VERSION ""

NS_ :

BS_:

BU_: mLEDR mLEDL TLR TLL RLR RLL HLR HLL DASCU CGW BCM

BO_ 752 BCM_Lock_CTR: 7 CGW
 SG_ BCM_AlarmOFF_Stat : 46|1@1+ (1,0) [0|1] "" Vector__XXX
 SG_ BCM_MovementSensOFF_Stat : 47|1@1+ (1,0) [0|1] "" Vector__XXX
 SG_ BCM_WindowsOpen_Req : 55|1@1+ (1,0) [0|1] "" Vector__XXX
 SG_ BCM_WindowsClose_Cmd : 37|1@1+ (1,0) [0|1] "" Vector__XXX
 SG_ BCM_TrunkLatchRelease_Req : 7|1@1+ (1,0) [0|1] "" Vector__XXX
 SG_ BCM_RRDoorClose_Req : 35|2@1+ (1,0) [0|2] "" Vector__XXX
 SG_ BCM_HoodOpen_Stat : 40|2@1+ (1,0) [0|3] ""  DASCU
 SG_ PTG_MemorySetRequest : 21|2@1+ (1,0) [0|2] "" Vector__XXX
 SG_ BCM_DoorHandleLight_Req : 54|1@1+ (1,0) [0|1] "" Vector__XXX
 SG_ BCM_VehDoubleLock_Stat : 32|1@1+ (1,0) [0|1] "" Vector__XXX
 SG_ BCM_Alarm_Req : 49|1@1+ (1,0) [0|1] "" Vector__XXX
 SG_ BCM_Alarm_Reason : 50|4@1+ (1,0) [0|10] "" Vector__XXX
 SG_ VehicleLockStateReason : 0|4@1+ (1,0) [0|11] "" Vector__XXX
 SG_ BCM_FuelLidUnlock_Req : 33|1@1+ (1,0) [0|1] "" Vector__XXX
 SG_ BCM_FRDoorClose_Req : 38|2@1+ (1,0) [0|2] "" Vector__XXX
 SG_ BCM_HVlid_Stat : 34|1@1+ (1,0) [0|1] "" Vector__XXX
 SG_ VehicleLockState : 23|1@1+ (1,0) [0|1] ""  DASCU
 SG_ BCM_RLDoorClose_Req : 43|2@1+ (1,0) [0|2] "" Vector__XXX
 SG_ BCM_FrontLeftLockCmd : 4|3@1+ (1,0) [0|3] ""  DASCU
 SG_ PTG_MovementCmd : 11|2@1+ (1,0) [0|2] "" Vector__XXX
 SG_ BCM_RearWiperWipe_Req : 45|1@1+ (1,0) [0|1] "" Vector__XXX
 SG_ BCM_FrontRightLockCmd : 8|3@1+ (1,0) [0|3] ""  DASCU
 SG_ BCM_RearLeftLockCmd : 13|3@1+ (1,0) [0|4] ""  DASCU
 SG_ BCM_PanicAlertActive : 42|1@1+ (1,0) [0|1] "" Vector__XXX
 SG_ BCM_FLDoorClose_Req : 19|2@1+ (1,0) [0|2] "" Vector__XXX
 SG_ BCM_RearRightLockCmd : 16|3@1+ (1,0) [0|4] ""  DASCU
 SG_ BCM_DoorAjarState_RR : 30|2@1+ (1,0) [0|3] "" Vector__XXX
 SG_ BCM_DoorAjarState_RL : 28|2@1+ (1,0) [0|3] "" Vector__XXX
 SG_ BCM_DoorAjarState_FR : 26|2@1+ (1,0) [0|3] "" Vector__XXX
 SG_ BCM_DoorAjarState_FL : 24|2@1+ (1,0) [0|3] "" Vector__XXX
 SG_ BCM_DoorMovDis_Stat : 48|1@1+ (1,0) [0|1] "" Vector__XXX

BO_ 866 BCM_IC_Info_Msg: 8 CGW
 SG_ BCM_EngStartNotif_Stat : 2|1@1+ (1,0) [0|0] "" Vector__XXX
 SG_ BCM_SRoofManipulationWarn_Req : 55|1@1+ (1,0) [0|1] "" Vector__XXX
 SG_ BCM_RearRight_FogLight_Status : 13|1@1+ (1,0) [0|1] "" Vector__XXX
 SG_ BCM_RearLeft_FogLight_Status : 12|1@1+ (1,0) [0|1] "" Vector__XXX
 SG_ BCM_LvBat1_SOC_Pct : 40|7@1+ (1,0) [0|100] "%" Vector__XXX
 SG_ BCM_TrunkLidOpenWarn_Req : 47|1@1+ (1,0) [0|1] "" Vector__XXX
 SG_ BCM_FuelLvl_HMI : 48|7@1+ (1,0) [0|100] "%" Vector__XXX
 SG_ BCM_LvBatCharging_Stat : 1|1@1+ (1,0) [0|1] "" Vector__XXX
 SG_ BCM_TurnIndicatorRR_Status : 29|1@1+ (1,0) [0|1] "" Vector__XXX
 SG_ BCM_DaytimeLightRight_Status : 19|1@1+ (1,0) [0|1] "" Vector__XXX
 SG_ BCM_TurnIndicatorRL_Status : 28|1@1+ (1,0) [0|1] "" Vector__XXX
 SG_ BCM_LvBat1_SOH : 36|2@1+ (1,0) [0|2] "" Vector__XXX
 SG_ BCM_TurnIndicatorMR_Status : 27|1@1+ (1,0) [0|1] "" Vector__XXX
 SG_ BCM_WarningInd : 21|1@1+ (1,0) [0|1] "" Vector__XXX
 SG_ BCM_PosLightFR_status : 25|1@1+ (1,0) [0|1] "" Vector__XXX
 SG_ BCM_TurnIndicatorFL_Status : 30|1@1+ (1,0) [0|1] "" Vector__XXX
 SG_ BCM_ReverseLightsRight_Status : 11|1@1+ (1,0) [0|1] "" Vector__XXX
 SG_ BCM_PositionLight_RL_Status : 17|1@1+ (1,0) [0|1] "" Vector__XXX
 SG_ BCM_HeadLghtLevelinglFailure : 32|1@1+ (1,0) [0|1] "" Vector__XXX
 SG_ BCM_BrakeLightLeft_Status : 6|1@1+ (1,0) [0|1] "" Vector__XXX
 SG_ BCM_ReverseLightsLeft_Status : 14|1@1+ (1,0) [0|1] "" Vector__XXX
 SG_ BCM_AdaptiveLghtsFailure : 5|1@1+ (1,0) [0|1] "" Vector__XXX
 SG_ BCM_DisplayBcgrndIntensityRef : 56|8@1+ (0.394,0) [0|100.47] "%" Vector__XXX
 SG_ BCM_CorneringLightRight_Status : 22|1@1+ (1,0) [0|1] "" Vector__XXX
 SG_ BCM_LvBat1_SOC : 34|2@1+ (1,0) [0|3] "" Vector__XXX
 SG_ BCM_PowerSteeringCtrlFault : 33|1@1+ (1,0) [0|1] "" Vector__XXX
 SG_ BCM_CalSteeringWhColumnReq : 4|1@1+ (1,0) [0|1] "" Vector__XXX
 SG_ BCM_LowBeamLeft_Status : 9|1@1+ (1,0) [0|1] "" Vector__XXX
 SG_ BCM_BrakeLightRight_Status : 7|1@1+ (1,0) [0|1] "" Vector__XXX
 SG_ BCM_CorneringLightLeft_Status : 23|1@1+ (1,0) [0|1] "" Vector__XXX
 SG_ BCM_ExteriorSystemStatus : 39|1@1+ (1,0) [0|1] "" Vector__XXX
 SG_ BCM_TurnIndicatorML_Status : 26|1@1+ (1,0) [0|1] "" Vector__XXX
 SG_ BCM_LowBeamRight_Status : 10|1@1+ (1,0) [0|1] "" Vector__XXX
 SG_ BCM_TurnIndicatorFR_Status : 31|1@1+ (1,0) [0|1] "" Vector__XXX
 SG_ BCM_DaytimeLightLeft_Status : 20|1@1+ (1,0) [0|1] "" Vector__XXX
 SG_ BCM_AllWthrLght_Fault : 8|1@1+ (1,0) [0|1] "" Vector__XXX
 SG_ BCM_HighBeamAutoStatus : 38|1@1+ (1,0) [0|1] "" Vector__XXX
 SG_ BCM_HighBeamRight_Status : 16|1@1+ (1,0) [0|1] "" Vector__XXX
 SG_ BCM_HighBeamLeft_Status : 15|1@1+ (1,0) [0|1] "" Vector__XXX
 SG_ BCM_PosLightFL_status : 24|1@1+ (1,0) [0|1] "" Vector__XXX
 SG_ BCM_WasherFluidLevel : 0|1@1+ (1,0) [0|1] ""  DASCU
 SG_ BCM_PositionLight_RR_Status : 18|1@1+ (1,0) [0|1] "" Vector__XXX

BO_ 869 BCM_CLIMATIC_DATA: 6 CGW
 SG_ SolarSensLeftVal : 16|8@1+ (4.01575,0) [0|1024.01625] "W/qm"  DASCU
 SG_ RearWindowHeating_Status : 10|1@1+ (1,0) [0|1] "" Vector__XXX
 SG_ BCM_SideWindowType_Stat : 27|1@1+ (1,0) [0|1] "" Vector__XXX
 SG_ BCM_MirrorHeating_Cmd : 28|1@1+ (1,0) [0|1] "" Vector__XXX
 SG_ BCM_WindowWashingSt : 29|1@1+ (1,0) [0|1] "" Vector__XXX
 SG_ BCM_WipeLowTempWarn_Req : 8|1@1+ (1,0) [0|1] "" Vector__XXX
 SG_ RainDensity : 31|1@1+ (1,0) [0|1] ""  DASCU
 SG_ WindshieldTemp : 32|8@1+ (0.5,-40) [-40|87.5] "°C"  DASCU
 SG_ RainDetected : 15|1@1+ (1,0) [0|1] ""  DASCU
 SG_ BCM_RearWindowHeating_Cmd : 13|1@1+ (1,0) [0|1] "" Vector__XXX
 SG_ BCM_Wiper_Stat : 26|1@1+ (1,0) [0|1] ""  DASCU
 SG_ SolarSensRightVal : 0|8@1+ (4.01575,0) [0|1024.01625] "W/qm"  DASCU
 SG_ BCM_GloveBox_Stat : 30|1@1+ (1,0) [0|1] "" Vector__XXX
 SG_ WindshieldHumidity : 40|8@1+ (0.5,0) [0|100] "%"  DASCU
 SG_ FrontWindowHeating_Status : 9|1@1+ (1,0) [0|1] ""  DASCU
 SG_ SideWindowHeating_Status : 24|1@1+ (1,0) [0|1] "" Vector__XXX
 SG_ SWM_Heating_Req : 11|2@1+ (1,0) [0|3] "" Vector__XXX

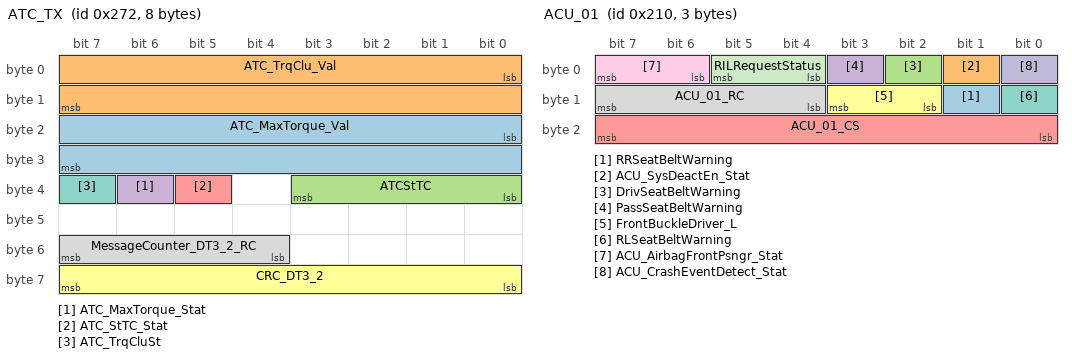
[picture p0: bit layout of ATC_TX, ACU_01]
BO_ 626 ATC_TX: 8 CGW
 SG_ ATC_MaxTorque_Val : 16|16@1+ (0.25,-8192) [-8192|8191] "Nm"  DASCU
 SG_ ATC_TrqClu_Val : 0|16@1+ (0.25,-8192) [-8192|8191] "Nm"  DASCU
 SG_ ATCStTC : 32|4@1+ (1,0) [0|15] ""  DASCU
 SG_ ATC_MaxTorque_Stat : 38|1@1+ (1,0) [0|1] "" Vector__XXX
 SG_ ATC_StTC_Stat : 37|1@1+ (1,0) [0|1] "" Vector__XXX
 SG_ CRC_DT3_2 : 56|8@1+ (1,0) [0|255] ""  DASCU
 SG_ ATC_TrqCluSt : 39|1@1+ (1,0) [0|1] ""  DASCU
 SG_ MessageCounter_DT3_2_RC : 52|4@1+ (1,0) [0|15] ""  DASCU

BO_ 1421 FIU_ADAS_Config: 8 CGW
 SG_ FIU_SettRDAAutoBrake_Req : 8|1@1+ (1,0) [0|1] ""  DASCU,CGW
 SG_ FIU_SettLCCMode_Req : 36|2@1+ (1,0) [0|3] ""  DASCU
 SG_ FIU_SettRDAsts_Req : 2|1@1+ (1,0) [0|1] ""  DASCU
 SG_ FIU_SettCCMode_Req : 26|2@1+ (1,0) [0|3] ""  DASCU
 SG_ FIU_SettSensCleanSts_Req : 55|1@1+ (1,0) [0|1] ""  DASCU
 SG_ FIU_SettLCCSoundAlert_Req : 19|1@1+ (1,0) [0|1] ""  DASCU
 SG_ FIU_SettAEBSts_Req : 14|1@1+ (1,0) [0|1] ""  DASCU
 SG_ FIU_SettDOWSts_Req : 21|1@1+ (1,0) [0|1] ""  DASCU
 SG_ FIU_SettAebFcwVibration_Req : 13|1@1+ (1,0) [0|1] ""  DASCU
 SG_ FIU_SettLDPSts_Req : 28|1@1+ (1,0) [0|1] ""  DASCU
 SG_ FIU_SettRecFileSize_Req : 40|2@1+ (1,0) [0|3] ""  DASCU
 SG_ FIU_SettLDWMode_Req : 34|2@1+ (1,0) [0|2] ""  DASCU
 SG_ FIU_SettRecResol_Req : 24|2@1+ (1,0) [0|2] ""  DASCU
 SG_ FIU_SettAebFcwMode_Req : 38|2@1+ (1,0) [0|3] ""  DASCU
 SG_ FIU_SettLDWVibration_Req : 16|1@1+ (1,0) [0|1] ""  DASCU
 SG_ FIU_SettRCTCsts_Req : 3|1@1+ (1,0) [0|1] ""  DASCU
 SG_ FIU_SettASLAOver_Req : 42|6@1+ (1,-1) [0|60] "Km/h"  DASCU
 SG_ FIU_SettCCType_Req : 52|3@1+ (1,0) [0|4] ""  DASCU
 SG_ FIU_SettALCCSts_Req : 20|1@1+ (1,0) [0|1] ""  DASCU
 SG_ FIU_SettDOWSoundAlert_Req : 22|1@1+ (1,0) [0|1] ""  DASCU
 SG_ FIU_SettRecSts_Req : 12|1@1+ (1,0) [0|1] ""  DASCU
 SG_ FIU_StartSet_Req : 0|1@1+ (1,0) [0|1] ""  DASCU
 SG_ FIU_SettLCCSts_Req : 15|1@1+ (1,0) [0|1] ""  DASCU
 SG_ FIU_SettAFSsts_Req : 31|1@1+ (1,0) [0|1] ""  DASCU
 SG_ FIU_SettAAmode_Req : 32|2@1+ (1,0) [0|2] ""  DASCU
 SG_ FIU_SettFCWSts_Req : 10|1@1+ (1,0) [0|1] ""  DASCU
 SG_ FIU_SettCCSpdCorrect_Req : 6|1@1+ (1,0) [0|1] ""  DASCU
 SG_ FIU_SettLKASts_Req : 9|1@1+ (1,0) [0|1] ""  DASCU
 SG_ FIU_SettLCCVibration_Req : 18|1@1+ (1,0) [0|1] ""  DASCU
 SG_ FIU_SettLDWSts_Req : 23|1@1+ (1,0) [0|1] ""  DASCU
 SG_ FIU_SettASLASts_Req : 7|1@1+ (1,0) [0|1] ""  DASCU
 SG_ FIU_SettAAsts_Req : 30|1@1+ (1,0) [0|1] ""  DASCU
 SG_ FIU_SettTSRsts_Req : 29|1@1+ (1,0) [0|1] ""  DASCU
 SG_ FIU_SettLDWSoundAlert_Req : 17|1@1+ (1,0) [0|1] ""  DASCU

BO_ 528 ACU_01: 3 CGW
 SG_ RRSeatBeltWarning : 9|1@1+ (1,0) [0|1] ""  DASCU
 SG_ ACU_SysDeactEn_Stat : 1|1@1+ (1,0) [0|1] "" Vector__XXX
 SG_ DrivSeatBeltWarning : 2|1@1+ (1,0) [0|1] ""  DASCU
 SG_ PassSeatBeltWarning : 3|1@1+ (1,0) [0|1] ""  DASCU
 SG_ ACU_01_CS : 16|8@1+ (1,0) [0|255] ""  DASCU
 SG_ FrontBuckleDriver_L : 10|2@1+ (1,0) [0|3] ""  DASCU
 SG_ RLSeatBeltWarning : 8|1@1+ (1,0) [0|1] ""  DASCU
 SG_ ACU_01_RC : 12|4@1+ (1,0) [0|15] ""  DASCU
 SG_ ACU_AirbagFrontPsngr_Stat : 6|2@1+ (1,0) [0|3] "" Vector__XXX
 SG_ ACU_CrashEventDetect_Stat : 0|1@1+ (1,0) [0|1] ""  DASCU
 SG_ RILRequestStatus : 4|2@1+ (1,0) [0|3] "" Vector__XXX

BO_ 256 ESC_04: 8 CGW
 SG_ ESC_CDPDecelActive : 24|1@1+ (1,0) [0|1] "" Vector__XXX
 SG_ ESC_BLS_Fault : 25|1@1+ (1,0) [0|1] "" Vector__XXX
 SG_ ESC_PEBWarningLampReq : 39|1@1+ (1,0) [0|1] "" Vector__XXX
 SG_ ESC_04_CS : 56|8@1+ (1,0) [0|255] ""  DASCU
 SG_ ESC_HDC_rejected : 34|1@1+ (1,0) [0|1] "" Vector__XXX
 SG_ ESC_CtlActiveTcs : 28|1@1+ (1,0) [0|1] ""  DASCU
 SG_ ESC_CtlActiveAbs : 26|1@1+ (1,0) [0|1] ""  DASCU
 SG_ ESC_Bls_Out : 19|1@1+ (1,0) [0|1] ""  DASCU
 SG_ ESC_HDC_Activated : 32|1@1+ (1,0) [0|1] ""  DASCU
 SG_ ESC_ABS_Lamp : 21|1@1+ (1,0) [0|1] "" Vector__XXX
 SG_ ESC_EBD_Lamp : 22|1@1+ (1,0) [0|1] "" Vector__XXX
 SG_ ESC_Lamp : 17|1@1+ (1,0) [0|1] "" Vector__XXX
 SG_ ESC_RequestToEPB : 36|2@1+ (1,0) [0|3] "" Vector__XXX
 SG_ ESC_TCS_Fault : 23|1@1+ (1,0) [0|1] "" Vector__XXX
 SG_ ESC_AVH_Active : 18|1@1+ (1,0) [0|1] "" Vector__XXX
 SG_ ESC_CDPDecelAvailable : 38|1@1+ (1,0) [0|1] "" Vector__XXX
 SG_ ESC_CtlActiveHDC : 33|1@1+ (1,0) [0|1] "" Vector__XXX
 SG_ ESC_CtlActiveEbd : 27|1@1+ (1,0) [0|1] ""  DASCU
 SG_ ESC_Passive_Lamp : 30|1@1+ (1,0) [0|1] "" Vector__XXX
 SG_ ESC_CtlActiveVdc : 29|1@1+ (1,0) [0|1] ""  DASCU
 SG_ ESC_EmergencyBraking : 35|1@1+ (1,0) [0|1] "" Vector__XXX
 SG_ ESC_VehicleSpeed_ValueError : 16|1@1+ (1,0) [0|1] ""  DASCU
 SG_ ESC_04_RC : 52|4@1+ (1,0) [0|15] ""  DASCU
 SG_ ESC_Bla : 20|1@1+ (1,0) [0|1] ""  DASCU
 SG_ ESC_VehicleSpeed : 0|16@1+ (0.01,0) [0|655.34] "km/h"  DASCU
 SG_ CddActive_2 : 48|1@1+ (1,0) [0|1] "" Vector__XXX
 SG_ ESC_Gearshift_Inhibit : 31|1@1+ (1,0) [0|1] "" Vector__XXX
 SG_ ESC_HDC_SpeedLimit : 40|8@1+ (1,0) [0|255] "km/h" Vector__XXX

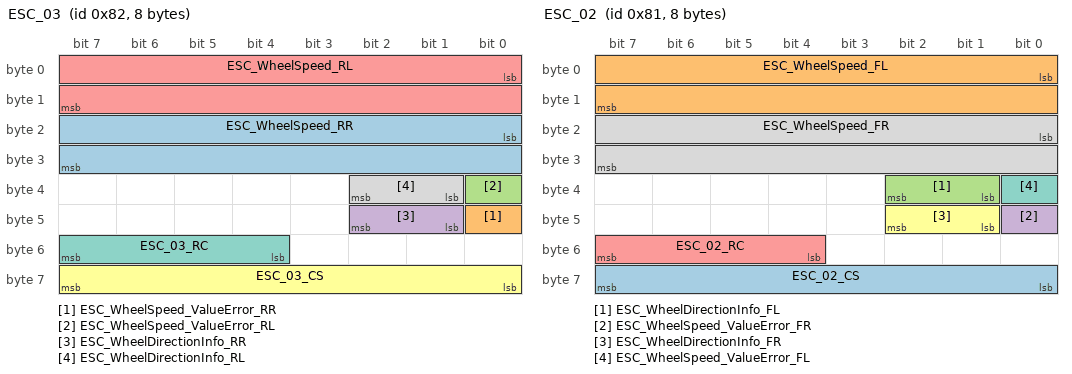
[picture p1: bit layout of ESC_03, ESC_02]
BO_ 130 ESC_03: 8 CGW
 SG_ ESC_WheelSpeed_RR : 16|16@1+ (0.01,0) [0|655.34] "km/h"  DASCU
 SG_ ESC_WheelSpeed_ValueError_RR : 40|1@1+ (1,0) [0|1] ""  DASCU
 SG_ ESC_WheelSpeed_ValueError_RL : 32|1@1+ (1,0) [0|1] ""  DASCU
 SG_ ESC_WheelDirectionInfo_RR : 41|2@1+ (1,0) [0|3] "" Vector__XXX
 SG_ ESC_WheelSpeed_RL : 0|16@1+ (0.01,0) [0|655.34] "km/h"  DASCU
 SG_ ESC_03_CS : 56|8@1+ (1,0) [0|255] ""  DASCU
 SG_ ESC_03_RC : 52|4@1+ (1,0) [0|15] ""  DASCU
 SG_ ESC_WheelDirectionInfo_RL : 33|2@1+ (1,0) [0|3] "" Vector__XXX

BO_ 129 ESC_02: 8 CGW
 SG_ ESC_02_CS : 56|8@1+ (1,0) [0|255] ""  DASCU
 SG_ ESC_WheelSpeed_FL : 0|16@1+ (0.01,0) [0|655.34] "km/h"  DASCU
 SG_ ESC_WheelDirectionInfo_FL : 33|2@1+ (1,0) [0|3] ""  DASCU
 SG_ ESC_WheelSpeed_ValueError_FR : 40|1@1+ (1,0) [0|1] ""  DASCU
 SG_ ESC_02_RC : 52|4@1+ (1,0) [0|15] ""  DASCU
 SG_ ESC_WheelDirectionInfo_FR : 41|2@1+ (1,0) [0|3] ""  DASCU
 SG_ ESC_WheelSpeed_ValueError_FL : 32|1@1+ (1,0) [0|1] ""  DASCU
 SG_ ESC_WheelSpeed_FR : 16|16@1+ (0.01,0) [0|655.34] "km/h"  DASCU

BO_ 2015 Diag_Functional: 8 CGW
 SG_ Diag_Functional_Sig : 7|64@0+ (1,0) [0|1.84467440737096E+019] ""  HLL,HLR,mLEDL,mLEDR,RLL,RLR,TLL,TLR,DASCU

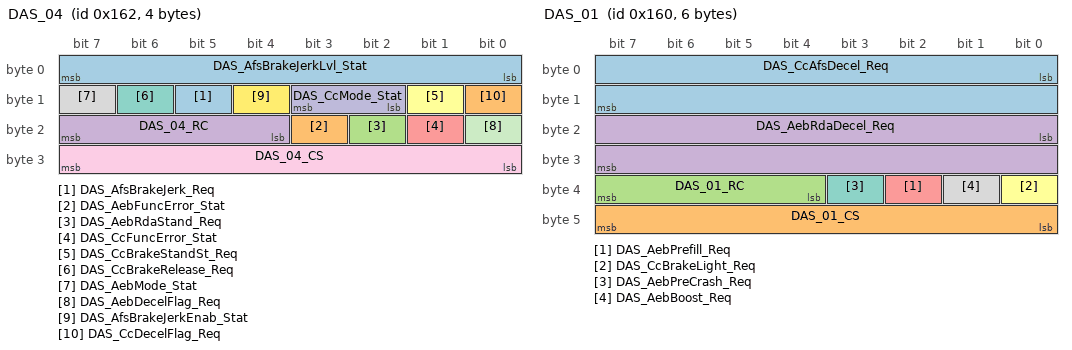
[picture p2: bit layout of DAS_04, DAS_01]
BO_ 354 DAS_04: 4 DASCU
 SG_ DAS_AfsBrakeJerk_Req : 13|1@1+ (1,0) [0|1] ""  CGW
 SG_ DAS_AebFuncError_Stat : 19|1@1+ (1,0) [0|1] ""  BCM,CGW
 SG_ DAS_AebRdaStand_Req : 18|1@1+ (1,0) [0|1] ""  CGW
 SG_ DAS_04_RC : 20|4@1+ (1,0) [0|15] ""  CGW
 SG_ DAS_CcFuncError_Stat : 17|1@1+ (1,0) [0|1] ""  CGW
 SG_ DAS_CcBrakeStandSt_Req : 9|1@1+ (1,0) [0|1] ""  CGW
 SG_ DAS_CcBrakeRelease_Req : 14|1@1+ (1,0) [0|1] ""  CGW
 SG_ DAS_AebMode_Stat : 15|1@1+ (1,0) [0|1] ""  CGW
 SG_ DAS_04_CS : 24|8@1+ (1,0) [0|255] ""  CGW
 SG_ DAS_CcMode_Stat : 10|2@1+ (1,0) [0|3] ""  BCM,CGW
 SG_ DAS_AebDecelFlag_Req : 16|1@1+ (1,0) [0|1] ""  CGW
 SG_ DAS_AfsBrakeJerkEnab_Stat : 12|1@1+ (1,0) [0|1] ""  CGW
 SG_ DAS_AfsBrakeJerkLvl_Stat : 0|8@1+ (1,0) [0|255] ""  CGW
 SG_ DAS_CcDecelFlag_Req : 8|1@1+ (1,0) [0|1] ""  CGW

BO_ 522 DAS_02: 8 DASCU
 SG_ DAS_LkaSteeringMode_Stat : 20|1@1+ (1,0) [0|1] ""  CGW
 SG_ DAS_RctcDecelFlag_Req : 23|1@1+ (1,0) [0|1] ""  CGW
 SG_ DAS_AccFuncError_Stat : 26|1@1+ (1,0) [0|1] ""  CGW
 SG_ DAS_RctcNotifError_Req : 25|1@1+ (1,0) [0|1] ""  CGW
 SG_ DAS_RctcFuncError_Stat : 24|1@1+ (1,0) [0|1] ""  CGW
 SG_ DAS_RctcMode_Stat : 22|1@1+ (1,0) [0|1] ""  CGW
 SG_ DAS_AfsNotifError_Req : 21|1@1+ (1,0) [0|1] ""  CGW
 SG_ DAS_ApaFuncError_Stat : 28|1@1+ (1,0) [0|1] "" Vector__XXX
 SG_ DAS_APAMode_Stat : 27|1@1+ (1,0) [0|1] "" Vector__XXX
 SG_ DAS_RsaAngleDirection_Req : 46|2@1+ (1,0) [0|3] "" Vector__XXX
 SG_ DAS_02_RC : 52|4@1+ (1,0) [0|15] ""  CGW
 SG_ DAS_LdpMode_Stat : 14|1@1+ (1,0) [0|1] ""  CGW
 SG_ DAS_02_CS : 56|8@1+ (1,0) [0|255] ""  CGW
 SG_ DAS_LkaAngleFlag_Req : 0|1@1+ (1,0) [0|1] ""  CGW
 SG_ DAS_AfsDecelFlag_Req : 2|1@1+ (1,0) [0|1] ""  CGW
 SG_ DAS_AlccMode_Stat : 17|1@1+ (1,0) [0|1] ""  CGW
 SG_ DAS_AfsFuncError_Stat : 3|1@1+ (1,0) [0|1] ""  CGW,BCM
 SG_ DAS_LdwFuncError_Stat : 15|1@1+ (1,0) [0|1] ""  CGW
 SG_ DAS_AfsSos_Req : 5|1@1+ (1,0) [0|1] ""  CGW
 SG_ DAS_LkaMode_Stat : 10|2@1+ (1,0) [0|3] ""  CGW
 SG_ DAS_RdaMode_Stat : 7|1@1+ (1,0) [0|1] ""  CGW
 SG_ DAS_AlccAngleFlag_Req : 16|1@1+ (1,0) [0|1] ""  CGW
 SG_ DAS_AfsEpb_Req : 6|1@1+ (1,0) [0|1] ""  CGW
 SG_ DAS_AfsMode_Stat : 1|1@1+ (1,0) [0|1] ""  CGW
 SG_ DAS_LkaAngle_Req : 32|14@1+ (0.1,-819.1) [-819.1|819.1] ""  CGW
 SG_ DAS_LccFuncError_Stat : 18|1@1+ (1,0) [0|1] ""  CGW
 SG_ DAS_RdaDecelFlag_Req : 8|1@1+ (1,0) [0|1] ""  CGW
 SG_ DAS_AfsExecute_Req : 4|1@1+ (1,0) [0|1] ""  CGW,BCM
 SG_ DAS_RdaFuncError_Stat : 9|1@1+ (1,0) [0|1] ""  CGW
 SG_ DAS_LkaFuncError_Stat : 12|1@1+ (1,0) [0|1] ""  CGW
 SG_ DAS_LdpAngleFlag_Req : 13|1@1+ (1,0) [0|1] ""  CGW
 SG_ DAS_ApaAngleFlag_Req : 19|1@1+ (1,0) [0|1] "" Vector__XXX

BO_ 352 DAS_01: 6 DASCU
 SG_ DAS_CcAfsDecel_Req : 0|16@1+ (0.001,-20) [-20|20] "m/s^2"  CGW
 SG_ DAS_01_CS : 40|8@1+ (1,0) [0|255] ""  BCM,CGW
 SG_ DAS_01_RC : 36|4@1+ (1,0) [0|15] ""  BCM,CGW
 SG_ DAS_AebRdaDecel_Req : 16|16@1+ (0.001,-20) [-20|20] "m/s^2"  CGW
 SG_ DAS_AebPrefill_Req : 34|1@1+ (1,0) [0|1] ""  CGW
 SG_ DAS_CcBrakeLight_Req : 32|1@1+ (1,0) [0|1] ""  BCM,CGW
 SG_ DAS_AebPreCrash_Req : 35|1@1+ (1,0) [0|1] ""  BCM,CGW
 SG_ DAS_AebBoost_Req : 33|1@1+ (1,0) [0|1] ""  CGW

BO_ 658 DASCU_Proj: 12 DASCU
 SG_ DAS_LeftProjBrightSlot1_Req : 16|3@1+ (1,0) [0|7] ""  mLEDL
 SG_ DAS_LeftProjSlot1_Req : 0|7@1+ (1,0) [0|101] ""  mLEDL
 SG_ DAS_LeftProjSlot4_Req : 43|4@1+ (1,0) [0|15] ""  mLEDL
 SG_ DAS_RightProjBrightSlot3_Req : 56|3@1+ (1,0) [0|7] ""  mLEDR
 SG_ DAS_RightProjSlot3_Req : 59|4@1+ (1,0) [0|15] ""  mLEDR
 SG_ DAS_RightProjBrightSlot4_Req : 64|3@1+ (1,0) [0|7] ""  mLEDR
 SG_ DAS_LeftProjBrightSlot3_Req : 32|3@1+ (1,0) [0|7] ""  mLEDL
 SG_ DAS_LeftProjBrightSlot2_Req : 24|3@1+ (1,0) [0|7] ""  mLEDL
 SG_ DAS_RightProjBrightSlot2_Req : 48|3@1+ (1,0) [0|7] ""  mLEDR
 SG_ DAS_LeftProjSlot3_Req : 35|4@1+ (1,0) [0|15] ""  mLEDL
 SG_ DAS_RightProjSlot1_Req : 8|7@1+ (1,0) [0|65] ""  mLEDR
 SG_ DAS_LeftProjSlot2_Req : 27|4@1+ (1,0) [0|15] ""  mLEDL
 SG_ DAS_LeftProjBrightSlot4_Req : 40|3@1+ (1,0) [0|7] ""  mLEDL
 SG_ DAS_RightProjSlot4_Req : 67|4@1+ (1,0) [0|15] ""  mLEDR
 SG_ DAS_RightProjBrightSlot1_Req : 19|3@1+ (1,0) [0|7] ""  mLEDR
 SG_ DAS_RightProjSlot2_Req : 51|4@1+ (1,0) [0|15] ""  mLEDR

BO_ 657 DASCU_HLR_Object: 64 DASCU
 SG_ DAS_RightObj_1_Y_2_Val : 40|9@1+ (1,0) [0|321] ""  mLEDR
 SG_ DAS_RightObj_3_Y_2_Val : 104|9@1+ (1,0) [0|321] ""  mLEDR
 SG_ DAS_ADBRightLED5_Req : 8|1@1+ (1,0) [0|1] ""  HLR
 SG_ DAS_ADBRightLED1_Req : 4|1@1+ (1,0) [0|1] ""  HLR
 SG_ DAS_RightObj_5_Z_2_Val : 177|7@1+ (1,0) [0|81] ""  mLEDR
 SG_ DAS_RightObj_7_Z_2_Val : 241|7@1+ (1,0) [0|81] ""  mLEDR
 SG_ DAS_RightObj_9_Z_2_Val : 305|7@1+ (1,0) [0|81] ""  mLEDR
 SG_ DAS_RightObj_8_Y_1_Val : 248|9@1+ (1,0) [0|321] ""  mLEDR
 SG_ DAS_ADBRightLED6_Req : 9|1@1+ (1,0) [0|1] ""  HLR
 SG_ DAS_RightObj_9_Y_2_Val : 296|9@1+ (1,0) [0|321] ""  mLEDR
 SG_ DAS_ADBRightLED10_Req : 13|1@1+ (1,0) [0|1] ""  HLR
 SG_ DAS_ADBRightLED16_Req : 19|1@1+ (1,0) [0|1] ""  HLR
 SG_ DAS_ADBRightLED11_Req : 14|1@1+ (1,0) [0|1] ""  HLR
 SG_ DAS_RightObj_10_Y_2_Val : 328|9@1+ (1,0) [0|321] ""  mLEDR
 SG_ DAS_RightObj_10_Z_2_Val : 337|7@1+ (1,0) [0|81] ""  mLEDR
 SG_ DAS_RightObj_3_Z_2_Val : 113|7@1+ (1,0) [0|81] ""  mLEDR
 SG_ DAS_RightObj_4_Y_1_Val : 120|9@1+ (1,0) [0|321] ""  mLEDR
 SG_ DAS_RightObj_8_Z_1_Val : 257|7@1+ (1,0) [0|81] ""  mLEDR
 SG_ DAS_RightObj_6_Z_2_Val : 209|7@1+ (1,0) [0|81] ""  mLEDR
 SG_ DAS_ADBRightLED12_Req : 15|1@1+ (1,0) [0|1] ""  HLR
 SG_ DAS_HLR_Object_CS : 384|8@1+ (1,0) [0|255] ""  HLR,mLEDR
 SG_ DAS_ADBRightLED15_Req : 18|1@1+ (1,0) [0|1] ""  HLR
 SG_ DAS_RightObj_3_Z_1_Val : 97|7@1+ (1,0) [0|81] ""  mLEDR
 SG_ DAS_ADBRightLED8_Req : 11|1@1+ (1,0) [0|1] ""  HLR
 SG_ DAS_HLR_Object_RC : 379|4@1+ (1,0) [0|15] ""  HLR,mLEDR
 SG_ DAS_RightObj_7_Y_2_Val : 232|9@1+ (1,0) [0|321] ""  mLEDR
 SG_ DAS_RightObj_9_Y_1_Val : 280|9@1+ (1,0) [0|321] ""  mLEDR
 SG_ DAS_RightObj_4_Y_2_Val : 136|9@1+ (1,0) [0|321] ""  mLEDR
 SG_ DAS_RightObj_2_Z_1_Val : 65|7@1+ (1,0) [0|81] ""  mLEDR
 SG_ DAS_RightObj_7_Z_1_Val : 225|7@1+ (1,0) [0|81] ""  mLEDR
 SG_ DAS_RightObj_9_Z_1_Val : 289|7@1+ (1,0) [0|81] ""  mLEDR
 SG_ DAS_RightObj_5_Y_1_Val : 152|9@1+ (1,0) [0|321] ""  mLEDR
 SG_ DAS_RightObj_10_Z_1_Val : 321|7@1+ (1,0) [0|81] ""  mLEDR
 SG_ DAS_RightObj_8_Y_2_Val : 264|9@1+ (1,0) [0|321] ""  mLEDR
 SG_ DAS_ADBRightLED4_Req : 7|1@1+ (1,0) [0|1] ""  HLR
 SG_ DAS_RightObj_4_Z_2_Val : 145|7@1+ (1,0) [0|81] ""  mLEDR
 SG_ DAS_RightObj_6_Y_1_Val : 184|9@1+ (1,0) [0|321] ""  mLEDR
 SG_ DAS_ADBRightLED13_Req : 16|1@1+ (1,0) [0|1] ""  HLR
 SG_ DAS_RightObj_1_Y_1_Val : 24|9@1+ (1,0) [0|321] ""  mLEDR
 SG_ DAS_ADBRightLED17_Req : 20|1@1+ (1,0) [0|1] ""  HLR
 SG_ DAS_ADBRightLED9_Req : 12|1@1+ (1,0) [0|1] ""  HLR
 SG_ DAS_RightObj_6_Z_1_Val : 193|7@1+ (1,0) [0|81] ""  mLEDR
 SG_ DAS_RightObj_4_Z_1_Val : 129|7@1+ (1,0) [0|81] ""  mLEDR
 SG_ DAS_ADBRightLED18_Req : 21|1@1+ (1,0) [0|1] ""  HLR
 SG_ DAS_RightObj_1_Z_1_Val : 33|7@1+ (1,0) [0|81] ""  mLEDR
 SG_ DAS_ADBRightLED7_Req : 10|1@1+ (1,0) [0|1] ""  HLR
 SG_ DAS_RightObj_8_Z_2_Val : 273|7@1+ (1,0) [0|81] ""  mLEDR
 SG_ DAS_RightObj_2_Z_2_Val : 81|7@1+ (1,0) [0|81] ""  mLEDR
 SG_ DAS_RightObj_3_Y_1_Val : 88|9@1+ (1,0) [0|321] ""  mLEDR
 SG_ DAS_ADBRightLED3_Req : 6|1@1+ (1,0) [0|1] ""  HLR
 SG_ DAS_RightObj_6_Y_2_Val : 200|9@1+ (1,0) [0|321] ""  mLEDR
 SG_ DAS_RightObj_5_Z_1_Val : 161|7@1+ (1,0) [0|81] ""  mLEDR
 SG_ DAS_RightObj_5_Y_2_Val : 168|9@1+ (1,0) [0|321] ""  mLEDR
 SG_ DAS_ADBRightLED2_Req : 5|1@1+ (1,0) [0|1] ""  HLR
 SG_ DAS_ADBRightLED14_Req : 17|1@1+ (1,0) [0|1] ""  HLR
 SG_ DAS_RightObj_2_Y_1_Val : 56|9@1+ (1,0) [0|321] ""  mLEDR
 SG_ DAS_RightObj_10_Y_1_Val : 312|9@1+ (1,0) [0|321] ""  mLEDR
 SG_ DAS_RightObj_1_Z_2_Val : 49|7@1+ (1,0) [0|81] ""  mLEDR
 SG_ DAS_RightObj_2_Y_2_Val : 72|9@1+ (1,0) [0|321] ""  mLEDR
 SG_ DAS_RightObj_7_Y_1_Val : 216|9@1+ (1,0) [0|321] ""  mLEDR

CM_ SG_ 752 BCM_AlarmOFF_Stat "Disabling alarm system";
CM_ SG_ 752 BCM_MovementSensOFF_Stat "State of movement sensor actvation";
CM_ SG_ 752 BCM_WindowsOpen_Req "The BCM shall command to Open the windows, when user request is detect.";
CM_ SG_ 752 BCM_WindowsClose_Cmd "The BCM shall command to Close  the windows, when user request is detect.";
CM_ SG_ 752 BCM_TrunkLatchRelease_Req "Indicates whether the trunk latch is commanded to be released or not";
CM_ SG_ 752 BCM_RRDoorClose_Req "Command to control RR door opening/ closing";
CM_ SG_ 752 BCM_HoodOpen_Stat "Current status of hood";
CM_ SG_ 752 PTG_MemorySetRequest "Request of storing or clearing the power tailgate position in memory:
$0 = No Action
$1 = Store memory
$2 = Clear memory";
CM_ SG_ 752 BCM_DoorHandleLight_Req "Command to control exterior door handle lights";
CM_ SG_ 752 BCM_VehDoubleLock_Stat "Vehicle secure locking status";
CM_ SG_ 752 BCM_Alarm_Req "Indicates if at least one alarm reason active or not";
CM_ SG_ 752 BCM_Alarm_Reason "Reason of vehicle alarm function actuation";
CM_ SG_ 752 VehicleLockStateReason "Reason of vehicle lock state";
CM_ SG_ 752 BCM_FuelLidUnlock_Req "Fuel (gasoline or hydrogen) and high-voltage lid unlock command";
CM_ SG_ 752 BCM_FRDoorClose_Req "Current command to control movement of FR door ";
CM_ SG_ 752 BCM_HVlid_Stat "HV lid open status";
CM_ SG_ 752 VehicleLockState "State of vehicle side doors and trunk locks: locked or unlocked";
CM_ SG_ 752 BCM_RLDoorClose_Req "Command to control RL door opening/ closing";
CM_ SG_ 752 BCM_FrontLeftLockCmd "$0 = NO_ACTION
$1 = UNLOCK
$2 = LOCK
$3 = SECURE_LOCK
$4 = UNSECURE_LOCK";
CM_ SG_ 752 PTG_MovementCmd "Indicates the power tailgate movement command:
0x0 = Stop
0x1 = Open
0x2 = Close";
CM_ SG_ 752 BCM_RearWiperWipe_Req "Indicate a rear wiper wipe request";
CM_ SG_ 752 BCM_FrontRightLockCmd "$0 = NO_ACTION
$1 = UNLOCK
$2 = LOCK
$3 = SECURE_LOCK
$4 = UNSECURE_LOCK";
CM_ SG_ 752 BCM_RearLeftLockCmd "$0 = NO_ACTION
$1 = UNLOCK
$2 = LOCK
$3 = SECURE_LOCK
$4 = UNSECURE_LOCK";
CM_ SG_ 752 BCM_PanicAlertActive "State of Panic Mode activation";
CM_ SG_ 752 BCM_FLDoorClose_Req "Current command to control movement of FL door ";
CM_ SG_ 752 BCM_RearRightLockCmd "$0 = NO_ACTION
$1 = UNLOCK
$2 = LOCK
$3 = SECURE_LOCK
$4 = UNSECURE_LOCK";
CM_ SG_ 752 BCM_DoorAjarState_RR "State of RR door (legacy signal";
CM_ SG_ 752 BCM_DoorAjarState_RL "State of RL door (legacy signal)";
CM_ SG_ 752 BCM_DoorAjarState_FR "The signal only for active safety system";
CM_ SG_ 752 BCM_DoorAjarState_FL "State of FL door Only for ESC.";
CM_ SG_ 752 BCM_DoorMovDis_Stat "Door movement system status";
CM_ SG_ 866 BCM_EngStartNotif_Stat "User notification to smoothly transit from “engine running in remote start” mode to “Drive” mode";
CM_ SG_ 866 BCM_SRoofManipulationWarn_Req "Indicates to user inability of open trunk lid due to soft roof control";
CM_ SG_ 866 BCM_RearRight_FogLight_Status "Error status of rear right fog light";
CM_ SG_ 866 BCM_RearLeft_FogLight_Status "Error status of rear left fog light";
CM_ SG_ 866 BCM_LvBat1_SOC_Pct "SOC of LV battery in percents";
CM_ SG_ 866 BCM_TrunkLidOpenWarn_Req "Indicates to user inability of soft roof control due to trunk lid open";
CM_ SG_ 866 BCM_FuelLvl_HMI "Fuel Level in percents";
CM_ SG_ 866 BCM_LvBatCharging_Stat "State of charging a Low Voltage Battery";
CM_ SG_ 866 BCM_TurnIndicatorRR_Status "Error status of rear right direction indicator";
CM_ SG_ 866 BCM_DaytimeLightRight_Status "Current status  of daytime running lights / position lights";
CM_ SG_ 866 BCM_TurnIndicatorRL_Status "Error status of rear left direction indicator";
CM_ SG_ 866 BCM_LvBat1_SOH "State of Health main Low Battery Voltage";
CM_ SG_ 866 BCM_TurnIndicatorMR_Status "Error status of side right direction indicator";
CM_ SG_ 866 BCM_WarningInd "Request a warning message to be displayed on IC:
$0 = No Warning
$1 = Warning requested";
CM_ SG_ 866 BCM_PosLightFR_status "Error status of front right position light";
CM_ SG_ 866 BCM_TurnIndicatorFL_Status "Error status of front left direction indicator";
CM_ SG_ 866 BCM_ReverseLightsRight_Status "Current status of reverse lights";
CM_ SG_ 866 BCM_PositionLight_RL_Status "Error status of rear left position light";
CM_ SG_ 866 BCM_HeadLghtLevelinglFailure "Indicate to the driver that the leveling system has failed
$0 = FALSE
$1 = TRUE";
CM_ SG_ 866 BCM_BrakeLightLeft_Status "Current status of brake lights";
CM_ SG_ 866 BCM_ReverseLightsLeft_Status "Current status of reverse lights";
CM_ SG_ 866 BCM_AdaptiveLghtsFailure "The failure in exterior lights,which changes the light beam when turning.";
CM_ SG_ 866 BCM_DisplayBcgrndIntensityRef "Indicates to IC the background intensity for display selected by the user.
IC receives it, processes based on a table and a light sensor then sends to FIU the DisplayBacllightBrightness applied.";
CM_ SG_ 866 BCM_CorneringLightRight_Status "Current status of cornering lights";
CM_ SG_ 866 BCM_LvBat1_SOC "State of Charge main Low Battery Voltage";
CM_ SG_ 866 BCM_PowerSteeringCtrlFault "Request the power steering fluid control fault indication:
$0 = No Action
$1 = Stering Fluid Control Fault";
CM_ SG_ 866 BCM_CalSteeringWhColumnReq "Request to notify user about steering whell calibration";
CM_ SG_ 866 BCM_LowBeamLeft_Status "Current status of low-beam lights";
CM_ SG_ 866 BCM_BrakeLightRight_Status "Current status of brake lights";
CM_ SG_ 866 BCM_CorneringLightLeft_Status "Current status of cornering lights";
CM_ SG_ 866 BCM_ExteriorSystemStatus "General failure of exterior light system";
CM_ SG_ 866 BCM_TurnIndicatorML_Status "Error status of side left direction indicator";
CM_ SG_ 866 BCM_LowBeamRight_Status "Current status of low-beam lights";
CM_ SG_ 866 BCM_TurnIndicatorFR_Status "Error status of front right direction indicator";
CM_ SG_ 866 BCM_DaytimeLightLeft_Status "Current status  of daytime running lights / position lights";
CM_ SG_ 866 BCM_AllWthrLght_Fault "Error status of all-weather function";
CM_ SG_ 866 BCM_HighBeamAutoStatus "State of availability auto high beam function";
CM_ SG_ 866 BCM_HighBeamRight_Status "Current status of high-beam lights";
CM_ SG_ 866 BCM_HighBeamLeft_Status "Current status of high-beam lights";
CM_ SG_ 866 BCM_PosLightFL_status "Error status of front left position light";
CM_ SG_ 866 BCM_WasherFluidLevel "Washer Fluid Level";
CM_ SG_ 866 BCM_PositionLight_RR_Status "Error status of rear right position light";
CM_ SG_ 869 SolarSensLeftVal "Solar radiation value from left sensor";
CM_ SG_ 869 RearWindowHeating_Status "State of rear window heating";
CM_ SG_ 869 BCM_SideWindowType_Stat "Indicates side window heaters installed on vehicle or not";
CM_ SG_ 869 BCM_MirrorHeating_Cmd "Request to on/off outside miror heating";
CM_ SG_ 869 BCM_WindowWashingSt "Indicates the window washer status";
CM_ SG_ 869 BCM_WipeLowTempWarn_Req "Indicates to driver: front wiper pause due to low external temperature";
CM_ SG_ 869 RainDensity "Indicates the density of rainstatus:
0x0 = Low Density
0x1 = High Density";
CM_ SG_ 869 WindshieldTemp "Temperature of front windshield zone";
CM_ SG_ 869 RainDetected "Indicates the rain detected or not";
CM_ SG_ 869 BCM_RearWindowHeating_Cmd "Request to on/off rear window heating";
CM_ SG_ 869 BCM_Wiper_Stat "Wiper status
Indicates the wiper status";
CM_ SG_ 869 SolarSensRightVal "Solar radiation value from right sensor";
CM_ SG_ 869 BCM_GloveBox_Stat "Current state of glove box (open or closed)";
CM_ SG_ 869 WindshieldHumidity "Level of humidity in front windshield zone";
CM_ SG_ 869 FrontWindowHeating_Status "State of front window heating";
CM_ SG_ 869 SideWindowHeating_Status "State of side windows heating";
CM_ SG_ 869 SWM_Heating_Req "Request to on/ off steering wheel heating";
CM_ SG_ 626 ATC_MaxTorque_Val "Maximum possible clutch torque at the center";
CM_ SG_ 626 ATC_TrqClu_Val "actual (current) coupling clutch torque at the center";
CM_ SG_ 626 ATCStTC "Clutch Status / AWD system status/Transfer case status:
0 Deactivated / DEACT (0Nm)
1 Initialization / INIT (value at ignition ON? Clutch torque 0)
2 calibration / CAL (This condition doesnt happen in vehicle running condition.)
3 normal operation / N";
CM_ SG_ 626 ATC_MaxTorque_Stat "maximum available clutch torque signal validity
$0 = Invalid signal
$1 = Valid signal";
CM_ SG_ 626 ATC_StTC_Stat "Clutch Status/ AWD system status signal validity
$0 = Invalid signal
$1 = Valid signal";
CM_ SG_ 626 CRC_DT3_2 "Checksum CRC8 SAE J1850 of the data field this message";
CM_ SG_ 626 ATC_TrqCluSt "actual clutch torque signal validity
$0 = Invalid signal
$1 = Valid signal";
CM_ SG_ 626 MessageCounter_DT3_2_RC "Rolling Counter [0 - 15]";
CM_ SG_ 1421 FIU_SettRDAAutoBrake_Req "Rear driving assistant state change request Auto Brake";
CM_ SG_ 1421 FIU_SettLCCMode_Req "Lane change control state change request";
CM_ SG_ 1421 FIU_SettRDAsts_Req "Rear driving assistant state change request";
CM_ SG_ 1421 FIU_SettCCMode_Req "Cruise control mode change request";
CM_ SG_ 1421 FIU_SettSensCleanSts_Req "Request status of sensor clean function";
CM_ SG_ 1421 FIU_SettLCCSoundAlert_Req "Lane change control sound alert function eneble/ disable change request";
CM_ SG_ 1421 FIU_SettAEBSts_Req "Automatic emergency braking state change request. Only for PHEV, BEV, PFCV";
CM_ SG_ 1421 FIU_SettDOWSts_Req "Door opening warning state change request";
CM_ SG_ 1421 FIU_SettAebFcwVibration_Req "Front collision warning tactile sensation function enable/ disable change request";
CM_ SG_ 1421 FIU_SettLDPSts_Req "Line departure prevention state change request";
CM_ SG_ 1421 FIU_SettRecFileSize_Req "RSR activation status";
CM_ SG_ 1421 FIU_SettLDWMode_Req "Line departure warning mode change request";
CM_ SG_ 1421 FIU_SettRecResol_Req "REC resolution of video-file";
CM_ SG_ 1421 FIU_SettAebFcwMode_Req "Front collision warning mode change request";
CM_ SG_ 1421 FIU_SettLDWVibration_Req "Line departure warning tactile sensation function eneble/ disable change request";
CM_ SG_ 1421 FIU_SettRCTCsts_Req "Rear control trafic collision state change request";
CM_ SG_ 1421 FIU_SettASLAOver_Req "Over threshold speed request";
CM_ SG_ 1421 FIU_SettCCType_Req "Cruise control type change request";
CM_ SG_ 1421 FIU_SettALCCSts_Req "Active line change contol state change request";
CM_ SG_ 1421 FIU_SettDOWSoundAlert_Req "Door opening warning sound alert function eneble/ disable change request";
CM_ SG_ 1421 FIU_SettRecSts_Req "REC activation status";
CM_ SG_ 1421 FIU_StartSet_Req "Start send setting request";
CM_ SG_ 1421 FIU_SettLCCSts_Req "Lane change control state change request";
CM_ SG_ 1421 FIU_SettAFSsts_Req "Automatic forced stop change request";
CM_ SG_ 1421 FIU_SettAAmode_Req "Attention assist mode change request";
CM_ SG_ 1421 FIU_SettFCWSts_Req "Forward collision warning state change request. Only for HEV";
CM_ SG_ 1421 FIU_SettCCSpdCorrect_Req "Request change of speed in a turn";
CM_ SG_ 1421 FIU_SettLKASts_Req "Line keep assistant state change request";
CM_ SG_ 1421 FIU_SettLCCVibration_Req "Lane change control tactile sensation function eneble/ disable change request";
CM_ SG_ 1421 FIU_SettLDWSts_Req "Line departure warning state change request";
CM_ SG_ 1421 FIU_SettASLASts_Req "Active speed limiter state change request";
CM_ SG_ 1421 FIU_SettAAsts_Req "Attention assist state change request";
CM_ SG_ 1421 FIU_SettTSRsts_Req "Traffic sign recognition state change request";
CM_ SG_ 1421 FIU_SettLDWSoundAlert_Req "Line departure warning sound alert function eneble/ disable change request";
CM_ SG_ 528 RRSeatBeltWarning "When the bit is set to a '1', a warning is required due to rear right seat belt not detected buckled.";
CM_ SG_ 528 ACU_SysDeactEn_Stat "Indicates when the complet airbags deactivation is requested:
$0 = Disable Complete airbags deactivation
$1 = Enable Complete airbags deactivation";
CM_ SG_ 528 DrivSeatBeltWarning "When the bit is set to a '1', a warning is required due to driver seat belt not detected buckled.";
CM_ SG_ 528 PassSeatBeltWarning "When the bit is set to a '1', a warning is required due to passenger seat belt not detected buckled.";
CM_ SG_ 528 ACU_01_CS "Checksum XOR8 of the data field this message
Checksum computed as per XOR algorithm:
Byte 1 XOR byte 2 .... XOR byte n-1. (n = packet length.)";
CM_ SG_ 528 FrontBuckleDriver_L "Indicates belt status & Buckle status

Bit 0: 0 = Belt status: unbelted
Bit 0: 1 = Belt status: belted
Bit 1: 0 = Buckle status: normal operation
Bit 1: 1 = Buckle status: faulty";
CM_ SG_ 528 RLSeatBeltWarning "When the bit is set to a '1', a warning is required due to rear left seat belt not detected buckled.";
CM_ SG_ 528 ACU_01_RC "Rolling Counter [0 - 15]";
CM_ SG_ 528 ACU_AirbagFrontPsngr_Stat "Indicates the activation status of the front passenger airbag
$0 = Active, Lamp OFF
$1 = Reserved
$2 = Inactive, Lamp ON";
CM_ SG_ 528 ACU_CrashEventDetect_Stat "The signal is generated when an accident-related event (Crash) occurs when at least one of several accident detection algorithms (Front crash detection, Rear crash detection or Side crash detection) is performed.";
CM_ SG_ 528 RILRequestStatus "Indicates the state of the SRS Warning Lamp in the Instrument Cluster:
$0 = RIL Request OFF: No fault
$1 = Reserved
$2 = RIL Blinking Request: Deployment algorithm deactivated (because of either Remote Start state or system deactivation switch)
$3 = R";
CM_ SG_ 256 ESC_CDPDecelActive "Indicates that deceleration request from EPB is executed
$0 = Not Active
$1 = Active";
CM_ SG_ 256 ESC_BLS_Fault "Brake Light Switch fault indication.";
CM_ SG_ 256 ESC_PEBWarningLampReq "Activate animation in IC to inform user that the vehicle was braked in both of the following cases:
- Automatic emergency braking activation without driver braking
- Automatic emergency braking activation with driver brake assist";
CM_ SG_ 256 ESC_04_CS "Checksum CRC8 SAE J1850 of the data field this message";
CM_ SG_ 256 ESC_HDC_rejected "HDC activation rejected, if driver presses HDC switch in wrong driving mode.";
CM_ SG_ 256 ESC_CtlActiveTcs "Indicates activity of TCS control";
CM_ SG_ 256 ESC_CtlActiveAbs "Indicates activity of ABS control";
CM_ SG_ 256 ESC_Bls_Out "Brake Light Switch. Indicates brake pedal pressing status (derived from brake light switch and brake switch)";
CM_ SG_ 256 ESC_HDC_Activated "Indicates that driver has activated HDC function using the HDC switch. (not controller status)";
CM_ SG_ 256 ESC_ABS_Lamp "ABS lamp control signal for HMI and ABS function fault indication";
CM_ SG_ 256 ESC_EBD_Lamp "EBD function or booster fault indication for BK-Lamp control.";
CM_ SG_ 256 ESC_Lamp "ESC lamp control signal for HMI.";
CM_ SG_ 256 ESC_RequestToEPB "ESC request to open or close the park brake
$0 = Not Initialized
$1 = No Request
$2 = Release Brake
$3 = Lock Brake";
CM_ SG_ 256 ESC_TCS_Fault "TCS function fault indication";
CM_ SG_ 256 ESC_AVH_Active "Feedback to EPB that indicates hydraulic holding
$0 = Not Active
$1 = Active";
CM_ SG_ 256 ESC_CDPDecelAvailable "Indicates that CDP is available for decelerating the vehicle
$0 = Not Available
$1 = Available";
CM_ SG_ 256 ESC_CtlActiveHDC "HDC controller activity indication";
CM_ SG_ 256 ESC_CtlActiveEbd "Indicates activity of EBD control";
CM_ SG_ 256 ESC_Passive_Lamp "Control signal to HMI to control passive lamp. (degraded state of ESC CU functions)";
CM_ SG_ 256 ESC_CtlActiveVdc "Indicates activity of VDC control (VDC= ESC function to stabilize the vehicle; not the differential function)";
CM_ SG_ 256 ESC_EmergencyBraking "Emergency braking function status";
CM_ SG_ 256 ESC_VehicleSpeed_ValueError "Indicates if the signal vehicleSpeed has valid value";
CM_ SG_ 256 ESC_04_RC "Rolling Counter [0 - 15]";
CM_ SG_ 256 ESC_Bla "Brake Light Activation. Indicates braking via driver or via other functions.";
CM_ SG_ 256 ESC_VehicleSpeed "Calculated vehicle speed value";
CM_ SG_ 256 CddActive_2 "Indicates cdd control active (Controlled Deceleration for Driver Assistant Systems)
$0 = Inactive
$1 = Active
(CddActive duplicata)";
CM_ SG_ 256 ESC_Gearshift_Inhibit "During critical activity in ESC control unit, request to gearbox control unit to inhibit gear shifting.";
CM_ SG_ 256 ESC_HDC_SpeedLimit "Indicates the current speed limitation due to a Hill Descent Assist phase";
CM_ SG_ 130 ESC_WheelSpeed_RR "Wheel speed of rear right wheel";
CM_ SG_ 130 ESC_WheelSpeed_ValueError_RR "Indicates if the signal WheelSpeed_RR has valid value";
CM_ SG_ 130 ESC_WheelSpeed_ValueError_RL "Indicates if the signal WheelSpeed_RL has valid value";
CM_ SG_ 130 ESC_WheelDirectionInfo_RR "Direction/stillstand info for rear right wheel";
CM_ SG_ 130 ESC_WheelSpeed_RL "Wheel speed of rear left wheel";
CM_ SG_ 130 ESC_03_CS "Checksum CRC8 SAE J1850 of the data field this message";
CM_ SG_ 130 ESC_03_RC "Rolling Counter [0 - 15]";
CM_ SG_ 130 ESC_WheelDirectionInfo_RL "Direction/stillstand info for rear left wheel";
CM_ SG_ 129 ESC_02_CS "Checksum CRC8 SAE J1850 of the data field this message";
CM_ SG_ 129 ESC_WheelSpeed_FL "Wheel speed of front left wheel";
CM_ SG_ 129 ESC_WheelDirectionInfo_FL "Direction/stillstand info for front left wheel";
CM_ SG_ 129 ESC_WheelSpeed_ValueError_FR "Indicates if the signal WheelSpeed_FR has valid value";
CM_ SG_ 129 ESC_02_RC "Rolling Counter [0 - 15]";
CM_ SG_ 129 ESC_WheelDirectionInfo_FR "Direction/stillstand info for front right wheel";
CM_ SG_ 129 ESC_WheelSpeed_ValueError_FL "Indicates if the signal WheelSpeed_FL has valid value";
CM_ SG_ 129 ESC_WheelSpeed_FR "Wheel speed of front right wheel";
CM_ BO_ 2015 "Diagnostic Message";
CM_ SG_ 2015 Diag_Functional_Sig "Diagnostic signal";
CM_ SG_ 354 DAS_AfsBrakeJerk_Req "AFS requests a brake jerk to warn the driver in a hazardous situation";
CM_ SG_ 354 DAS_AebFuncError_Stat "Error symbol of AEB";
CM_ SG_ 354 DAS_AebRdaStand_Req "AEB or RDA is requestin enable HOLD";
CM_ SG_ 354 DAS_04_RC "Rolling Counter [0 - 15]";
CM_ SG_ 354 DAS_CcFuncError_Stat "Error symbol of CC";
CM_ SG_ 354 DAS_CcBrakeStandSt_Req "Cruise is requesting a car hold";
CM_ SG_ 354 DAS_CcBrakeRelease_Req "Cruise is requesting to start the car";
CM_ SG_ 354 DAS_AebMode_Stat "Mode of emergency braking";
CM_ SG_ 354 DAS_04_CS "Checksum CRC8 SAE J1850 of the data field this message";
CM_ SG_ 354 DAS_CcMode_Stat "Mode of CC";
CM_ SG_ 354 DAS_AebDecelFlag_Req "AEB is requesting to implement deceleration";
CM_ SG_ 354 DAS_AfsBrakeJerkEnab_Stat "Enable the brake jerk warning functionnality";
CM_ SG_ 354 DAS_AfsBrakeJerkLvl_Stat "Indicates strength of Brake Jerk warning level requested by AFS";
CM_ SG_ 354 DAS_CcDecelFlag_Req "Cruise is requesting to implement deceleration";
CM_ SG_ 522 DAS_LkaSteeringMode_Stat "LKA mode for RSA";
CM_ SG_ 522 DAS_RctcDecelFlag_Req "RCTC is requesting to implement deceleration";
CM_ SG_ 522 DAS_AccFuncError_Stat "Error symbol of ACC (Adaptive Cruise Control)";
CM_ SG_ 522 DAS_RctcNotifError_Req "Error notification of RCTC";
CM_ SG_ 522 DAS_RctcFuncError_Stat "Error of RCTC (Rear Cross Traffic Control)";
CM_ SG_ 522 DAS_RctcMode_Stat "Mode of RDA";
CM_ SG_ 522 DAS_AfsNotifError_Req "Error notification of AFS";
CM_ SG_ 522 DAS_ApaFuncError_Stat "Error of APA";
CM_ SG_ 522 DAS_APAMode_Stat "Mode of APA";
CM_ SG_ 522 DAS_RsaAngleDirection_Req "Rear steering actuator mode request";
CM_ SG_ 522 DAS_02_RC "Rolling Counter [0 - 15]";
CM_ SG_ 522 DAS_LdpMode_Stat "Mode of LDP (Lane Departure Prevention)";
CM_ SG_ 522 DAS_02_CS "Checksum XOR8 of the data field this message
Checksum computed as per XOR algorithm:
Byte 1 XOR byte 2 .... XOR byte n-1. (n = packet length.)";
CM_ SG_ 522 DAS_LkaAngleFlag_Req "LKA (Lane Keeping Assist) is requesting to implement angle  on steering wheel";
CM_ SG_ 522 DAS_AfsDecelFlag_Req "AFS (Automatic forced stop) is requesting to implement deceleration";
CM_ SG_ 522 DAS_AlccMode_Stat "Mode of ALCC (Active Lane Change Control)";
CM_ SG_ 522 DAS_AfsFuncError_Stat "Error of AFS";
CM_ SG_ 522 DAS_LdwFuncError_Stat "Error symbol of LDW (Lane Departure Warning)";
CM_ SG_ 522 DAS_AfsSos_Req "AFS is requesting call SOS";
CM_ SG_ 522 DAS_LkaMode_Stat "Mode of LKA";
CM_ SG_ 522 DAS_RdaMode_Stat "Mode of RDA (Reverse driving assist)";
CM_ SG_ 522 DAS_AlccAngleFlag_Req "ALCC is requesting to implement angle on steering wheel";
CM_ SG_ 522 DAS_AfsEpb_Req "AFS is requesting apply the parking brake";
CM_ SG_ 522 DAS_AfsMode_Stat "Mode of AFS";
CM_ SG_ 522 DAS_LkaAngle_Req "Angle request";
CM_ SG_ 522 DAS_LccFuncError_Stat "Error symbol of LCC (Lane Change Control)";
CM_ SG_ 522 DAS_RdaDecelFlag_Req "RDA is requesting to implement deceleration";
CM_ SG_ 522 DAS_AfsExecute_Req "AFS is requesting open door and emergency lights";
CM_ SG_ 522 DAS_RdaFuncError_Stat "Error of RDA";
CM_ SG_ 522 DAS_LkaFuncError_Stat "Error symbol of LKA";
CM_ SG_ 522 DAS_LdpAngleFlag_Req "LDP is requesting to implement angle on steering wheel";
CM_ SG_ 522 DAS_ApaAngleFlag_Req "APA is requesting to implement angle  on steering wheel";
CM_ SG_ 352 DAS_CcAfsDecel_Req "Implement deceleration of CC";
CM_ SG_ 352 DAS_01_CS "Checksum CRC8 SAE J1850 of the data field this message";
CM_ SG_ 352 DAS_01_RC "Rolling Counter [0 - 15]";
CM_ SG_ 352 DAS_AebRdaDecel_Req "Implement deceleration, ms^2";
CM_ SG_ 352 DAS_AebPrefill_Req "AEB is requesting brake prefill";
CM_ SG_ 352 DAS_CcBrakeLight_Req "CC (Cruise Control) is requesting the brake light to be turned on";
CM_ SG_ 352 DAS_AebPreCrash_Req "AEB is inform a potential accident";
CM_ SG_ 352 DAS_AebBoost_Req "AEB (Automatic Emergency Braking) is requesting brake boost";
CM_ SG_ 658 DAS_LeftProjBrightSlot1_Req "Slot_1 Projection Brightness Control Signal";
CM_ SG_ 658 DAS_LeftProjSlot1_Req "Slot_1 Projection Control Signal";
CM_ SG_ 658 DAS_LeftProjSlot4_Req "Slot_4 Projection Control Signal";
CM_ SG_ 658 DAS_RightProjBrightSlot3_Req "Slot_3 Projection Brightness Control Signal";
CM_ SG_ 658 DAS_RightProjSlot3_Req "Slot_3 Projection Control Signal";
CM_ SG_ 658 DAS_RightProjBrightSlot4_Req "Slot_4 Projection Brightness Control Signal";
CM_ SG_ 658 DAS_LeftProjBrightSlot3_Req "Slot_3 Projection Brightness Control Signal";
CM_ SG_ 658 DAS_LeftProjBrightSlot2_Req "Slot_2 Projection Brightness Control Signal";
CM_ SG_ 658 DAS_RightProjBrightSlot2_Req "Slot_2 Projection Brightness Control Signal";
CM_ SG_ 658 DAS_LeftProjSlot3_Req "Slot_3 Projection Control Signal";
CM_ SG_ 658 DAS_RightProjSlot1_Req "Slot_1 Projection Control Signal";
CM_ SG_ 658 DAS_LeftProjSlot2_Req "Slot_2 Projection Control Signal";
CM_ SG_ 658 DAS_LeftProjBrightSlot4_Req "Slot_4 Projection Brightness Control Signal";
CM_ SG_ 658 DAS_RightProjSlot4_Req "Slot_4 Projection Control Signal";
CM_ SG_ 658 DAS_RightProjBrightSlot1_Req "Slot_1 Projection Brightness Control Signal";
CM_ SG_ 658 DAS_RightProjSlot2_Req "Slot_2 Projection Control Signal";
CM_ SG_ 657 DAS_RightObj_1_Y_2_Val "Object_1 Horizontal Value_2";
CM_ SG_ 657 DAS_RightObj_3_Y_2_Val "Object_3 Horizontal Value_2";
CM_ SG_ 657 DAS_ADBRightLED5_Req "Right_ADB LED#5 Control Signal";
CM_ SG_ 657 DAS_ADBRightLED1_Req "Right_ADB LED#1 Control Signal";
CM_ SG_ 657 DAS_RightObj_5_Z_2_Val "Object_5 Vertical  Value_2";
CM_ SG_ 657 DAS_RightObj_7_Z_2_Val "Object_7 Vertical  Value_2";
CM_ SG_ 657 DAS_RightObj_9_Z_2_Val "Object_9 Vertical  Value_2";
CM_ SG_ 657 DAS_RightObj_8_Y_1_Val "Object_8 Horizontal Value_1";
CM_ SG_ 657 DAS_ADBRightLED6_Req "Right_ADB LED#6 Control Signal";
CM_ SG_ 657 DAS_RightObj_9_Y_2_Val "Object_9 Horizontal Value_2";
CM_ SG_ 657 DAS_ADBRightLED10_Req "Right_ADB LED#10 Control Signal";
CM_ SG_ 657 DAS_ADBRightLED16_Req "Right_ADB LED#16 Control Signal";
CM_ SG_ 657 DAS_ADBRightLED11_Req "Right_ADB LED#11 Control Signal";
CM_ SG_ 657 DAS_RightObj_10_Y_2_Val "Object_10 Horizontal Value_2";
CM_ SG_ 657 DAS_RightObj_10_Z_2_Val "Object_10 Vertical  Value_2";
CM_ SG_ 657 DAS_RightObj_3_Z_2_Val "Object_3 Vertical  Value_2";
CM_ SG_ 657 DAS_RightObj_4_Y_1_Val "Object_4 Horizontal Value_1";
CM_ SG_ 657 DAS_RightObj_8_Z_1_Val "Object_8 Vertical Value_1";
CM_ SG_ 657 DAS_RightObj_6_Z_2_Val "Object_6 Vertical  Value_2";
CM_ SG_ 657 DAS_ADBRightLED12_Req "Right_ADB LED#12 Control Signal";
CM_ SG_ 657 DAS_HLR_Object_CS "Checksum XOR8 of the data field this message
Checksum computed as per XOR algorithm:
Byte 1 XOR byte 2 .... XOR byte n-1. (n = packet length.)";
CM_ SG_ 657 DAS_ADBRightLED15_Req "Right_ADB LED#15 Control Signal";
CM_ SG_ 657 DAS_RightObj_3_Z_1_Val "Object_3 Vertical Value_1";
CM_ SG_ 657 DAS_ADBRightLED8_Req "Right_ADB LED#8 Control Signal";
CM_ SG_ 657 DAS_HLR_Object_RC "Rolling Counter [0 - 15]";
CM_ SG_ 657 DAS_RightObj_7_Y_2_Val "Object_7 Horizontal Value_2";
CM_ SG_ 657 DAS_RightObj_9_Y_1_Val "Object_9 Horizontal Value_1";
CM_ SG_ 657 DAS_RightObj_4_Y_2_Val "Object_4 Horizontal Value_2";
CM_ SG_ 657 DAS_RightObj_2_Z_1_Val "Object_2 Vertical Value_1";
CM_ SG_ 657 DAS_RightObj_7_Z_1_Val "Object_7 Vertical Value_1";
CM_ SG_ 657 DAS_RightObj_9_Z_1_Val "Object_9 Vertical Value_1";
CM_ SG_ 657 DAS_RightObj_5_Y_1_Val "Object_5 Horizontal Value_1";
CM_ SG_ 657 DAS_RightObj_10_Z_1_Val "Object_10 Vertical Value_1";
CM_ SG_ 657 DAS_RightObj_8_Y_2_Val "Object_8 Horizontal Value_2";
CM_ SG_ 657 DAS_ADBRightLED4_Req "Right_ADB LED#4 Control Signal";
CM_ SG_ 657 DAS_RightObj_4_Z_2_Val "Object_4 Vertical  Value_2";
CM_ SG_ 657 DAS_RightObj_6_Y_1_Val "Object_6 Horizontal Value_1";
CM_ SG_ 657 DAS_ADBRightLED13_Req "Right_ADB LED#13 Control Signal";
CM_ SG_ 657 DAS_RightObj_1_Y_1_Val "Object_1 Horizontal Value_1";
CM_ SG_ 657 DAS_ADBRightLED17_Req "Right_ADB LED#17 Control Signal";
CM_ SG_ 657 DAS_ADBRightLED9_Req "Right_ADB LED#9 Control Signal";
CM_ SG_ 657 DAS_RightObj_6_Z_1_Val "Object_6 Vertical Value_1";
CM_ SG_ 657 DAS_RightObj_4_Z_1_Val "Object_4 Vertical Value_1";
CM_ SG_ 657 DAS_ADBRightLED18_Req "Right_ADB LED#18 Control Signal";
CM_ SG_ 657 DAS_RightObj_1_Z_1_Val "Object_1 Vertical Value_1";
CM_ SG_ 657 DAS_ADBRightLED7_Req "Right_ADB LED#7 Control Signal";
CM_ SG_ 657 DAS_RightObj_8_Z_2_Val "Object_8 Vertical  Value_2";
CM_ SG_ 657 DAS_RightObj_2_Z_2_Val "Object_2 Vertical  Value_2";
CM_ SG_ 657 DAS_RightObj_3_Y_1_Val "Object_3 Horizontal Value_1";
CM_ SG_ 657 DAS_ADBRightLED3_Req "Right_ADB LED#3 Control Signal";
CM_ SG_ 657 DAS_RightObj_6_Y_2_Val "Object_6 Horizontal Value_2";
CM_ SG_ 657 DAS_RightObj_5_Z_1_Val "Object_5 Vertical Value_1";
CM_ SG_ 657 DAS_RightObj_5_Y_2_Val "Object_5 Horizontal Value_2";
CM_ SG_ 657 DAS_ADBRightLED2_Req "Right_ADB LED#2 Control Signal";
CM_ SG_ 657 DAS_ADBRightLED14_Req "Right_ADB LED#14 Control Signal";
CM_ SG_ 657 DAS_RightObj_2_Y_1_Val "Object_2 Horizontal Value_1";
CM_ SG_ 657 DAS_RightObj_10_Y_1_Val "Object_10 Horizontal Value_1";
CM_ SG_ 657 DAS_RightObj_1_Z_2_Val "Object_1 Vertical  Value_2";
CM_ SG_ 657 DAS_RightObj_2_Y_2_Val "Object_2 Horizontal Value_2";
CM_ SG_ 657 DAS_RightObj_7_Y_1_Val "Object_7 Horizontal Value_1";
BA_DEF_ SG_  "GenSigEVName" STRING ;
BA_DEF_ SG_  "SigType" ENUM  "Default","Range","RangeSigned","ASCII","Discrete","Control","ReferencePGN","DTC","StringDelimiter","StringLength","StringLengthControl","MessageCounter","MessageChecksum";
BA_DEF_ SG_  "GenSigILSupport" ENUM  "No","Yes";
BA_DEF_ SG_  "GenSigSendType" ENUM  "Cyclic","OnWrite","OnWriteWithRepetition","OnChange","OnChangeWithRepetition","IfActive","IfActiveWithRepetition","NoSigSendType","NotUsed","NotUsed","NotUsed","NotUsed","NotUsed";
BA_DEF_ SG_  "GenSigStartValue" INT 0 0;
BA_DEF_ BO_  "GenMsgRequestable" INT 0 1;
BA_DEF_ BO_  "GenMsgILSupport" ENUM  "No","Yes";
BA_DEF_ BO_  "VFrameFormat" ENUM  "StandardCAN","ExtendedCAN","reserved","J1939PG","reserved","reserved","reserved","reserved","reserved","reserved","reserved","reserved","reserved","reserved","StandardCAN_FD","ExtendedCAN_FD";
BA_DEF_ BO_  "J1939PgAppearanceOnBus" ENUM  "Default","CAN_Extended","CANFD_Extended";
BA_DEF_ BO_  "J1939CPgTOS" INT 0 7;
BA_DEF_ BO_  "J1939CPgSendTimeout" INT -1 3600000;
BA_DEF_ BO_  "DiagRequest" ENUM  "No","Yes";
BA_DEF_ BO_  "CANFD_BRS" ENUM  "0","1";
BA_DEF_ BO_  "GenMsgCycleTime" INT 0 0;
BA_DEF_ BO_  "GenMsgSendType" ENUM  "Cyclic","Spontaneous","IfActive","NoMsgSendType","NotUsed";
BA_DEF_DEF_  "GenSigEVName" "Env@Nodename_@Signame";
BA_DEF_DEF_  "SigType" "Default";
BA_DEF_DEF_  "GenSigILSupport" "Yes";
BA_DEF_DEF_  "GenSigSendType" "Cyclic";
BA_DEF_DEF_  "GenSigStartValue" 0;
BA_DEF_DEF_  "GenMsgRequestable" 1;
BA_DEF_DEF_  "GenMsgILSupport" "Yes";
BA_DEF_DEF_  "VFrameFormat" "";
BA_DEF_DEF_  "J1939PgAppearanceOnBus" "Default";
BA_DEF_DEF_  "J1939CPgTOS" 2;
BA_DEF_DEF_  "J1939CPgSendTimeout" -1;
BA_DEF_DEF_  "DiagRequest" "No";
BA_DEF_DEF_  "CANFD_BRS" "1";
BA_DEF_DEF_  "GenMsgCycleTime" 0;
BA_DEF_DEF_  "GenMsgSendType" "";
BA_ "VFrameFormat" BO_ 752 0;
BA_ "GenMsgCycleTime" BO_ 752 50;
BA_ "GenMsgSendType" BO_ 752 0;
BA_ "VFrameFormat" BO_ 866 0;
BA_ "GenMsgCycleTime" BO_ 866 1000;
BA_ "GenMsgSendType" BO_ 866 0;
BA_ "VFrameFormat" BO_ 869 0;
BA_ "GenMsgCycleTime" BO_ 869 250;
BA_ "GenMsgSendType" BO_ 869 0;
BA_ "VFrameFormat" BO_ 626 0;
BA_ "GenMsgCycleTime" BO_ 626 20;
BA_ "GenMsgSendType" BO_ 626 0;
BA_ "VFrameFormat" BO_ 1421 0;
BA_ "GenMsgSendType" BO_ 1421 1;
BA_ "VFrameFormat" BO_ 528 0;
BA_ "GenMsgCycleTime" BO_ 528 100;
BA_ "GenMsgSendType" BO_ 528 0;
BA_ "VFrameFormat" BO_ 256 0;
BA_ "GenMsgCycleTime" BO_ 256 20;
BA_ "GenMsgSendType" BO_ 256 0;
BA_ "VFrameFormat" BO_ 130 0;
BA_ "GenMsgCycleTime" BO_ 130 10;
BA_ "GenMsgSendType" BO_ 130 0;
BA_ "VFrameFormat" BO_ 129 0;
BA_ "GenMsgCycleTime" BO_ 129 10;
BA_ "GenMsgSendType" BO_ 129 0;
BA_ "VFrameFormat" BO_ 2015 0;
BA_ "DiagRequest" BO_ 2015 1;
BA_ "GenMsgSendType" BO_ 2015 1;
BA_ "VFrameFormat" BO_ 354 0;
BA_ "GenMsgCycleTime" BO_ 354 10;
BA_ "GenMsgSendType" BO_ 354 0;
BA_ "VFrameFormat" BO_ 522 0;
BA_ "GenMsgCycleTime" BO_ 522 50;
BA_ "GenMsgSendType" BO_ 522 0;
BA_ "VFrameFormat" BO_ 352 0;
BA_ "GenMsgCycleTime" BO_ 352 10;
BA_ "GenMsgSendType" BO_ 352 0;
BA_ "GenMsgCycleTime" BO_ 658 50;
BA_ "GenMsgSendType" BO_ 658 0;
BA_ "VFrameFormat" BO_ 658 14;
BA_ "GenMsgCycleTime" BO_ 657 50;
BA_ "GenMsgSendType" BO_ 657 0;
BA_ "VFrameFormat" BO_ 657 14;
BA_ "GenSigStartValue" SG_ 866 BCM_LvBat1_SOC_Pct 100;
BA_ "GenSigStartValue" SG_ 869 WindshieldTemp 80;
BA_ "GenSigStartValue" SG_ 626 ATC_MaxTorque_Val 32768;
BA_ "GenSigStartValue" SG_ 626 ATC_TrqClu_Val 32768;
BA_ "GenSigStartValue" SG_ 1421 FIU_SettASLAOver_Req 1;
BA_ "GenSigStartValue" SG_ 256 ESC_VehicleSpeed_ValueError 1;
BA_ "GenSigStartValue" SG_ 130 ESC_WheelSpeed_ValueError_RR 1;
BA_ "GenSigStartValue" SG_ 130 ESC_WheelSpeed_ValueError_RL 1;
BA_ "GenSigStartValue" SG_ 129 ESC_WheelSpeed_ValueError_FR 1;
BA_ "GenSigStartValue" SG_ 129 ESC_WheelSpeed_ValueError_FL 1;
BA_ "GenSigStartValue" SG_ 522 DAS_LkaAngle_Req 8191;
VAL_ 752 BCM_AlarmOFF_Stat 1 "Alarm system disabled" 0 "Alarm system enabled" ;
VAL_ 752 BCM_MovementSensOFF_Stat 1 "Sensor inactive" 0 "Sensor active" ;
VAL_ 752 BCM_WindowsOpen_Req 1 "Windows Opening requested" 0 "Not requested" ;
VAL_ 752 BCM_WindowsClose_Cmd 1 "Windows Closing command" 0 "No Command" ;
VAL_ 752 BCM_TrunkLatchRelease_Req 1 "Trunk lid unlock requested" 0 "Not requested" ;
VAL_ 752 BCM_RRDoorClose_Req 2 "Open door" 1 "Close door" 0 "No action" ;
VAL_ 752 BCM_HoodOpen_Stat 3 "Sensor error" 2 "Hood closed" 1 "Hood opened" 0 "Reserved" ;
VAL_ 752 PTG_MemorySetRequest 2 "Clear Memory" 1 "Store Position in memory" 0 "No Request" ;
VAL_ 752 BCM_DoorHandleLight_Req 1 "Requested" 0 "No requested" ;
VAL_ 752 BCM_VehDoubleLock_Stat 1 "Double lock active" 0 "Double lock inactive" ;
VAL_ 752 BCM_Alarm_Req 1 "Request_Active" 0 "No_Request" ;
VAL_ 752 BCM_Alarm_Reason 10 "Hit detected" 9 "Towing detected" 8 "Hood open" 7 "Intrusion level 2 requested" 6 "Intrusion level 1 requested" 5 "TrunkLid_Open" 4 "RR door open" 3 "RL door open" 2 "FR door open" 1 "FL door open" 0 "No_Reasons" ;
VAL_ 752 VehicleLockStateReason 11 "Locked by Re-Lock" 10 "Locked drive away" 9 "Locked Pre-Crash" 8 "Locked Internal" 7 "Locked External" 6 "Reserved" 5 "Unlocked Post Crash" 4 "Unlocked Int. Trunk Only" 3 "Unlocked Ext. Trunk Only" 2 "Unlocked From Internal" 1 "Unlocked From External" 0 "Unknown" ;
VAL_ 752 BCM_FuelLidUnlock_Req 1 "Unlock fuel lid" 0 "No Action" ;
VAL_ 752 BCM_FRDoorClose_Req 2 "Open door" 1 "Close door" 0 "No action" ;
VAL_ 752 BCM_HVlid_Stat 1 "HV lid opened" 0 "HV lid closed" ;
VAL_ 752 VehicleLockState 1 "Vehicle locked" 0 "Vehicle unlocked" ;
VAL_ 752 BCM_RLDoorClose_Req 2 "Open door" 1 "Close door" 0 "No action" ;
VAL_ 752 BCM_FrontLeftLockCmd 4 "DoubleLockDisable_Req" 3 "DoubleLock_Req" 2 "SingleLock_Req" 1 "Unlock_Req" 0 "No_Request" ;
VAL_ 752 PTG_MovementCmd 2 "Close" 1 "Open " 0 "Stop" ;
VAL_ 752 BCM_RearWiperWipe_Req 1 "Requested" 0 "No requested" ;
VAL_ 752 BCM_FrontRightLockCmd 4 "DoubleLockDisable_Req" 3 "DoubleLock_Req" 2 "SingleLock_Req" 1 "Unlock_Req" 0 "No_Request" ;
VAL_ 752 BCM_RearLeftLockCmd 4 "DoubleLockDisable_Req" 3 "DoubleLock_Req" 2 "SingleLock_Req" 1 "Unlock_Req" 0 "No_Request" ;
VAL_ 752 BCM_PanicAlertActive 1 "Panic Mode Active" 0 "Panic Mode Inactive" ;
VAL_ 752 BCM_FLDoorClose_Req 2 "Open door" 1 "Close door" 0 "No action" ;
VAL_ 752 BCM_RearRightLockCmd 4 "DoubleLockDisable_Req" 3 "DoubleLock_Req" 2 "SingleLock_Req" 1 "Unlock_Req" 0 "No_Request" ;
VAL_ 752 BCM_DoorAjarState_RR 3 "Fault" 2 "Door Opened" 1 "Door Closed" 0 "Reserved" ;
VAL_ 752 BCM_DoorAjarState_RL 3 "Fault" 2 "Door Opened" 1 "Door Closed" 0 "Reserved" ;
VAL_ 752 BCM_DoorAjarState_FR 3 "Fault" 2 "Door Opened" 1 "Door Closed" 0 "Reserved" ;
VAL_ 752 BCM_DoorAjarState_FL 3 "Fault" 2 "Door Opened" 1 "Door Closed" 0 "Reserved" ;
VAL_ 752 BCM_DoorMovDis_Stat 1 "Door movement system disabled" 0 "Door movement system enabled" ;
VAL_ 866 BCM_EngStartNotif_Stat 1 "Notification Active" 0 "No Notification " ;
VAL_ 866 BCM_SRoofManipulationWarn_Req 1 "Soft Roof is not in completely open or close position, Trunk lid cannot be opened" 0 "No restrictions on opening Trunk lid" ;
VAL_ 866 BCM_RearRight_FogLight_Status 1 "Light failure" 0 "No failure" ;
VAL_ 866 BCM_RearLeft_FogLight_Status 1 "Light failure" 0 "No failure" ;
VAL_ 866 BCM_LvBat1_SOC_Pct 127 "Error" ;
VAL_ 866 BCM_TrunkLidOpenWarn_Req 1 "Trunk lid is opened, Soft Roof cannot be manipulated" 0 "No restrictions on manipulating Soft Roof" ;
VAL_ 866 BCM_FuelLvl_HMI 127 "Fault" 0 "0% - Empty Tank" ;
VAL_ 866 BCM_LvBatCharging_Stat 1 "LV Battery Discharging" 0 "LV Battery Charging" ;
VAL_ 866 BCM_TurnIndicatorRR_Status 1 "RearRight turn indicator failure" 0 "No failure" ;
VAL_ 866 BCM_DaytimeLightRight_Status 1 "Right daytime running lamp fault" 0 "No failure" ;
VAL_ 866 BCM_TurnIndicatorRL_Status 1 "Rear left turn indicator failure" 0 "No failure" ;
VAL_ 866 BCM_LvBat1_SOH 2 "Extemally Low State of Health " 1 "Low State of Health Battery" 0 "Normal State of Health Battery" ;
VAL_ 866 BCM_TurnIndicatorMR_Status 1 "R mirror turn indicator failure" 0 "No failure" ;
VAL_ 866 BCM_WarningInd 1 "Warning requested" 0 "No Warning" ;
VAL_ 866 BCM_PosLightFR_status 1 "FR position light lamp failure" 0 "No fault" ;
VAL_ 866 BCM_TurnIndicatorFL_Status 1 "FL turn indicator failure" 0 "No failure" ;
VAL_ 866 BCM_ReverseLightsRight_Status 1 "Reverse light right lamp failure" 0 "No failure" ;
VAL_ 866 BCM_PositionLight_RL_Status 1 "RL position light lamp failure" 0 "No failure" ;
VAL_ 866 BCM_HeadLghtLevelinglFailure 1 "True" 0 "False" ;
VAL_ 866 BCM_BrakeLightLeft_Status 1 "Left brake light lamp failure" 0 "No failure" ;
VAL_ 866 BCM_ReverseLightsLeft_Status 1 "Reverse light left lamp failure" 0 "No failure" ;
VAL_ 866 BCM_AdaptiveLghtsFailure 1 "Failure Detect" 0 "No Failure" ;
VAL_ 866 BCM_DisplayBcgrndIntensityRef 255 "Fault" ;
VAL_ 866 BCM_CorneringLightRight_Status 1 "Right cornering light lamp failure" 0 "No failure" ;
VAL_ 866 BCM_LvBat1_SOC 3 "Battery Discharge" 2 "Battery Requiered Charging" 1 "Battery Charge Normal " 0 "Battery Charge Full" ;
VAL_ 866 BCM_PowerSteeringCtrlFault 1 "Steering Fluid Control Fault" 0 "No Action" ;
VAL_ 866 BCM_CalSteeringWhColumnReq 1 "Calibration Requested" 0 "Calbrration Not Requested" ;
VAL_ 866 BCM_LowBeamLeft_Status 1 "Left low-beam lamp failure" 0 "No failure" ;
VAL_ 866 BCM_BrakeLightRight_Status 1 "Right brake light lamp failure" 0 "No failure" ;
VAL_ 866 BCM_CorneringLightLeft_Status 1 "Left cornering light lamp failure" 0 "No failure" ;
VAL_ 866 BCM_ExteriorSystemStatus 1 "Exterior Lights System Failure" 0 "No Failure" ;
VAL_ 866 BCM_TurnIndicatorML_Status 1 "L mirror turn indicator failure" 0 "No failure" ;
VAL_ 866 BCM_LowBeamRight_Status 1 "Right low-beam lamp failure" 0 "No failure" ;
VAL_ 866 BCM_TurnIndicatorFR_Status 1 "FR turn indicator failure" 0 "No failure" ;
VAL_ 866 BCM_DaytimeLightLeft_Status 1 "Left daytime running lamp failure" 0 "No failure" ;
VAL_ 866 BCM_AllWthrLght_Fault 1 "Fault detect" 0 "No Fault" ;
VAL_ 866 BCM_HighBeamAutoStatus 1 "Auto High Beam Unavailable" 0 "Auto High Beam Available" ;
VAL_ 866 BCM_HighBeamRight_Status 1 "Right high-beam lamp failure" 0 "No failure" ;
VAL_ 866 BCM_HighBeamLeft_Status 1 "Left high-beam lamp failure" 0 "No failure" ;
VAL_ 866 BCM_PosLightFL_status 1 "FL position light lamp failure" 0 "No fault" ;
VAL_ 866 BCM_WasherFluidLevel 1 "Water fluid low level" 0 "Washer fluid normal" ;
VAL_ 866 BCM_PositionLight_RR_Status 1 "RR position light lamp failure" 0 "No failure" ;
VAL_ 869 RearWindowHeating_Status 1 "Heating ON" 0 "Heating OFF" ;
VAL_ 869 BCM_SideWindowType_Stat 1 "Side window heaters present" 0 "Side window heaters not present" ;
VAL_ 869 BCM_MirrorHeating_Cmd 1 "Heating ON" 0 "Heating OFF" ;
VAL_ 869 BCM_WindowWashingSt 1 "Window Washing On" 0 "Window Washing Off" ;
VAL_ 869 BCM_WipeLowTempWarn_Req 1 "Low temp warning requested" 0 "No request" ;
VAL_ 869 RainDensity 1 "High Density" 0 "Low Density" ;
VAL_ 869 RainDetected 1 "TRUE" 0 "FALSE" ;
VAL_ 869 BCM_RearWindowHeating_Cmd 1 "Heating ON" 0 "Heating OFF" ;
VAL_ 869 BCM_Wiper_Stat 1 "Active" 0 "Inactive" ;
VAL_ 869 BCM_GloveBox_Stat 1 "Glove box opened" 0 "Glove box closed" ;
VAL_ 869 FrontWindowHeating_Status 1 "Heating ON" 0 "Heating OFF" ;
VAL_ 869 SideWindowHeating_Status 1 "Heating ON" 0 "Heating OFF" ;
VAL_ 869 SWM_Heating_Req 3 "Fault" 2 "Heating OFF" 1 "Heating ON" 0 "Unknown" ;
VAL_ 626 ATCStTC 15 "Signal not available / SNA" 5 "Failed / FAIL" 4 "Temporary failed / T_FAIL" 3 "normal operation / NORMAL" 2 "calibration / CAL" 1 "Initialization / INIT" 0 "Deactivated / DEACT" ;
VAL_ 626 ATC_MaxTorque_Stat 1 "Valid" 0 "Invalid" ;
VAL_ 626 ATC_StTC_Stat 1 "Valid" 0 "Invalid" ;
VAL_ 626 ATC_TrqCluSt 1 "Valid" 0 "Invalid" ;
VAL_ 1421 FIU_SettRDAAutoBrake_Req 1 "Requested" 0 "Not requested" ;
VAL_ 1421 FIU_SettLCCMode_Req 3 "Far" 2 "Normal" 1 "Close" 0 "Not requested" ;
VAL_ 1421 FIU_SettRDAsts_Req 1 "Requested" 0 "Not requested" ;
VAL_ 1421 FIU_SettCCMode_Req 3 "Dynamic mode requested" 2 "Comfort mode requested" 1 "Auto mode requested" 0 "Not requested" ;
VAL_ 1421 FIU_SettSensCleanSts_Req 1 "Requested" 0 "Not requested" ;
VAL_ 1421 FIU_SettLCCSoundAlert_Req 1 "Requested" 0 "Not requested" ;
VAL_ 1421 FIU_SettAEBSts_Req 1 "Requested" 0 "Not requested" ;
VAL_ 1421 FIU_SettDOWSts_Req 1 "Requested" 0 "Not requested" ;
VAL_ 1421 FIU_SettAebFcwVibration_Req 1 "Requested" 0 "Not requested" ;
VAL_ 1421 FIU_SettLDPSts_Req 1 "Requested" 0 "Not requested" ;
VAL_ 1421 FIU_SettRecFileSize_Req 3 "5min requested" 2 "2min requested" 1 "1min requested" 0 "Not requested" ;
VAL_ 1421 FIU_SettLDWMode_Req 2 "While crossing requested" 1 "Before crossing requested" 0 "Not requested" ;
VAL_ 1421 FIU_SettRecResol_Req 2 "FHD requested" 1 "HD requested" 0 "Not requested" ;
VAL_ 1421 FIU_SettAebFcwMode_Req 3 "Late mode requested" 2 "Normal mode requested" 1 "Early mode requested" 0 "Not requested" ;
VAL_ 1421 FIU_SettLDWVibration_Req 1 "Requested" 0 "Not requested" ;
VAL_ 1421 FIU_SettRCTCsts_Req 1 "Requested" 0 "Not requested" ;
VAL_ 1421 FIU_SettASLAOver_Req 0 "Not requested" ;
VAL_ 1421 FIU_SettCCType_Req 4 "LIM" 3 "Speed limiter requested" 2 "ACC requested" 1 "CC requested" 0 "Not requested" ;
VAL_ 1421 FIU_SettALCCSts_Req 1 "Requested" 0 "Not requested" ;
VAL_ 1421 FIU_SettDOWSoundAlert_Req 1 "Reqested" 0 "Not requested" ;
VAL_ 1421 FIU_SettRecSts_Req 1 "Requested" 0 "Not requested" ;
VAL_ 1421 FIU_StartSet_Req 1 "Requested" 0 "Not requested" ;
VAL_ 1421 FIU_SettLCCSts_Req 1 "Requested" 0 "Not requested" ;
VAL_ 1421 FIU_SettAFSsts_Req 1 "Requested" 0 "Not requested" ;
VAL_ 1421 FIU_SettAAmode_Req 2 "High mode requested" 1 "Low mode requested" 0 "Not requested" ;
VAL_ 1421 FIU_SettFCWSts_Req 1 "Requested" 0 "Not requested" ;
VAL_ 1421 FIU_SettCCSpdCorrect_Req 1 "Requested" 0 "Not requested" ;
VAL_ 1421 FIU_SettLKASts_Req 1 "Requested" 0 "Not requested" ;
VAL_ 1421 FIU_SettLCCVibration_Req 1 "Requested" 0 "Not requested" ;
VAL_ 1421 FIU_SettLDWSts_Req 1 "Reqested" 0 "Not requested" ;
VAL_ 1421 FIU_SettASLASts_Req 1 "Requested" 0 "Not requested" ;
VAL_ 1421 FIU_SettAAsts_Req 1 "Requested" 0 "Not requested" ;
VAL_ 1421 FIU_SettTSRsts_Req 1 "Requested" 0 "Not requested" ;
VAL_ 1421 FIU_SettLDWSoundAlert_Req 1 "Requested" 0 "Not requested" ;
VAL_ 528 RRSeatBeltWarning 1 "Warning" 0 "No Warning" ;
VAL_ 528 ACU_SysDeactEn_Stat 1 "Enable Complete airbags deactivation" 0 "Disable Complete airbags deactivation" ;
VAL_ 528 DrivSeatBeltWarning 1 "Warning" 0 "No Warning" ;
VAL_ 528 PassSeatBeltWarning 1 "Warning" 0 "No Warning" ;
VAL_ 528 RLSeatBeltWarning 1 "Warning" 0 "No Warning" ;
VAL_ 528 ACU_AirbagFrontPsngr_Stat 3 "Not Used" 2 "Inactive, Lamp ON" 1 "Reserve" 0 "Active, Lamp OFF" ;
VAL_ 528 ACU_CrashEventDetect_Stat 1 "Crash event detected" 0 "Crash event not detected" ;
VAL_ 528 RILRequestStatus 3 "RIL Request ON" 2 "RIL Blinking Request" 1 "Reserved" 0 "RIL Request OFF" ;
VAL_ 256 ESC_CDPDecelActive 1 "Active" 0 "Not Active" ;
VAL_ 256 ESC_BLS_Fault 1 "BLS Faulty" 0 "BLS not faulty" ;
VAL_ 256 ESC_PEBWarningLampReq 1 "Warning requested" 0 "No Warning requested" ;
VAL_ 256 ESC_HDC_rejected 1 "HDC cannot be activated in current driving mode" 0 "No error" ;
VAL_ 256 ESC_CtlActiveTcs 1 "TCS control active" 0 "TCS control not active" ;
VAL_ 256 ESC_CtlActiveAbs 1 "ABS control active" 0 "ABS control not active" ;
VAL_ 256 ESC_Bls_Out 1 "BLS active or pressed" 0 "BLS inactive or not pressed" ;
VAL_ 256 ESC_HDC_Activated 1 "HDC function has been activated by driver" 0 "HDC function in inactive state" ;
VAL_ 256 ESC_ABS_Lamp 1 "ABS Fault" 0 "No Faults" ;
VAL_ 256 ESC_EBD_Lamp 1 "EBD Fault" 0 "No faults" ;
VAL_ 256 ESC_Lamp 1 "ESC Fault" 0 "No Faults" ;
VAL_ 256 ESC_RequestToEPB 3 "Lock Brake" 2 "Release Brake" 1 "No Request" 0 "Not Initialized" ;
VAL_ 256 ESC_TCS_Fault 1 "TCS Fault" 0 "No faults" ;
VAL_ 256 ESC_AVH_Active 1 "Active" 0 "Not Active" ;
VAL_ 256 ESC_CDPDecelAvailable 1 "Available" 0 "Not Available" ;
VAL_ 256 ESC_CtlActiveHDC 1 "HDC control active currently" 0 "HDC control not active" ;
VAL_ 256 ESC_CtlActiveEbd 1 "EBD control active" 0 "EBD control not active" ;
VAL_ 256 ESC_Passive_Lamp 1 "Passive lamp ON" 0 "Passive lamp OFF" ;
VAL_ 256 ESC_CtlActiveVdc 1 "VDC control currently active" 0 "VDC control not active" ;
VAL_ 256 ESC_EmergencyBraking 1 "Emergency braking" 0 "No emergency braking" ;
VAL_ 256 ESC_VehicleSpeed_ValueError 1 "Invalid value in vehicle speed signal" 0 "Valid value in vehicle speed signal" ;
VAL_ 256 ESC_Bla 1 "activate brake lights" ;
VAL_ 256 CddActive_2 1 "Active" 0 "Inactive" ;
VAL_ 256 ESC_Gearshift_Inhibit 1 "Inhibit gear shift" ;
VAL_ 130 ESC_WheelSpeed_RR 65535 "Invalid value" ;
VAL_ 130 ESC_WheelSpeed_ValueError_RR 1 "Invalid value in wheel speed rear right signal" 0 "Valid value in wheel speed rear right signal" ;
VAL_ 130 ESC_WheelSpeed_ValueError_RL 1 "Invalid value in wheel speed rear left signal" 0 "Valid value in wheel speed rear left signal" ;
VAL_ 130 ESC_WheelDirectionInfo_RR 3 "direction backward" 2 "direction forward" 1 "standstill" 0 "Direction not defined" ;
VAL_ 130 ESC_WheelSpeed_RL 65535 "Invalid value" ;
VAL_ 130 ESC_WheelDirectionInfo_RL 3 "direction backward" 2 "direction forward" 1 "standstill" 0 "Direction not defined" ;
VAL_ 129 ESC_WheelSpeed_FL 65535 "Invalid value" ;
VAL_ 129 ESC_WheelDirectionInfo_FL 3 "direction backward" 2 "direction forward" 1 "standstill" 0 "Direction not defined" ;
VAL_ 129 ESC_WheelSpeed_ValueError_FR 1 "Invalid value in wheel speed front right signal" 0 "Valid value in wheel speed front right signal" ;
VAL_ 129 ESC_WheelDirectionInfo_FR 3 "direction backward" 2 "direction forward" 1 "standstill" 0 "Direction not defined" ;
VAL_ 129 ESC_WheelSpeed_ValueError_FL 1 "Invalid value in wheel speed front left signal" 0 "Valid value in wheel speed front left signal" ;
VAL_ 129 ESC_WheelSpeed_FR 65535 "Invalid value" ;
VAL_ 354 DAS_AfsBrakeJerk_Req 1 "Requested" 0 "Not requested" ;
VAL_ 354 DAS_AebFuncError_Stat 1 "Error" 0 "No error" ;
VAL_ 354 DAS_AebRdaStand_Req 1 "Requested" 0 "Not requested" ;
VAL_ 354 DAS_CcFuncError_Stat 1 "Error" 0 "No error" ;
VAL_ 354 DAS_CcBrakeStandSt_Req 1 "Requested" 0 "Not requested" ;
VAL_ 354 DAS_CcBrakeRelease_Req 1 "Requested" 0 "Not requsted" ;
VAL_ 354 DAS_AebMode_Stat 1 "Active" 0 "Off" ;
VAL_ 354 DAS_CcMode_Stat 3 "Override" 2 "Active" 1 "Standby" 0 "Off" ;
VAL_ 354 DAS_AebDecelFlag_Req 1 "Requested" 0 "Not requsted" ;
VAL_ 354 DAS_AfsBrakeJerkEnab_Stat 1 "Enable" 0 "Disable" ;
VAL_ 354 DAS_CcDecelFlag_Req 1 "Requested" 0 "Not requested" ;
VAL_ 522 DAS_LkaSteeringMode_Stat 1 "Active" 0 "Inactive" ;
VAL_ 522 DAS_RctcDecelFlag_Req 1 "Request" 0 "Not request" ;
VAL_ 522 DAS_AccFuncError_Stat 1 "Error" 0 "No error" ;
VAL_ 522 DAS_RctcNotifError_Req 1 "Error" 0 "No error" ;
VAL_ 522 DAS_RctcFuncError_Stat 1 "Error" 0 "No error" ;
VAL_ 522 DAS_RctcMode_Stat 1 "Active" 0 "Off" ;
VAL_ 522 DAS_AfsNotifError_Req 1 "Error" 0 "No error" ;
VAL_ 522 DAS_ApaFuncError_Stat 1 "Error" 0 "No Error" ;
VAL_ 522 DAS_APAMode_Stat 1 "Move" 0 "Not move" ;
VAL_ 522 DAS_RsaAngleDirection_Req 3 "Same direction" 2 "Opposite direction" 1 "Zero position" 0 "No request" ;
VAL_ 522 DAS_LdpMode_Stat 1 "Active" 0 "Off" ;
VAL_ 522 DAS_LkaAngleFlag_Req 1 "Requested" 0 "Not requested" ;
VAL_ 522 DAS_AfsDecelFlag_Req 1 "Requested" 0 "Not requested" ;
VAL_ 522 DAS_AlccMode_Stat 1 "Active" 0 "Off" ;
VAL_ 522 DAS_AfsFuncError_Stat 1 "Error" 0 "No error" ;
VAL_ 522 DAS_LdwFuncError_Stat 1 "Error" 0 "No error" ;
VAL_ 522 DAS_AfsSos_Req 1 "Requested" 0 "Not requested" ;
VAL_ 522 DAS_LkaMode_Stat 3 "Active+TakeOver" 2 "Active" 1 "Standby" 0 "Off" ;
VAL_ 522 DAS_RdaMode_Stat 1 "On" 0 "Off" ;
VAL_ 522 DAS_AlccAngleFlag_Req 1 "Requested" 0 "Not requsted" ;
VAL_ 522 DAS_AfsEpb_Req 1 "Requested" 0 "Not requested" ;
VAL_ 522 DAS_AfsMode_Stat 1 "Active" 0 "Off" ;
VAL_ 522 DAS_LccFuncError_Stat 1 "Error" 0 "No error" ;
VAL_ 522 DAS_RdaDecelFlag_Req 1 "Requested" 0 "Not requested" ;
VAL_ 522 DAS_AfsExecute_Req 1 "Requested" 0 "Not requested" ;
VAL_ 522 DAS_RdaFuncError_Stat 1 "Error" 0 "No error" ;
VAL_ 522 DAS_LkaFuncError_Stat 1 "Error" 0 "No error" ;
VAL_ 522 DAS_LdpAngleFlag_Req 1 "Requsted" 0 "Not requested" ;
VAL_ 522 DAS_ApaAngleFlag_Req 1 "Requested" 0 "Not requested" ;
VAL_ 352 DAS_AebPrefill_Req 1 "Requested" 0 "Not Requested" ;
VAL_ 352 DAS_CcBrakeLight_Req 1 "Requested" 0 "Not requested" ;
VAL_ 352 DAS_AebPreCrash_Req 1 "Requested" 0 "Not requested" ;
VAL_ 352 DAS_AebBoost_Req 1 "Request" 0 "No Request" ;
VAL_ 658 DAS_LeftProjBrightSlot1_Req 7 "Error" 6 "100%" 5 "85%" 4 "60" 3 "40%" 2 "25%" 1 "10%" 0 "Off" ;
VAL_ 658 DAS_LeftProjSlot1_Req 101 "Error" 100 "Pedestrian Marker Position 100" 99 "Pedestrian Marker Position 99" 98 "Pedestrian Marker Position 98" 97 "Pedestrian Marker Position 97" 96 "Pedestrian Marker Position 96" 95 "Pedestrian Marker Position 95" 94 "Pedestrian Marker Position 94" 93 "Pedestrian Marker Position 93" 92 "Pedestrian Marker Position 92" 91 "Pedestrian Marker Position 91" 90 "Pedestrian Marker Position 90" 89 "Pedestrian Marker Position 89" 88 "Pedestrian Marker Position 88" 87 "Pedestrian Marker Position 87" 86 "Pedestrian Marker Position 86" 85 "Pedestrian Marker Position 85" 84 "Pedestrian Marker Position 84" 83 "Pedestrian Marker Position 83" 82 "Pedestrian Marker Position 82" 81 "Pedestrian Marker Position 81" 80 "Pedestrian Marker Position 80" 79 "Pedestrian Marker Position 79" 78 "Pedestrian Marker Position 78" 77 "Pedestrian Marker Position 77" 76 "Pedestrian Marker Position 76" 75 "Pedestrian Marker Position 75" 74 "Pedestrian Marker Position 74" 73 "Pedestrian Marker Position 73" 72 "Pedestrian Marker Position 72" 71 "Pedestrian Marker Position 71" 70 "Pedestrian Marker Position 70" 69 "Pedestrian Marker Position 69" 68 "Pedestrian Marker Position 68" 67 "Pedestrian Marker Position 67" 66 "Pedestrian Marker Position 66" 65 "Pedestrian Marker Position 65" 64 "Pedestrian Marker Position 64" 63 "Pedestrian Marker Position 63" 62 "Pedestrian Marker Position 62" 61 "Pedestrian Marker Position 61" 60 "Pedestrian Marker Position 60" 59 "Pedestrian Marker Position 59" 58 "Pedestrian Marker Position 58" 57 "Pedestrian Marker Position 57" 56 "Pedestrian Marker Position 56" 55 "Pedestrian Marker Position 55" 54 "Pedestrian Marker Position 54" 53 "Pedestrian Marker Position 53" 52 "Pedestrian Marker Position 52" 51 "Pedestrian Marker Position 51" 50 "Pedestrian Marker Position 50" 49 "Pedestrian Marker Position 49" 48 "Pedestrian Marker Position 48" 47 "Pedestrian Marker Position 47" 46 "Pedestrian Marker Position 46" 45 "Pedestrian Marker Position 45" 44 "Pedestrian Marker Position 44" 43 "Pedestrian Marker Position 43" 42 "Pedestrian Marker Position 42" 41 "Pedestrian Marker Position 41" 40 "Pedestrian Marker Position 40" 39 "Pedestrian Marker Position 39" 38 "Pedestrian Marker Position 38" 37 "Pedestrian Marker Position 37" 36 "Pedestrian Marker Position 36" 35 "Pedestrian Marker Position 35" 34 "Pedestrian Marker Position 34" 33 "Pedestrian Marker Position 33" 32 "Pedestrian Marker Position 32" 31 "Pedestrian Marker Position 31" 30 "Pedestrian Marker Position 30" 29 "Pedestrian Marker Position 29" 28 "Pedestrian Marker Position 28" 27 "Pedestrian Marker Position 27" 26 "Pedestrian Marker Position 26" 25 "Pedestrian Marker Position 25" 24 "Pedestrian Marker Position 24" 23 "Pedestrian Marker Position 23" 22 "Pedestrian Marker Position 22" 21 "Pedestrian Marker Position 21" 20 "Pedestrian Marker Position 20" 19 "Pedestrian Marker Position 19" 18 "Pedestrian Marker Position 18" 17 "Pedestrian Marker Position 17" 16 "Pedestrian Marker Position 16" 15 "Pedestrian Marker Position 15" 14 "Pedestrian Marker Position 14" 13 "Pedestrian Marker Position 13" 12 "Pedestrian Marker Position 12" 11 "Pedestrian Marker Position 11" 10 "Pedestrian Marker Position 10" 9 "Pedestrian Marker Position 9" 8 "Pedestrian Marker Position 8" 7 "Pedestrian Marker Position 7" 6 "Pedestrian Marker Position 6" 5 "Pedestrian Marker Position 5" 4 "Pedestrian Marker Position 4" 3 "Pedestrian Marker Position 3" 2 "Pedestrian Marker Position 2" 1 "Pedestrian Marker Position 1" 0 "Off" ;
VAL_ 658 DAS_LeftProjSlot4_Req 15 "Error" 14 "Projection Function 42" 13 "Projection Function 41" 12 "Projection Function 40" 11 "Projection Function 39" 10 "Projection Function 38" 9 "Projection Function 37" 8 "Projection Function Position 36" 7 "Projection Function 35" 6 "Projection Function 34" 5 "Projection Function 33" 4 "Projection Function 32" 3 "Projection Function 31" 2 "Projection Function 30" 1 "Projection Function 29" 0 "Off" ;
VAL_ 658 DAS_RightProjBrightSlot3_Req 7 "Error" 6 "100%" 5 "85%" 4 "60%" 3 "40%" 2 "25%" 1 "10%" 0 "Off" ;
VAL_ 658 DAS_RightProjSlot3_Req 15 "Error" 14 "Projection Function 28" 13 "Projection Function 27" 12 "Projection Function 26" 11 "Pedestrian Marker Position 25" 10 "Projection Function 24" 9 "Projection Function 23" 8 "Projection Function 22" 7 "Projection Function 21" 6 "Projection Function 20" 5 "Projection Function 19" 4 "Projection Function 18" 3 "Projection Function 17" 2 "Projection Function 16" 1 "Projection Function 15" 0 "Off" ;
VAL_ 658 DAS_RightProjBrightSlot4_Req 7 "Error" 6 "100%" 5 "85%" 4 "60%" 3 "40%" 2 "25%" 1 "10%" 0 "Off" ;
VAL_ 658 DAS_LeftProjBrightSlot3_Req 7 "Error" 6 "100%" 5 "85%" 4 "60%" 3 "40%" 2 "25%" 1 "10%" 0 "Off" ;
VAL_ 658 DAS_LeftProjBrightSlot2_Req 7 "Error" 6 "100%" 5 "85%" 4 "60%" 3 "40%" 2 "25%" 1 "10%" 0 "Off" ;
VAL_ 658 DAS_RightProjBrightSlot2_Req 7 "Error" 6 "100%" 5 "85%" 4 "60%" 3 "40%" 2 "25%" 1 "10%" 0 "Off" ;
VAL_ 658 DAS_LeftProjSlot3_Req 15 "Error" 14 "Projection Function 28" 13 "Projection Function 27" 12 "Projection Function 26" 11 "Pedestrian Marker Position 25" 10 "Projection Function 24" 9 "Projection Function 23" 8 "Projection Function 22" 7 "Projection Function 21" 6 "Projection Function 20" 5 "Projection Function 19" 4 "Projection Function 18" 3 "Projection Function 17" 2 "Projection Function 16" 1 "Projection Function 15" 0 "Off" ;
VAL_ 658 DAS_RightProjSlot1_Req 101 "Error" 100 "Pedestrian Marker Position 100" 99 "Pedestrian Marker Position 99" 98 "Pedestrian Marker Position 98" 97 "Pedestrian Marker Position 97" 96 "Pedestrian Marker Position 96" 95 "Pedestrian Marker Position 95" 94 "Pedestrian Marker Position 94" 93 "Pedestrian Marker Position 93" 92 "Pedestrian Marker Position 92" 91 "Pedestrian Marker Position 91" 90 "Pedestrian Marker Position 90" 89 "Pedestrian Marker Position 89" 88 "Pedestrian Marker Position 88" 87 "Pedestrian Marker Position 87" 86 "Pedestrian Marker Position 86" 85 "Pedestrian Marker Position 85" 84 "Pedestrian Marker Position 84" 83 "Pedestrian Marker Position 83" 82 "Pedestrian Marker Position 82" 81 "Pedestrian Marker Position 81" 80 "Pedestrian Marker Position 80" 79 "Pedestrian Marker Position 79" 78 "Pedestrian Marker Position 78" 77 "Pedestrian Marker Position 77" 76 "Pedestrian Marker Position 76" 75 "Pedestrian Marker Position 75" 74 "Pedestrian Marker Position 74" 73 "Pedestrian Marker Position 73" 72 "Pedestrian Marker Position 72" 71 "Pedestrian Marker Position 71" 70 "Pedestrian Marker Position 70" 69 "Pedestrian Marker Position 69" 68 "Pedestrian Marker Position 68" 67 "Pedestrian Marker Position 67" 66 "Pedestrian Marker Position 66" 65 "Pedestrian Marker Position 65" 64 "Pedestrian Marker Position 64" 63 "Pedestrian Marker Position 63" 62 "Pedestrian Marker Position 62" 61 "Pedestrian Marker Position 61" 60 "Pedestrian Marker Position 60" 59 "Pedestrian Marker Position 59" 58 "Pedestrian Marker Position 58" 57 "Pedestrian Marker Position 57" 56 "Pedestrian Marker Position 56" 55 "Pedestrian Marker Position 55" 54 "Pedestrian Marker Position 54" 53 "Pedestrian Marker Position 53" 52 "Pedestrian Marker Position 52" 51 "Pedestrian Marker Position 51" 50 "Pedestrian Marker Position 50" 49 "Pedestrian Marker Position 49" 48 "Pedestrian Marker Position 48" 47 "Pedestrian Marker Position 47" 46 "Pedestrian Marker Position 46" 45 "Pedestrian Marker Position 45" 44 "Pedestrian Marker Position 44" 43 "Pedestrian Marker Position 43" 42 "Pedestrian Marker Position 42" 41 "Pedestrian Marker Position 41" 40 "Pedestrian Marker Position 40" 39 "Pedestrian Marker Position 39" 38 "Pedestrian Marker Position 38" 37 "Pedestrian Marker Position 37" 36 "Pedestrian Marker Position 36" 35 "Pedestrian Marker Position 35" 34 "Pedestrian Marker Position 34" 33 "Pedestrian Marker Position 33" 32 "Pedestrian Marker Position 32" 31 "Pedestrian Marker Position 31" 30 "Pedestrian Marker Position 30" 29 "Pedestrian Marker Position 29" 28 "Pedestrian Marker Position 28" 27 "Pedestrian Marker Position 27" 26 "Pedestrian Marker Position 26" 25 "Pedestrian Marker Position 25" 24 "Pedestrian Marker Position 24" 23 "Pedestrian Marker Position 23" 22 "Pedestrian Marker Position 22" 21 "Pedestrian Marker Position 21" 20 "Pedestrian Marker Position 20" 19 "Pedestrian Marker Position 19" 18 "Pedestrian Marker Position 18" 17 "Pedestrian Marker Position 17" 16 "Pedestrian Marker Position 16" 15 "Pedestrian Marker Position 15" 14 "Pedestrian Marker Position 14" 13 "Pedestrian Marker Position 13" 12 "Pedestrian Marker Position 12" 11 "Pedestrian Marker Position 11" 10 "Pedestrian Marker Position 10" 9 "Pedestrian Marker Position 9" 8 "Pedestrian Marker Position 8" 7 "Pedestrian Marker Position 7" 6 "Pedestrian Marker Position 6" 5 "Pedestrian Marker Position 5" 4 "Pedestrian Marker Position 4" 3 "Pedestrian Marker Position 3" 2 "Pedestrian Marker Position 2" 1 "Pedestrian Marker Position 1" 0 "Off" ;
VAL_ 658 DAS_LeftProjSlot2_Req 15 "Error" 14 "Projection Function 14" 13 "Projection Function 13" 12 "Projection Function 12" 11 "Projection Function 11" 10 "Projection Function 10" 9 "Projection Function 9" 8 "Projection Function Position 8" 7 "Projection Function 7" 6 "Projection Function 6" 5 "Projection Function 5" 4 "Projection Function 4" 3 "Projection Function 3" 2 "Projection Function 2" 1 "Projection Function 1" 0 "Off" ;
VAL_ 658 DAS_LeftProjBrightSlot4_Req 7 "Error" 6 "100%" 5 "85%" 4 "60%" 3 "40%" 2 "25%" 1 "10%" 0 "Off" ;
VAL_ 658 DAS_RightProjSlot4_Req 15 "Error" 14 "Projection Function 42" 13 "Projection Function 41" 12 "Projection Function 40" 11 "Projection Function 39" 10 "Projection Function 38" 9 "Projection Function 37" 8 "Projection Function Position 36" 7 "Projection Function 35" 6 "Projection Function 34" 5 "Projection Function 33" 4 "Projection Function 32" 3 "Projection Function 31" 2 "Projection Function 30" 1 "Projection Function 29" 0 "Off" ;
VAL_ 658 DAS_RightProjBrightSlot1_Req 7 "Error" 6 "100%" 5 "85%" 4 "60%" 3 "40%" 2 "25%" 1 "10%" 0 "Off" ;
VAL_ 658 DAS_RightProjSlot2_Req 15 "Error" 14 "Projection Function 14" 13 "Projection Function 13" 12 "Projection Function 12" 11 "Projection Function 11" 10 "Projection Function 10" 9 "Projection Function 9" 8 "Projection Function Position 8" 7 "Projection Function 7" 6 "Projection Function 6" 5 "Projection Function 5" 4 "Projection Function 4" 3 "Projection Function 3" 2 "Projection Function 2" 1 "Projection Function 1" 0 "Off" ;
VAL_ 657 DAS_RightObj_1_Y_2_Val 321 "Error" 320 "320" 319 "319" 318 "318" 317 "317" 316 "316" 315 "315" 314 "314" 313 "313" 312 "312" 311 "311" 310 "310" 309 "309" 308 "308" 307 "307" 306 "306" 305 "305" 304 "304" 303 "303" 302 "302" 301 "301" 300 "300" 299 "299" 298 "298" 297 "297" 296 "296" 295 "295" 294 "294" 293 "293" 292 "292" 291 "291" 290 "290" 289 "289" 288 "288" 287 "287" 286 "286" 285 "285" 284 "284" 283 "283" 282 "282" 281 "281" 280 "280" 279 "279" 278 "278" 277 "277" 276 "276" 275 "275" 274 "274" 273 "273" 272 "272" 271 "271" 270 "270" 269 "269" 268 "268" 267 "267" 266 "266" 265 "265" 264 "264" 263 "263" 262 "262" 261 "261" 260 "260" 259 "259" 258 "258" 257 "257" 256 "256" 255 "255" 254 "254" 253 "253" 252 "252" 251 "251" 250 "250" 249 "249" 248 "248" 247 "247" 246 "246" 245 "245" 244 "244" 243 "243" 242 "242" 241 "241" 240 "240" 239 "239" 238 "238" 237 "237" 236 "236" 235 "235" 234 "234" 233 "233" 232 "232" 231 "231" 230 "230" 229 "229" 228 "228" 227 "227" 226 "226" 225 "225" 224 "224" 223 "223" 222 "222" 221 "221" 220 "220" 219 "219" 218 "218" 217 "217" 216 "216" 215 "215" 214 "214" 213 "213" 212 "212" 211 "211" 210 "210" 209 "209" 208 "208" 207 "207" 206 "206" 205 "205" 204 "204" 203 "203" 202 "202" 201 "201" 200 "200" 199 "199" 198 "198" 197 "197" 196 "196" 195 "195" 194 "194" 193 "193" 192 "192" 191 "191" 190 "190" 189 "189" 188 "188" 187 "187" 186 "186" 185 "185" 184 "184" 183 "183" 182 "182" 181 "181" 180 "180" 179 "179" 178 "178" 177 "177" 176 "176" 175 "175" 174 "174" 173 "173" 172 "172" 171 "171" 170 "170" 169 "169" 168 "168" 167 "167" 166 "166" 165 "165" 164 "164" 163 "163" 162 "162" 161 "161" 160 "160" 159 "159" 158 "158" 157 "157" 156 "156" 155 "155" 154 "154" 153 "153" 152 "152" 151 "151" 150 "150" 149 "149" 148 "148" 147 "147" 146 "146" 145 "145" 144 "144" 143 "143" 142 "142" 141 "141" 140 "140" 139 "139" 138 "138" 137 "137" 136 "136" 135 "135" 134 "134" 133 "133" 132 "132" 131 "131" 130 "130" 129 "129" 128 "128" 127 "127" 126 "126" 125 "125" 124 "124" 123 "123" 122 "122" 121 "121" 120 "120" 119 "119" 118 "118" 117 "117" 116 "116" 115 "115" 114 "114" 113 "113" 112 "112" 111 "111" 110 "110" 109 "109" 108 "108" 107 "107" 106 "106" 105 "105" 104 "104" 103 "103" 102 "102" 101 "101" 100 "100" 99 "99" 98 "98" 97 "97" 96 "96" 95 "95" 94 "94" 93 "93" 92 "92" 91 "91" 90 "90" 89 "89" 88 "88" 87 "87" 86 "86" 85 "85" 84 "84" 83 "83" 82 "82" 81 "81" 80 "80" 79 "79" 78 "78" 77 "77" 76 "76" 75 "75" 74 "74" 73 "73" 72 "72" 71 "71" 70 "70" 69 "69" 68 "68" 67 "67" 66 "66" 65 "65" 64 "64" 63 "63" 62 "62" 61 "61" 60 "60" 59 "59" 58 "58" 57 "57" 56 "56" 55 "55" 54 "54" 53 "53" 52 "52" 51 "51" 50 "50" 49 "49" 48 "48" 47 "47" 46 "46" 45 "45" 44 "44" 43 "43" 42 "42" 41 "41" 40 "40" 39 "39" 38 "38" 37 "37" 36 "36" 35 "35" 34 "34" 33 "33" 32 "32" 31 "31" 30 "30" 29 "29" 28 "28" 27 "27" 26 "26" 25 "25" 24 "24" 23 "23" 22 "22" 21 "21" 20 "20" 19 "19" 18 "18" 17 "17" 16 "16" 15 "15" 14 "14" 13 "13" 12 "12" 11 "11" 10 "10" 9 "9" 8 "8" 7 "7" 6 "6" 5 "5" 4 "4" 3 "3" 2 "2" 1 "1" 0 "Unknown" ;
VAL_ 657 DAS_RightObj_3_Y_2_Val 321 "Error" 320 "320" 319 "319" 318 "318" 317 "317" 316 "316" 315 "315" 314 "314" 313 "313" 312 "312" 311 "311" 310 "310" 309 "309" 308 "308" 307 "307" 306 "306" 305 "305" 304 "304" 303 "303" 302 "302" 301 "301" 300 "300" 299 "299" 298 "298" 297 "297" 296 "296" 295 "295" 294 "294" 293 "293" 292 "292" 291 "291" 290 "290" 289 "289" 288 "288" 287 "287" 286 "286" 285 "285" 284 "284" 283 "283" 282 "282" 281 "281" 280 "280" 279 "279" 278 "278" 277 "277" 276 "276" 275 "275" 274 "274" 273 "273" 272 "272" 271 "271" 270 "270" 269 "269" 268 "268" 267 "267" 266 "266" 265 "265" 264 "264" 263 "263" 262 "262" 261 "261" 260 "260" 259 "259" 258 "258" 257 "257" 256 "256" 255 "255" 254 "254" 253 "253" 252 "252" 251 "251" 250 "250" 249 "249" 248 "248" 247 "247" 246 "246" 245 "245" 244 "244" 243 "243" 242 "242" 241 "241" 240 "240" 239 "239" 238 "238" 237 "237" 236 "236" 235 "235" 234 "234" 233 "233" 232 "232" 231 "231" 230 "230" 229 "229" 228 "228" 227 "227" 226 "226" 225 "225" 224 "224" 223 "223" 222 "222" 221 "221" 220 "220" 219 "219" 218 "218" 217 "217" 216 "216" 215 "215" 214 "214" 213 "213" 212 "212" 211 "211" 210 "210" 209 "209" 208 "208" 207 "207" 206 "206" 205 "205" 204 "204" 203 "203" 202 "202" 201 "201" 200 "200" 199 "199" 198 "198" 197 "197" 196 "196" 195 "195" 194 "194" 193 "193" 192 "192" 191 "191" 190 "190" 189 "189" 188 "188" 187 "187" 186 "186" 185 "185" 184 "184" 183 "183" 182 "182" 181 "181" 180 "180" 179 "179" 178 "178" 177 "177" 176 "176" 175 "175" 174 "174" 173 "173" 172 "172" 171 "171" 170 "170" 169 "169" 168 "168" 167 "167" 166 "166" 165 "165" 164 "164" 163 "163" 162 "162" 161 "161" 160 "160" 159 "159" 158 "158" 157 "157" 156 "156" 155 "155" 154 "154" 153 "153" 152 "152" 151 "151" 150 "150" 149 "149" 148 "148" 147 "147" 146 "146" 145 "145" 144 "144" 143 "143" 142 "142" 141 "141" 140 "140" 139 "139" 138 "138" 137 "137" 136 "136" 135 "135" 134 "134" 133 "133" 132 "132" 131 "131" 130 "130" 129 "129" 128 "128" 127 "127" 126 "126" 125 "125" 124 "124" 123 "123" 122 "122" 121 "121" 120 "120" 119 "119" 118 "118" 117 "117" 116 "116" 115 "115" 114 "114" 113 "113" 112 "112" 111 "111" 110 "110" 109 "109" 108 "108" 107 "107" 106 "106" 105 "105" 104 "104" 103 "103" 102 "102" 101 "101" 100 "100" 99 "99" 98 "98" 97 "97" 96 "96" 95 "95" 94 "94" 93 "93" 92 "92" 91 "91" 90 "90" 89 "89" 88 "88" 87 "87" 86 "86" 85 "85" 84 "84" 83 "83" 82 "82" 81 "81" 80 "80" 79 "79" 78 "78" 77 "77" 76 "76" 75 "75" 74 "74" 73 "73" 72 "72" 71 "71" 70 "70" 69 "69" 68 "68" 67 "67" 66 "66" 65 "65" 64 "64" 63 "63" 62 "62" 61 "61" 60 "60" 59 "59" 58 "58" 57 "57" 56 "56" 55 "55" 54 "54" 53 "53" 52 "52" 51 "51" 50 "50" 49 "49" 48 "48" 47 "47" 46 "46" 45 "45" 44 "44" 43 "43" 42 "42" 41 "41" 40 "40" 39 "39" 38 "38" 37 "37" 36 "36" 35 "35" 34 "34" 33 "33" 32 "32" 31 "31" 30 "30" 29 "29" 28 "28" 27 "27" 26 "26" 25 "25" 24 "24" 23 "23" 22 "22" 21 "21" 20 "20" 19 "19" 18 "18" 17 "17" 16 "16" 15 "15" 14 "14" 13 "13" 12 "12" 11 "11" 10 "10" 9 "9" 8 "8" 7 "7" 6 "6" 5 "5" 4 "4" 3 "3" 2 "2" 1 "1" 0 "Unknown" ;
VAL_ 657 DAS_ADBRightLED5_Req 1 "On" 0 "Off" ;
VAL_ 657 DAS_ADBRightLED1_Req 1 "On" 0 "Off" ;
VAL_ 657 DAS_RightObj_5_Z_2_Val 81 "Error" 80 "80" 79 "79" 78 "78" 77 "77" 76 "76" 75 "75" 74 "74" 73 "73" 72 "72" 71 "71" 70 "70" 69 "69" 68 "68" 67 "67" 66 "66" 65 "65" 64 "64" 63 "63" 62 "62" 61 "61" 60 "60" 59 "59" 58 "58" 57 "57" 56 "56" 55 "55" 54 "54" 53 "53" 52 "52" 51 "51" 50 "50" 49 "49" 48 "48" 47 "47" 46 "46" 45 "45" 44 "44" 43 "43" 42 "42" 41 "41" 40 "40" 39 "39" 38 "38" 37 "37" 36 "36" 35 "35" 34 "34" 33 "33" 32 "32" 31 "31" 30 "30" 29 "29" 28 "28" 27 "27" 26 "26" 25 "25" 24 "24" 23 "23" 22 "22" 21 "21" 20 "20" 19 "19" 18 "18" 17 "17" 16 "16" 15 "15" 14 "14" 13 "13" 12 "12" 11 "11" 10 "10" 9 "9" 8 "8" 7 "7" 6 "6" 5 "5" 4 "4" 3 "3" 2 "2" 1 "1" 0 "Unknown" ;
VAL_ 657 DAS_RightObj_7_Z_2_Val 81 "Error" 80 "80" 79 "79" 78 "78" 77 "77" 76 "76" 75 "75" 74 "74" 73 "73" 72 "72" 71 "71" 70 "70" 69 "69" 68 "68" 67 "67" 66 "66" 65 "65" 64 "64" 63 "63" 62 "62" 61 "61" 60 "60" 59 "59" 58 "58" 57 "57" 56 "56" 55 "55" 54 "54" 53 "53" 52 "52" 51 "51" 50 "50" 49 "49" 48 "48" 47 "47" 46 "46" 45 "45" 44 "44" 43 "43" 42 "42" 41 "41" 40 "40" 39 "39" 38 "38" 37 "37" 36 "36" 35 "35" 34 "34" 33 "33" 32 "32" 31 "31" 30 "30" 29 "29" 28 "28" 27 "27" 26 "26" 25 "25" 24 "24" 23 "23" 22 "22" 21 "21" 20 "20" 19 "19" 18 "18" 17 "17" 16 "16" 15 "15" 14 "14" 13 "13" 12 "12" 11 "11" 10 "10" 9 "9" 8 "8" 7 "7" 6 "6" 5 "5" 4 "4" 3 "3" 2 "2" 1 "1" 0 "Unknown" ;
VAL_ 657 DAS_RightObj_9_Z_2_Val 81 "Error" 80 "80" 79 "79" 78 "78" 77 "77" 76 "76" 75 "75" 74 "74" 73 "73" 72 "72" 71 "71" 70 "70" 69 "69" 68 "68" 67 "67" 66 "66" 65 "65" 64 "64" 63 "63" 62 "62" 61 "61" 60 "60" 59 "59" 58 "58" 57 "57" 56 "56" 55 "55" 54 "54" 53 "53" 52 "52" 51 "51" 50 "50" 49 "49" 48 "48" 47 "47" 46 "46" 45 "45" 44 "44" 43 "43" 42 "42" 41 "41" 40 "40" 39 "39" 38 "38" 37 "37" 36 "36" 35 "35" 34 "34" 33 "33" 32 "32" 31 "31" 30 "30" 29 "29" 28 "28" 27 "27" 26 "26" 25 "25" 24 "24" 23 "23" 22 "22" 21 "21" 20 "20" 19 "19" 18 "18" 17 "17" 16 "16" 15 "15" 14 "14" 13 "13" 12 "12" 11 "11" 10 "10" 9 "9" 8 "8" 7 "7" 6 "6" 5 "5" 4 "4" 3 "3" 2 "2" 1 "1" 0 "Unknown" ;
VAL_ 657 DAS_RightObj_8_Y_1_Val 321 "Error" 320 "320" 319 "319" 318 "318" 317 "317" 316 "316" 315 "315" 314 "314" 313 "313" 312 "312" 311 "311" 310 "310" 309 "309" 308 "308" 307 "307" 306 "306" 305 "305" 304 "304" 303 "303" 302 "302" 301 "301" 300 "300" 299 "299" 298 "298" 297 "297" 296 "296" 295 "295" 294 "294" 293 "293" 292 "292" 291 "291" 290 "290" 289 "289" 288 "288" 287 "287" 286 "286" 285 "285" 284 "284" 283 "283" 282 "282" 281 "281" 280 "280" 279 "279" 278 "278" 277 "277" 276 "276" 275 "275" 274 "274" 273 "273" 272 "272" 271 "271" 270 "270" 269 "269" 268 "268" 267 "267" 266 "266" 265 "265" 264 "264" 263 "263" 262 "262" 261 "261" 260 "260" 259 "259" 258 "258" 257 "257" 256 "256" 255 "255" 254 "254" 253 "253" 252 "252" 251 "251" 250 "250" 249 "249" 248 "248" 247 "247" 246 "246" 245 "245" 244 "244" 243 "243" 242 "242" 241 "241" 240 "240" 239 "239" 238 "238" 237 "237" 236 "236" 235 "235" 234 "234" 233 "233" 232 "232" 231 "231" 230 "230" 229 "229" 228 "228" 227 "227" 226 "226" 225 "225" 224 "224" 223 "223" 222 "222" 221 "221" 220 "220" 219 "219" 218 "218" 217 "217" 216 "216" 215 "215" 214 "214" 213 "213" 212 "212" 211 "211" 210 "210" 209 "209" 208 "208" 207 "207" 206 "206" 205 "205" 204 "204" 203 "203" 202 "202" 201 "201" 200 "200" 199 "199" 198 "198" 197 "197" 196 "196" 195 "195" 194 "194" 193 "193" 192 "192" 191 "191" 190 "190" 189 "189" 188 "188" 187 "187" 186 "186" 185 "185" 184 "184" 183 "183" 182 "182" 181 "181" 180 "180" 179 "179" 178 "178" 177 "177" 176 "176" 175 "175" 174 "174" 173 "173" 172 "172" 171 "171" 170 "170" 169 "169" 168 "168" 167 "167" 166 "166" 165 "165" 164 "164" 163 "163" 162 "162" 161 "161" 160 "160" 159 "159" 158 "158" 157 "157" 156 "156" 155 "155" 154 "154" 153 "153" 152 "152" 151 "151" 150 "150" 149 "149" 148 "148" 147 "147" 146 "146" 145 "145" 144 "144" 143 "143" 142 "142" 141 "141" 140 "140" 139 "139" 138 "138" 137 "137" 136 "136" 135 "135" 134 "134" 133 "133" 132 "132" 131 "131" 130 "130" 129 "129" 128 "128" 127 "127" 126 "126" 125 "125" 124 "124" 123 "123" 122 "122" 121 "121" 120 "120" 119 "119" 118 "118" 117 "117" 116 "116" 115 "115" 114 "114" 113 "113" 112 "112" 111 "111" 110 "110" 109 "109" 108 "108" 107 "107" 106 "106" 105 "105" 104 "104" 103 "103" 102 "102" 101 "101" 100 "100" 99 "99" 98 "98" 97 "97" 96 "96" 95 "95" 94 "94" 93 "93" 92 "92" 91 "91" 90 "90" 89 "89" 88 "88" 87 "87" 86 "86" 85 "85" 84 "84" 83 "83" 82 "82" 81 "81" 80 "80" 79 "79" 78 "78" 77 "77" 76 "76" 75 "75" 74 "74" 73 "73" 72 "72" 71 "71" 70 "70" 69 "69" 68 "68" 67 "67" 66 "66" 65 "65" 64 "64" 63 "63" 62 "62" 61 "61" 60 "60" 59 "59" 58 "58" 57 "57" 56 "56" 55 "55" 54 "54" 53 "53" 52 "52" 51 "51" 50 "50" 49 "49" 48 "48" 47 "47" 46 "46" 45 "45" 44 "44" 43 "43" 42 "42" 41 "41" 40 "40" 39 "39" 38 "38" 37 "37" 36 "36" 35 "35" 34 "34" 33 "33" 32 "32" 31 "31" 30 "30" 29 "29" 28 "28" 27 "27" 26 "26" 25 "25" 24 "24" 23 "23" 22 "22" 21 "21" 20 "20" 19 "19" 18 "18" 17 "17" 16 "16" 15 "15" 14 "14" 13 "13" 12 "12" 11 "11" 10 "10" 9 "9" 8 "8" 7 "7" 6 "6" 5 "5" 4 "4" 3 "3" 2 "2" 1 "1" 0 "Unknown" ;
VAL_ 657 DAS_ADBRightLED6_Req 1 "On" 0 "Off" ;
VAL_ 657 DAS_RightObj_9_Y_2_Val 321 "Error" 320 "320" 319 "319" 318 "318" 317 "317" 316 "316" 315 "315" 314 "314" 313 "313" 312 "312" 311 "311" 310 "310" 309 "309" 308 "308" 307 "307" 306 "306" 305 "305" 304 "304" 303 "303" 302 "302" 301 "301" 300 "300" 299 "299" 298 "298" 297 "297" 296 "296" 295 "295" 294 "294" 293 "293" 292 "292" 291 "291" 290 "290" 289 "289" 288 "288" 287 "287" 286 "286" 285 "285" 284 "284" 283 "283" 282 "282" 281 "281" 280 "280" 279 "279" 278 "278" 277 "277" 276 "276" 275 "275" 274 "274" 273 "273" 272 "272" 271 "271" 270 "270" 269 "269" 268 "268" 267 "267" 266 "266" 265 "265" 264 "264" 263 "263" 262 "262" 261 "261" 260 "260" 259 "259" 258 "258" 257 "257" 256 "256" 255 "255" 254 "254" 253 "253" 252 "252" 251 "251" 250 "250" 249 "249" 248 "248" 247 "247" 246 "246" 245 "245" 244 "244" 243 "243" 242 "242" 241 "241" 240 "240" 239 "239" 238 "238" 237 "237" 236 "236" 235 "235" 234 "234" 233 "233" 232 "232" 231 "231" 230 "230" 229 "229" 228 "228" 227 "227" 226 "226" 225 "225" 224 "224" 223 "223" 222 "222" 221 "221" 220 "220" 219 "219" 218 "218" 217 "217" 216 "216" 215 "215" 214 "214" 213 "213" 212 "212" 211 "211" 210 "210" 209 "209" 208 "208" 207 "207" 206 "206" 205 "205" 204 "204" 203 "203" 202 "202" 201 "201" 200 "200" 199 "199" 198 "198" 197 "197" 196 "196" 195 "195" 194 "194" 193 "193" 192 "192" 191 "191" 190 "190" 189 "189" 188 "188" 187 "187" 186 "186" 185 "185" 184 "184" 183 "183" 182 "182" 181 "181" 180 "180" 179 "179" 178 "178" 177 "177" 176 "176" 175 "175" 174 "174" 173 "173" 172 "172" 171 "171" 170 "170" 169 "169" 168 "168" 167 "167" 166 "166" 165 "165" 164 "164" 163 "163" 162 "162" 161 "161" 160 "160" 159 "159" 158 "158" 157 "157" 156 "156" 155 "155" 154 "154" 153 "153" 152 "152" 151 "151" 150 "150" 149 "149" 148 "148" 147 "147" 146 "146" 145 "145" 144 "144" 143 "143" 142 "142" 141 "141" 140 "140" 139 "139" 138 "138" 137 "137" 136 "136" 135 "135" 134 "134" 133 "133" 132 "132" 131 "131" 130 "130" 129 "129" 128 "128" 127 "127" 126 "126" 125 "125" 124 "124" 123 "123" 122 "122" 121 "121" 120 "120" 119 "119" 118 "118" 117 "117" 116 "116" 115 "115" 114 "114" 113 "113" 112 "112" 111 "111" 110 "110" 109 "109" 108 "108" 107 "107" 106 "106" 105 "105" 104 "104" 103 "103" 102 "102" 101 "101" 100 "100" 99 "99" 98 "98" 97 "97" 96 "96" 95 "95" 94 "94" 93 "93" 92 "92" 91 "91" 90 "90" 89 "89" 88 "88" 87 "87" 86 "86" 85 "85" 84 "84" 83 "83" 82 "82" 81 "81" 80 "80" 79 "79" 78 "78" 77 "77" 76 "76" 75 "75" 74 "74" 73 "73" 72 "72" 71 "71" 70 "70" 69 "69" 68 "68" 67 "67" 66 "66" 65 "65" 64 "64" 63 "63" 62 "62" 61 "61" 60 "60" 59 "59" 58 "58" 57 "57" 56 "56" 55 "55" 54 "54" 53 "53" 52 "52" 51 "51" 50 "50" 49 "49" 48 "48" 47 "47" 46 "46" 45 "45" 44 "44" 43 "43" 42 "42" 41 "41" 40 "40" 39 "39" 38 "38" 37 "37" 36 "36" 35 "35" 34 "34" 33 "33" 32 "32" 31 "31" 30 "30" 29 "29" 28 "28" 27 "27" 26 "26" 25 "25" 24 "24" 23 "23" 22 "22" 21 "21" 20 "20" 19 "19" 18 "18" 17 "17" 16 "16" 15 "15" 14 "14" 13 "13" 12 "12" 11 "11" 10 "10" 9 "9" 8 "8" 7 "7" 6 "6" 5 "5" 4 "4" 3 "3" 2 "2" 1 "1" 0 "Unknown" ;
VAL_ 657 DAS_ADBRightLED10_Req 1 "On" 0 "Off" ;
VAL_ 657 DAS_ADBRightLED16_Req 1 "On" 0 "Off" ;
VAL_ 657 DAS_ADBRightLED11_Req 1 "On" 0 "Off" ;
VAL_ 657 DAS_RightObj_10_Y_2_Val 321 "Error" 320 "320" 319 "319" 318 "318" 317 "317" 316 "316" 315 "315" 314 "314" 313 "313" 312 "312" 311 "311" 310 "310" 309 "309" 308 "308" 307 "307" 306 "306" 305 "305" 304 "304" 303 "303" 302 "302" 301 "301" 300 "300" 299 "299" 298 "298" 297 "297" 296 "296" 295 "295" 294 "294" 293 "293" 292 "292" 291 "291" 290 "290" 289 "289" 288 "288" 287 "287" 286 "286" 285 "285" 284 "284" 283 "283" 282 "282" 281 "281" 280 "280" 279 "279" 278 "278" 277 "277" 276 "276" 275 "275" 274 "274" 273 "273" 272 "272" 271 "271" 270 "270" 269 "269" 268 "268" 267 "267" 266 "266" 265 "265" 264 "264" 263 "263" 262 "262" 261 "261" 260 "260" 259 "259" 258 "258" 257 "257" 256 "256" 255 "255" 254 "254" 253 "253" 252 "252" 251 "251" 250 "250" 249 "249" 248 "248" 247 "247" 246 "246" 245 "245" 244 "244" 243 "243" 242 "242" 241 "241" 240 "240" 239 "239" 238 "238" 237 "237" 236 "236" 235 "235" 234 "234" 233 "233" 232 "232" 231 "231" 230 "230" 229 "229" 228 "228" 227 "227" 226 "226" 225 "225" 224 "224" 223 "223" 222 "222" 221 "221" 220 "220" 219 "219" 218 "218" 217 "217" 216 "216" 215 "215" 214 "214" 213 "213" 212 "212" 211 "211" 210 "210" 209 "209" 208 "208" 207 "207" 206 "206" 205 "205" 204 "204" 203 "203" 202 "202" 201 "201" 200 "200" 199 "199" 198 "198" 197 "197" 196 "196" 195 "195" 194 "194" 193 "193" 192 "192" 191 "191" 190 "190" 189 "189" 188 "188" 187 "187" 186 "186" 185 "185" 184 "184" 183 "183" 182 "182" 181 "181" 180 "180" 179 "179" 178 "178" 177 "177" 176 "176" 175 "175" 174 "174" 173 "173" 172 "172" 171 "171" 170 "170" 169 "169" 168 "168" 167 "167" 166 "166" 165 "165" 164 "164" 163 "163" 162 "162" 161 "161" 160 "160" 159 "159" 158 "158" 157 "157" 156 "156" 155 "155" 154 "154" 153 "153" 152 "152" 151 "151" 150 "150" 149 "149" 148 "148" 147 "147" 146 "146" 145 "145" 144 "144" 143 "143" 142 "142" 141 "141" 140 "140" 139 "139" 138 "138" 137 "137" 136 "136" 135 "135" 134 "134" 133 "133" 132 "132" 131 "131" 130 "130" 129 "129" 128 "128" 127 "127" 126 "126" 125 "125" 124 "124" 123 "123" 122 "122" 121 "121" 120 "120" 119 "119" 118 "118" 117 "117" 116 "116" 115 "115" 114 "114" 113 "113" 112 "112" 111 "111" 110 "110" 109 "109" 108 "108" 107 "107" 106 "106" 105 "105" 104 "104" 103 "103" 102 "102" 101 "101" 100 "100" 99 "99" 98 "98" 97 "97" 96 "96" 95 "95" 94 "94" 93 "93" 92 "92" 91 "91" 90 "90" 89 "89" 88 "88" 87 "87" 86 "86" 85 "85" 84 "84" 83 "83" 82 "82" 81 "81" 80 "80" 79 "79" 78 "78" 77 "77" 76 "76" 75 "75" 74 "74" 73 "73" 72 "72" 71 "71" 70 "70" 69 "69" 68 "68" 67 "67" 66 "66" 65 "65" 64 "64" 63 "63" 62 "62" 61 "61" 60 "60" 59 "59" 58 "58" 57 "57" 56 "56" 55 "55" 54 "54" 53 "53" 52 "52" 51 "51" 50 "50" 49 "49" 48 "48" 47 "47" 46 "46" 45 "45" 44 "44" 43 "43" 42 "42" 41 "41" 40 "40" 39 "39" 38 "38" 37 "37" 36 "36" 35 "35" 34 "34" 33 "33" 32 "32" 31 "31" 30 "30" 29 "29" 28 "28" 27 "27" 26 "26" 25 "25" 24 "24" 23 "23" 22 "22" 21 "21" 20 "20" 19 "19" 18 "18" 17 "17" 16 "16" 15 "15" 14 "14" 13 "13" 12 "12" 11 "11" 10 "10" 9 "9" 8 "8" 7 "7" 6 "6" 5 "5" 4 "4" 3 "3" 2 "2" 1 "1" 0 "Unknown" ;
VAL_ 657 DAS_RightObj_10_Z_2_Val 81 "Error" 80 "80" 79 "79" 78 "78" 77 "77" 76 "76" 75 "75" 74 "74" 73 "73" 72 "72" 71 "71" 70 "70" 69 "69" 68 "68" 67 "67" 66 "66" 65 "65" 64 "64" 63 "63" 62 "62" 61 "61" 60 "60" 59 "59" 58 "58" 57 "57" 56 "56" 55 "55" 54 "54" 53 "53" 52 "52" 51 "51" 50 "50" 49 "49" 48 "48" 47 "47" 46 "46" 45 "45" 44 "44" 43 "43" 42 "42" 41 "41" 40 "40" 39 "39" 38 "38" 37 "37" 36 "36" 35 "35" 34 "34" 33 "33" 32 "32" 31 "31" 30 "30" 29 "29" 28 "28" 27 "27" 26 "26" 25 "25" 24 "24" 23 "23" 22 "22" 21 "21" 20 "20" 19 "19" 18 "18" 17 "17" 16 "16" 15 "15" 14 "14" 13 "13" 12 "12" 11 "11" 10 "10" 9 "9" 8 "8" 7 "7" 6 "6" 5 "5" 4 "4" 3 "3" 2 "2" 1 "1" 0 "Unknown" ;
VAL_ 657 DAS_RightObj_3_Z_2_Val 81 "Error" 80 "80" 79 "79" 78 "78" 77 "77" 76 "76" 75 "75" 74 "74" 73 "73" 72 "72" 71 "71" 70 "70" 69 "69" 68 "68" 67 "67" 66 "66" 65 "65" 64 "64" 63 "63" 62 "62" 61 "61" 60 "60" 59 "59" 58 "58" 57 "57" 56 "56" 55 "55" 54 "54" 53 "53" 52 "52" 51 "51" 50 "50" 49 "49" 48 "48" 47 "47" 46 "46" 45 "45" 44 "44" 43 "43" 42 "42" 41 "41" 40 "40" 39 "39" 38 "38" 37 "37" 36 "36" 35 "35" 34 "34" 33 "33" 32 "32" 31 "31" 30 "30" 29 "29" 28 "28" 27 "27" 26 "26" 25 "25" 24 "24" 23 "23" 22 "22" 21 "21" 20 "20" 19 "19" 18 "18" 17 "17" 16 "16" 15 "15" 14 "14" 13 "13" 12 "12" 11 "11" 10 "10" 9 "9" 8 "8" 7 "7" 6 "6" 5 "5" 4 "4" 3 "3" 2 "2" 1 "1" 0 "Unknown" ;
VAL_ 657 DAS_RightObj_4_Y_1_Val 321 "Error" 320 "320" 319 "319" 318 "318" 317 "317" 316 "316" 315 "315" 314 "314" 313 "313" 312 "312" 311 "311" 310 "310" 309 "309" 308 "308" 307 "307" 306 "306" 305 "305" 304 "304" 303 "303" 302 "302" 301 "301" 300 "300" 299 "299" 298 "298" 297 "297" 296 "296" 295 "295" 294 "294" 293 "293" 292 "292" 291 "291" 290 "290" 289 "289" 288 "288" 287 "287" 286 "286" 285 "285" 284 "284" 283 "283" 282 "282" 281 "281" 280 "280" 279 "279" 278 "278" 277 "277" 276 "276" 275 "275" 274 "274" 273 "273" 272 "272" 271 "271" 270 "270" 269 "269" 268 "268" 267 "267" 266 "266" 265 "265" 264 "264" 263 "263" 262 "262" 261 "261" 260 "260" 259 "259" 258 "258" 257 "257" 256 "256" 255 "255" 254 "254" 253 "253" 252 "252" 251 "251" 250 "250" 249 "249" 248 "248" 247 "247" 246 "246" 245 "245" 244 "244" 243 "243" 242 "242" 241 "241" 240 "240" 239 "239" 238 "238" 237 "237" 236 "236" 235 "235" 234 "234" 233 "233" 232 "232" 231 "231" 230 "230" 229 "229" 228 "228" 227 "227" 226 "226" 225 "225" 224 "224" 223 "223" 222 "222" 221 "221" 220 "220" 219 "219" 218 "218" 217 "217" 216 "216" 215 "215" 214 "214" 213 "213" 212 "212" 211 "211" 210 "210" 209 "209" 208 "208" 207 "207" 206 "206" 205 "205" 204 "204" 203 "203" 202 "202" 201 "201" 200 "200" 199 "199" 198 "198" 197 "197" 196 "196" 195 "195" 194 "194" 193 "193" 192 "192" 191 "191" 190 "190" 189 "189" 188 "188" 187 "187" 186 "186" 185 "185" 184 "184" 183 "183" 182 "182" 181 "181" 180 "180" 179 "179" 178 "178" 177 "177" 176 "176" 175 "175" 174 "174" 173 "173" 172 "172" 171 "171" 170 "170" 169 "169" 168 "168" 167 "167" 166 "166" 165 "165" 164 "164" 163 "163" 162 "162" 161 "161" 160 "160" 159 "159" 158 "158" 157 "157" 156 "156" 155 "155" 154 "154" 153 "153" 152 "152" 151 "151" 150 "150" 149 "149" 148 "148" 147 "147" 146 "146" 145 "145" 144 "144" 143 "143" 142 "142" 141 "141" 140 "140" 139 "139" 138 "138" 137 "137" 136 "136" 135 "135" 134 "134" 133 "133" 132 "132" 131 "131" 130 "130" 129 "129" 128 "128" 127 "127" 126 "126" 125 "125" 124 "124" 123 "123" 122 "122" 121 "121" 120 "120" 119 "119" 118 "118" 117 "117" 116 "116" 115 "115" 114 "114" 113 "113" 112 "112" 111 "111" 110 "110" 109 "109" 108 "108" 107 "107" 106 "106" 105 "105" 104 "104" 103 "103" 102 "102" 101 "101" 100 "100" 99 "99" 98 "98" 97 "97" 96 "96" 95 "95" 94 "94" 93 "93" 92 "92" 91 "91" 90 "90" 89 "89" 88 "88" 87 "87" 86 "86" 85 "85" 84 "84" 83 "83" 82 "82" 81 "81" 80 "80" 79 "79" 78 "78" 77 "77" 76 "76" 75 "75" 74 "74" 73 "73" 72 "72" 71 "71" 70 "70" 69 "69" 68 "68" 67 "67" 66 "66" 65 "65" 64 "64" 63 "63" 62 "62" 61 "61" 60 "60" 59 "59" 58 "58" 57 "57" 56 "56" 55 "55" 54 "54" 53 "53" 52 "52" 51 "51" 50 "50" 49 "49" 48 "48" 47 "47" 46 "46" 45 "45" 44 "44" 43 "43" 42 "42" 41 "41" 40 "40" 39 "39" 38 "38" 37 "37" 36 "36" 35 "35" 34 "34" 33 "33" 32 "32" 31 "31" 30 "30" 29 "29" 28 "28" 27 "27" 26 "26" 25 "25" 24 "24" 23 "23" 22 "22" 21 "21" 20 "20" 19 "19" 18 "18" 17 "17" 16 "16" 15 "15" 14 "14" 13 "13" 12 "12" 11 "11" 10 "10" 9 "9" 8 "8" 7 "7" 6 "6" 5 "5" 4 "4" 3 "3" 2 "2" 1 "1" 0 "Unknown" ;
VAL_ 657 DAS_RightObj_8_Z_1_Val 81 "Error" 80 "80" 79 "79" 78 "78" 77 "77" 76 "76" 75 "75" 74 "74" 73 "73" 72 "72" 71 "71" 70 "70" 69 "69" 68 "68" 67 "67" 66 "66" 65 "65" 64 "64" 63 "63" 62 "62" 61 "61" 60 "60" 59 "59" 58 "58" 57 "57" 56 "56" 55 "55" 54 "54" 53 "53" 52 "52" 51 "51" 50 "50" 49 "49" 48 "48" 47 "47" 46 "46" 45 "45" 44 "44" 43 "43" 42 "42" 41 "41" 40 "40" 39 "39" 38 "38" 37 "37" 36 "36" 35 "35" 34 "34" 33 "33" 32 "32" 31 "31" 30 "30" 29 "29" 28 "28" 27 "27" 26 "26" 25 "25" 24 "24" 23 "23" 22 "22" 21 "21" 20 "20" 19 "19" 18 "18" 17 "17" 16 "16" 15 "15" 14 "14" 13 "13" 12 "12" 11 "11" 10 "10" 9 "9" 8 "8" 7 "7" 6 "6" 5 "5" 4 "4" 3 "3" 2 "2" 1 "1" 0 "Unknown" ;
VAL_ 657 DAS_RightObj_6_Z_2_Val 81 "Error" 80 "80" 79 "79" 78 "78" 77 "77" 76 "76" 75 "75" 74 "74" 73 "73" 72 "72" 71 "71" 70 "70" 69 "69" 68 "68" 67 "67" 66 "66" 65 "65" 64 "64" 63 "63" 62 "62" 61 "61" 60 "60" 59 "59" 58 "58" 57 "57" 56 "56" 55 "55" 54 "54" 53 "53" 52 "52" 51 "51" 50 "50" 49 "49" 48 "48" 47 "47" 46 "46" 45 "45" 44 "44" 43 "43" 42 "42" 41 "41" 40 "40" 39 "39" 38 "38" 37 "37" 36 "36" 35 "35" 34 "34" 33 "33" 32 "32" 31 "31" 30 "30" 29 "29" 28 "28" 27 "27" 26 "26" 25 "25" 24 "24" 23 "23" 22 "22" 21 "21" 20 "20" 19 "19" 18 "18" 17 "17" 16 "16" 15 "15" 14 "14" 13 "13" 12 "12" 11 "11" 10 "10" 9 "9" 8 "8" 7 "7" 6 "6" 5 "5" 4 "4" 3 "3" 2 "2" 1 "1" 0 "Unknown" ;
VAL_ 657 DAS_ADBRightLED12_Req 1 "On" 0 "Off" ;
VAL_ 657 DAS_ADBRightLED15_Req 1 "On" 0 "Off" ;
VAL_ 657 DAS_RightObj_3_Z_1_Val 81 "Error" 80 "80" 79 "79" 78 "78" 77 "77" 76 "76" 75 "75" 74 "74" 73 "73" 72 "72" 71 "71" 70 "70" 69 "69" 68 "68" 67 "67" 66 "66" 65 "65" 64 "64" 63 "63" 62 "62" 61 "61" 60 "60" 59 "59" 58 "58" 57 "57" 56 "56" 55 "55" 54 "54" 53 "53" 52 "52" 51 "51" 50 "50" 49 "49" 48 "48" 47 "47" 46 "46" 45 "45" 44 "44" 43 "43" 42 "42" 41 "41" 40 "40" 39 "39" 38 "38" 37 "37" 36 "36" 35 "35" 34 "34" 33 "33" 32 "32" 31 "31" 30 "30" 29 "29" 28 "28" 27 "27" 26 "26" 25 "25" 24 "24" 23 "23" 22 "22" 21 "21" 20 "20" 19 "19" 18 "18" 17 "17" 16 "16" 15 "15" 14 "14" 13 "13" 12 "12" 11 "11" 10 "10" 9 "9" 8 "8" 7 "7" 6 "6" 5 "5" 4 "4" 3 "3" 2 "2" 1 "1" 0 "Unknown" ;
VAL_ 657 DAS_ADBRightLED8_Req 1 "On" 0 "Off" ;
VAL_ 657 DAS_RightObj_7_Y_2_Val 321 "Error" 320 "320" 319 "319" 318 "318" 317 "317" 316 "316" 315 "315" 314 "314" 313 "313" 312 "312" 311 "311" 310 "310" 309 "309" 308 "308" 307 "307" 306 "306" 305 "305" 304 "304" 303 "303" 302 "302" 301 "301" 300 "300" 299 "299" 298 "298" 297 "297" 296 "296" 295 "295" 294 "294" 293 "293" 292 "292" 291 "291" 290 "290" 289 "289" 288 "288" 287 "287" 286 "286" 285 "285" 284 "284" 283 "283" 282 "282" 281 "281" 280 "280" 279 "279" 278 "278" 277 "277" 276 "276" 275 "275" 274 "274" 273 "273" 272 "272" 271 "271" 270 "270" 269 "269" 268 "268" 267 "267" 266 "266" 265 "265" 264 "264" 263 "263" 262 "262" 261 "261" 260 "260" 259 "259" 258 "258" 257 "257" 256 "256" 255 "255" 254 "254" 253 "253" 252 "252" 251 "251" 250 "250" 249 "249" 248 "248" 247 "247" 246 "246" 245 "245" 244 "244" 243 "243" 242 "242" 241 "241" 240 "240" 239 "239" 238 "238" 237 "237" 236 "236" 235 "235" 234 "234" 233 "233" 232 "232" 231 "231" 230 "230" 229 "229" 228 "228" 227 "227" 226 "226" 225 "225" 224 "224" 223 "223" 222 "222" 221 "221" 220 "220" 219 "219" 218 "218" 217 "217" 216 "216" 215 "215" 214 "214" 213 "213" 212 "212" 211 "211" 210 "210" 209 "209" 208 "208" 207 "207" 206 "206" 205 "205" 204 "204" 203 "203" 202 "202" 201 "201" 200 "200" 199 "199" 198 "198" 197 "197" 196 "196" 195 "195" 194 "194" 193 "193" 192 "192" 191 "191" 190 "190" 189 "189" 188 "188" 187 "187" 186 "186" 185 "185" 184 "184" 183 "183" 182 "182" 181 "181" 180 "180" 179 "179" 178 "178" 177 "177" 176 "176" 175 "175" 174 "174" 173 "173" 172 "172" 171 "171" 170 "170" 169 "169" 168 "168" 167 "167" 166 "166" 165 "165" 164 "164" 163 "163" 162 "162" 161 "161" 160 "160" 159 "159" 158 "158" 157 "157" 156 "156" 155 "155" 154 "154" 153 "153" 152 "152" 151 "151" 150 "150" 149 "149" 148 "148" 147 "147" 146 "146" 145 "145" 144 "144" 143 "143" 142 "142" 141 "141" 140 "140" 139 "139" 138 "138" 137 "137" 136 "136" 135 "135" 134 "134" 133 "133" 132 "132" 131 "131" 130 "130" 129 "129" 128 "128" 127 "127" 126 "126" 125 "125" 124 "124" 123 "123" 122 "122" 121 "121" 120 "120" 119 "119" 118 "118" 117 "117" 116 "116" 115 "115" 114 "114" 113 "113" 112 "112" 111 "111" 110 "110" 109 "109" 108 "108" 107 "107" 106 "106" 105 "105" 104 "104" 103 "103" 102 "102" 101 "101" 100 "100" 99 "99" 98 "98" 97 "97" 96 "96" 95 "95" 94 "94" 93 "93" 92 "92" 91 "91" 90 "90" 89 "89" 88 "88" 87 "87" 86 "86" 85 "85" 84 "84" 83 "83" 82 "82" 81 "81" 80 "80" 79 "79" 78 "78" 77 "77" 76 "76" 75 "75" 74 "74" 73 "73" 72 "72" 71 "71" 70 "70" 69 "69" 68 "68" 67 "67" 66 "66" 65 "65" 64 "64" 63 "63" 62 "62" 61 "61" 60 "60" 59 "59" 58 "58" 57 "57" 56 "56" 55 "55" 54 "54" 53 "53" 52 "52" 51 "51" 50 "50" 49 "49" 48 "48" 47 "47" 46 "46" 45 "45" 44 "44" 43 "43" 42 "42" 41 "41" 40 "40" 39 "39" 38 "38" 37 "37" 36 "36" 35 "35" 34 "34" 33 "33" 32 "32" 31 "31" 30 "30" 29 "29" 28 "28" 27 "27" 26 "26" 25 "25" 24 "24" 23 "23" 22 "22" 21 "21" 20 "20" 19 "19" 18 "18" 17 "17" 16 "16" 15 "15" 14 "14" 13 "13" 12 "12" 11 "11" 10 "10" 9 "9" 8 "8" 7 "7" 6 "6" 5 "5" 4 "4" 3 "3" 2 "2" 1 "1" 0 "Unknown" ;
VAL_ 657 DAS_RightObj_9_Y_1_Val 321 "Error" 320 "320" 319 "319" 318 "318" 317 "317" 316 "316" 315 "315" 314 "314" 313 "313" 312 "312" 311 "311" 310 "310" 309 "309" 308 "308" 307 "307" 306 "306" 305 "305" 304 "304" 303 "303" 302 "302" 301 "301" 300 "300" 299 "299" 298 "298" 297 "297" 296 "296" 295 "295" 294 "294" 293 "293" 292 "292" 291 "291" 290 "290" 289 "289" 288 "288" 287 "287" 286 "286" 285 "285" 284 "284" 283 "283" 282 "282" 281 "281" 280 "280" 279 "279" 278 "278" 277 "277" 276 "276" 275 "275" 274 "274" 273 "273" 272 "272" 271 "271" 270 "270" 269 "269" 268 "268" 267 "267" 266 "266" 265 "265" 264 "264" 263 "263" 262 "262" 261 "261" 260 "260" 259 "259" 258 "258" 257 "257" 256 "256" 255 "255" 254 "254" 253 "253" 252 "252" 251 "251" 250 "250" 249 "249" 248 "248" 247 "247" 246 "246" 245 "245" 244 "244" 243 "243" 242 "242" 241 "241" 240 "240" 239 "239" 238 "238" 237 "237" 236 "236" 235 "235" 234 "234" 233 "233" 232 "232" 231 "231" 230 "230" 229 "229" 228 "228" 227 "227" 226 "226" 225 "225" 224 "224" 223 "223" 222 "222" 221 "221" 220 "220" 219 "219" 218 "218" 217 "217" 216 "216" 215 "215" 214 "214" 213 "213" 212 "212" 211 "211" 210 "210" 209 "209" 208 "208" 207 "207" 206 "206" 205 "205" 204 "204" 203 "203" 202 "202" 201 "201" 200 "200" 199 "199" 198 "198" 197 "197" 196 "196" 195 "195" 194 "194" 193 "193" 192 "192" 191 "191" 190 "190" 189 "189" 188 "188" 187 "187" 186 "186" 185 "185" 184 "184" 183 "183" 182 "182" 181 "181" 180 "180" 179 "179" 178 "178" 177 "177" 176 "176" 175 "175" 174 "174" 173 "173" 172 "172" 171 "171" 170 "170" 169 "169" 168 "168" 167 "167" 166 "166" 165 "165" 164 "164" 163 "163" 162 "162" 161 "161" 160 "160" 159 "159" 158 "158" 157 "157" 156 "156" 155 "155" 154 "154" 153 "153" 152 "152" 151 "151" 150 "150" 149 "149" 148 "148" 147 "147" 146 "146" 145 "145" 144 "144" 143 "143" 142 "142" 141 "141" 140 "140" 139 "139" 138 "138" 137 "137" 136 "136" 135 "135" 134 "134" 133 "133" 132 "132" 131 "131" 130 "130" 129 "129" 128 "128" 127 "127" 126 "126" 125 "125" 124 "124" 123 "123" 122 "122" 121 "121" 120 "120" 119 "119" 118 "118" 117 "117" 116 "116" 115 "115" 114 "114" 113 "113" 112 "112" 111 "111" 110 "110" 109 "109" 108 "108" 107 "107" 106 "106" 105 "105" 104 "104" 103 "103" 102 "102" 101 "101" 100 "100" 99 "99" 98 "98" 97 "97" 96 "96" 95 "95" 94 "94" 93 "93" 92 "92" 91 "91" 90 "90" 89 "89" 88 "88" 87 "87" 86 "86" 85 "85" 84 "84" 83 "83" 82 "82" 81 "81" 80 "80" 79 "79" 78 "78" 77 "77" 76 "76" 75 "75" 74 "74" 73 "73" 72 "72" 71 "71" 70 "70" 69 "69" 68 "68" 67 "67" 66 "66" 65 "65" 64 "64" 63 "63" 62 "62" 61 "61" 60 "60" 59 "59" 58 "58" 57 "57" 56 "56" 55 "55" 54 "54" 53 "53" 52 "52" 51 "51" 50 "50" 49 "49" 48 "48" 47 "47" 46 "46" 45 "45" 44 "44" 43 "43" 42 "42" 41 "41" 40 "40" 39 "39" 38 "38" 37 "37" 36 "36" 35 "35" 34 "34" 33 "33" 32 "32" 31 "31" 30 "30" 29 "29" 28 "28" 27 "27" 26 "26" 25 "25" 24 "24" 23 "23" 22 "22" 21 "21" 20 "20" 19 "19" 18 "18" 17 "17" 16 "16" 15 "15" 14 "14" 13 "13" 12 "12" 11 "11" 10 "10" 9 "9" 8 "8" 7 "7" 6 "6" 5 "5" 4 "4" 3 "3" 2 "2" 1 "1" 0 "Unknown" ;
VAL_ 657 DAS_RightObj_4_Y_2_Val 321 "Error" 320 "320" 319 "319" 318 "318" 317 "317" 316 "316" 315 "315" 314 "314" 313 "313" 312 "312" 311 "311" 310 "310" 309 "309" 308 "308" 307 "307" 306 "306" 305 "305" 304 "304" 303 "303" 302 "302" 301 "301" 300 "300" 299 "299" 298 "298" 297 "297" 296 "296" 295 "295" 294 "294" 293 "293" 292 "292" 291 "291" 290 "290" 289 "289" 288 "288" 287 "287" 286 "286" 285 "285" 284 "284" 283 "283" 282 "282" 281 "281" 280 "280" 279 "279" 278 "278" 277 "277" 276 "276" 275 "275" 274 "274" 273 "273" 272 "272" 271 "271" 270 "270" 269 "269" 268 "268" 267 "267" 266 "266" 265 "265" 264 "264" 263 "263" 262 "262" 261 "261" 260 "260" 259 "259" 258 "258" 257 "257" 256 "256" 255 "255" 254 "254" 253 "253" 252 "252" 251 "251" 250 "250" 249 "249" 248 "248" 247 "247" 246 "246" 245 "245" 244 "244" 243 "243" 242 "242" 241 "241" 240 "240" 239 "239" 238 "238" 237 "237" 236 "236" 235 "235" 234 "234" 233 "233" 232 "232" 231 "231" 230 "230" 229 "229" 228 "228" 227 "227" 226 "226" 225 "225" 224 "224" 223 "223" 222 "222" 221 "221" 220 "220" 219 "219" 218 "218" 217 "217" 216 "216" 215 "215" 214 "214" 213 "213" 212 "212" 211 "211" 210 "210" 209 "209" 208 "208" 207 "207" 206 "206" 205 "205" 204 "204" 203 "203" 202 "202" 201 "201" 200 "200" 199 "199" 198 "198" 197 "197" 196 "196" 195 "195" 194 "194" 193 "193" 192 "192" 191 "191" 190 "190" 189 "189" 188 "188" 187 "187" 186 "186" 185 "185" 184 "184" 183 "183" 182 "182" 181 "181" 180 "180" 179 "179" 178 "178" 177 "177" 176 "176" 175 "175" 174 "174" 173 "173" 172 "172" 171 "171" 170 "170" 169 "169" 168 "168" 167 "167" 166 "166" 165 "165" 164 "164" 163 "163" 162 "162" 161 "161" 160 "160" 159 "159" 158 "158" 157 "157" 156 "156" 155 "155" 154 "154" 153 "153" 152 "152" 151 "151" 150 "150" 149 "149" 148 "148" 147 "147" 146 "146" 145 "145" 144 "144" 143 "143" 142 "142" 141 "141" 140 "140" 139 "139" 138 "138" 137 "137" 136 "136" 135 "135" 134 "134" 133 "133" 132 "132" 131 "131" 130 "130" 129 "129" 128 "128" 127 "127" 126 "126" 125 "125" 124 "124" 123 "123" 122 "122" 121 "121" 120 "120" 119 "119" 118 "118" 117 "117" 116 "116" 115 "115" 114 "114" 113 "113" 112 "112" 111 "111" 110 "110" 109 "109" 108 "108" 107 "107" 106 "106" 105 "105" 104 "104" 103 "103" 102 "102" 101 "101" 100 "100" 99 "99" 98 "98" 97 "97" 96 "96" 95 "95" 94 "94" 93 "93" 92 "92" 91 "91" 90 "90" 89 "89" 88 "88" 87 "87" 86 "86" 85 "85" 84 "84" 83 "83" 82 "82" 81 "81" 80 "80" 79 "79" 78 "78" 77 "77" 76 "76" 75 "75" 74 "74" 73 "73" 72 "72" 71 "71" 70 "70" 69 "69" 68 "68" 67 "67" 66 "66" 65 "65" 64 "64" 63 "63" 62 "62" 61 "61" 60 "60" 59 "59" 58 "58" 57 "57" 56 "56" 55 "55" 54 "54" 53 "53" 52 "52" 51 "51" 50 "50" 49 "49" 48 "48" 47 "47" 46 "46" 45 "45" 44 "44" 43 "43" 42 "42" 41 "41" 40 "40" 39 "39" 38 "38" 37 "37" 36 "36" 35 "35" 34 "34" 33 "33" 32 "32" 31 "31" 30 "30" 29 "29" 28 "28" 27 "27" 26 "26" 25 "25" 24 "24" 23 "23" 22 "22" 21 "21" 20 "20" 19 "19" 18 "18" 17 "17" 16 "16" 15 "15" 14 "14" 13 "13" 12 "12" 11 "11" 10 "10" 9 "9" 8 "8" 7 "7" 6 "6" 5 "5" 4 "4" 3 "3" 2 "2" 1 "1" 0 "Unknown" ;
VAL_ 657 DAS_RightObj_2_Z_1_Val 81 "Error" 80 "80" 79 "79" 78 "78" 77 "77" 76 "76" 75 "75" 74 "74" 73 "73" 72 "72" 71 "71" 70 "70" 69 "69" 68 "68" 67 "67" 66 "66" 65 "65" 64 "64" 63 "63" 62 "62" 61 "61" 60 "60" 59 "59" 58 "58" 57 "57" 56 "56" 55 "55" 54 "54" 53 "53" 52 "52" 51 "51" 50 "50" 49 "49" 48 "48" 47 "47" 46 "46" 45 "45" 44 "44" 43 "43" 42 "42" 41 "41" 40 "40" 39 "39" 38 "38" 37 "37" 36 "36" 35 "35" 34 "34" 33 "33" 32 "32" 31 "31" 30 "30" 29 "29" 28 "28" 27 "27" 26 "26" 25 "25" 24 "24" 23 "23" 22 "22" 21 "21" 20 "20" 19 "19" 18 "18" 17 "17" 16 "16" 15 "15" 14 "14" 13 "13" 12 "12" 11 "11" 10 "10" 9 "9" 8 "8" 7 "7" 6 "6" 5 "5" 4 "4" 3 "3" 2 "2" 1 "1" 0 "Unknown" ;
VAL_ 657 DAS_RightObj_7_Z_1_Val 81 "Error" 80 "80" 79 "79" 78 "78" 77 "77" 76 "76" 75 "75" 74 "74" 73 "73" 72 "72" 71 "71" 70 "70" 69 "69" 68 "68" 67 "67" 66 "66" 65 "65" 64 "64" 63 "63" 62 "62" 61 "61" 60 "60" 59 "59" 58 "58" 57 "57" 56 "56" 55 "55" 54 "54" 53 "53" 52 "52" 51 "51" 50 "50" 49 "49" 48 "48" 47 "47" 46 "46" 45 "45" 44 "44" 43 "43" 42 "42" 41 "41" 40 "40" 39 "39" 38 "38" 37 "37" 36 "36" 35 "35" 34 "34" 33 "33" 32 "32" 31 "31" 30 "30" 29 "29" 28 "28" 27 "27" 26 "26" 25 "25" 24 "24" 23 "23" 22 "22" 21 "21" 20 "20" 19 "19" 18 "18" 17 "17" 16 "16" 15 "15" 14 "14" 13 "13" 12 "12" 11 "11" 10 "10" 9 "9" 8 "8" 7 "7" 6 "6" 5 "5" 4 "4" 3 "3" 2 "2" 1 "1" 0 "Unknown" ;
VAL_ 657 DAS_RightObj_9_Z_1_Val 81 "Error" 80 "80" 79 "79" 78 "78" 77 "77" 76 "76" 75 "75" 74 "74" 73 "73" 72 "72" 71 "71" 70 "70" 69 "69" 68 "68" 67 "67" 66 "66" 65 "65" 64 "64" 63 "63" 62 "62" 61 "61" 60 "60" 59 "59" 58 "58" 57 "57" 56 "56" 55 "55" 54 "54" 53 "53" 52 "52" 51 "51" 50 "50" 49 "49" 48 "48" 47 "47" 46 "46" 45 "45" 44 "44" 43 "43" 42 "42" 41 "41" 40 "40" 39 "39" 38 "38" 37 "37" 36 "36" 35 "35" 34 "34" 33 "33" 32 "32" 31 "31" 30 "30" 29 "29" 28 "28" 27 "27" 26 "26" 25 "25" 24 "24" 23 "23" 22 "22" 21 "21" 20 "20" 19 "19" 18 "18" 17 "17" 16 "16" 15 "15" 14 "14" 13 "13" 12 "12" 11 "11" 10 "10" 9 "9" 8 "8" 7 "7" 6 "6" 5 "5" 4 "4" 3 "3" 2 "2" 1 "1" 0 "Unknown" ;
VAL_ 657 DAS_RightObj_5_Y_1_Val 321 "Error" 320 "320" 319 "319" 318 "318" 317 "317" 316 "316" 315 "315" 314 "314" 313 "313" 312 "312" 311 "311" 310 "310" 309 "309" 308 "308" 307 "307" 306 "306" 305 "305" 304 "304" 303 "303" 302 "302" 301 "301" 300 "300" 299 "299" 298 "298" 297 "297" 296 "296" 295 "295" 294 "294" 293 "293" 292 "292" 291 "291" 290 "290" 289 "289" 288 "288" 287 "287" 286 "286" 285 "285" 284 "284" 283 "283" 282 "282" 281 "281" 280 "280" 279 "279" 278 "278" 277 "277" 276 "276" 275 "275" 274 "274" 273 "273" 272 "272" 271 "271" 270 "270" 269 "269" 268 "268" 267 "267" 266 "266" 265 "265" 264 "264" 263 "263" 262 "262" 261 "261" 260 "260" 259 "259" 258 "258" 257 "257" 256 "256" 255 "255" 254 "254" 253 "253" 252 "252" 251 "251" 250 "250" 249 "249" 248 "248" 247 "247" 246 "246" 245 "245" 244 "244" 243 "243" 242 "242" 241 "241" 240 "240" 239 "239" 238 "238" 237 "237" 236 "236" 235 "235" 234 "234" 233 "233" 232 "232" 231 "231" 230 "230" 229 "229" 228 "228" 227 "227" 226 "226" 225 "225" 224 "224" 223 "223" 222 "222" 221 "221" 220 "220" 219 "219" 218 "218" 217 "217" 216 "216" 215 "215" 214 "214" 213 "213" 212 "212" 211 "211" 210 "210" 209 "209" 208 "208" 207 "207" 206 "206" 205 "205" 204 "204" 203 "203" 202 "202" 201 "201" 200 "200" 199 "199" 198 "198" 197 "197" 196 "196" 195 "195" 194 "194" 193 "193" 192 "192" 191 "191" 190 "190" 189 "189" 188 "188" 187 "187" 186 "186" 185 "185" 184 "184" 183 "183" 182 "182" 181 "181" 180 "180" 179 "179" 178 "178" 177 "177" 176 "176" 175 "175" 174 "174" 173 "173" 172 "172" 171 "171" 170 "170" 169 "169" 168 "168" 167 "167" 166 "166" 165 "165" 164 "164" 163 "163" 162 "162" 161 "161" 160 "160" 159 "159" 158 "158" 157 "157" 156 "156" 155 "155" 154 "154" 153 "153" 152 "152" 151 "151" 150 "150" 149 "149" 148 "148" 147 "147" 146 "146" 145 "145" 144 "144" 143 "143" 142 "142" 141 "141" 140 "140" 139 "139" 138 "138" 137 "137" 136 "136" 135 "135" 134 "134" 133 "133" 132 "132" 131 "131" 130 "130" 129 "129" 128 "128" 127 "127" 126 "126" 125 "125" 124 "124" 123 "123" 122 "122" 121 "121" 120 "120" 119 "119" 118 "118" 117 "117" 116 "116" 115 "115" 114 "114" 113 "113" 112 "112" 111 "111" 110 "110" 109 "109" 108 "108" 107 "107" 106 "106" 105 "105" 104 "104" 103 "103" 102 "102" 101 "101" 100 "100" 99 "99" 98 "98" 97 "97" 96 "96" 95 "95" 94 "94" 93 "93" 92 "92" 91 "91" 90 "90" 89 "89" 88 "88" 87 "87" 86 "86" 85 "85" 84 "84" 83 "83" 82 "82" 81 "81" 80 "80" 79 "79" 78 "78" 77 "77" 76 "76" 75 "75" 74 "74" 73 "73" 72 "72" 71 "71" 70 "70" 69 "69" 68 "68" 67 "67" 66 "66" 65 "65" 64 "64" 63 "63" 62 "62" 61 "61" 60 "60" 59 "59" 58 "58" 57 "57" 56 "56" 55 "55" 54 "54" 53 "53" 52 "52" 51 "51" 50 "50" 49 "49" 48 "48" 47 "47" 46 "46" 45 "45" 44 "44" 43 "43" 42 "42" 41 "41" 40 "40" 39 "39" 38 "38" 37 "37" 36 "36" 35 "35" 34 "34" 33 "33" 32 "32" 31 "31" 30 "30" 29 "29" 28 "28" 27 "27" 26 "26" 25 "25" 24 "24" 23 "23" 22 "22" 21 "21" 20 "20" 19 "19" 18 "18" 17 "17" 16 "16" 15 "15" 14 "14" 13 "13" 12 "12" 11 "11" 10 "10" 9 "9" 8 "8" 7 "7" 6 "6" 5 "5" 4 "4" 3 "3" 2 "2" 1 "1" 0 "Unknown" ;
VAL_ 657 DAS_RightObj_10_Z_1_Val 81 "Error" 80 "80" 79 "79" 78 "78" 77 "77" 76 "76" 75 "75" 74 "74" 73 "73" 72 "72" 71 "71" 70 "70" 69 "69" 68 "68" 67 "67" 66 "66" 65 "65" 64 "64" 63 "63" 62 "62" 61 "61" 60 "60" 59 "59" 58 "58" 57 "57" 56 "56" 55 "55" 54 "54" 53 "53" 52 "52" 51 "51" 50 "50" 49 "49" 48 "48" 47 "47" 46 "46" 45 "45" 44 "44" 43 "43" 42 "42" 41 "41" 40 "40" 39 "39" 38 "38" 37 "37" 36 "36" 35 "35" 34 "34" 33 "33" 32 "32" 31 "31" 30 "30" 29 "29" 28 "28" 27 "27" 26 "26" 25 "25" 24 "24" 23 "23" 22 "22" 21 "21" 20 "20" 19 "19" 18 "18" 17 "17" 16 "16" 15 "15" 14 "14" 13 "13" 12 "12" 11 "11" 10 "10" 9 "9" 8 "8" 7 "7" 6 "6" 5 "5" 4 "4" 3 "3" 2 "2" 1 "1" 0 "Unknown" ;
VAL_ 657 DAS_RightObj_8_Y_2_Val 321 "Error" 320 "320" 319 "319" 318 "318" 317 "317" 316 "316" 315 "315" 314 "314" 313 "313" 312 "312" 311 "311" 310 "310" 309 "309" 308 "308" 307 "307" 306 "306" 305 "305" 304 "304" 303 "303" 302 "302" 301 "301" 300 "300" 299 "299" 298 "298" 297 "297" 296 "296" 295 "295" 294 "294" 293 "293" 292 "292" 291 "291" 290 "290" 289 "289" 288 "288" 287 "287" 286 "286" 285 "285" 284 "284" 283 "283" 282 "282" 281 "281" 280 "280" 279 "279" 278 "278" 277 "277" 276 "276" 275 "275" 274 "274" 273 "273" 272 "272" 271 "271" 270 "270" 269 "269" 268 "268" 267 "267" 266 "266" 265 "265" 264 "264" 263 "263" 262 "262" 261 "261" 260 "260" 259 "259" 258 "258" 257 "257" 256 "256" 255 "255" 254 "254" 253 "253" 252 "252" 251 "251" 250 "250" 249 "249" 248 "248" 247 "247" 246 "246" 245 "245" 244 "244" 243 "243" 242 "242" 241 "241" 240 "240" 239 "239" 238 "238" 237 "237" 236 "236" 235 "235" 234 "234" 233 "233" 232 "232" 231 "231" 230 "230" 229 "229" 228 "228" 227 "227" 226 "226" 225 "225" 224 "224" 223 "223" 222 "222" 221 "221" 220 "220" 219 "219" 218 "218" 217 "217" 216 "216" 215 "215" 214 "214" 213 "213" 212 "212" 211 "211" 210 "210" 209 "209" 208 "208" 207 "207" 206 "206" 205 "205" 204 "204" 203 "203" 202 "202" 201 "201" 200 "200" 199 "199" 198 "198" 197 "197" 196 "196" 195 "195" 194 "194" 193 "193" 192 "192" 191 "191" 190 "190" 189 "189" 188 "188" 187 "187" 186 "186" 185 "185" 184 "184" 183 "183" 182 "182" 181 "181" 180 "180" 179 "179" 178 "178" 177 "177" 176 "176" 175 "175" 174 "174" 173 "173" 172 "172" 171 "171" 170 "170" 169 "169" 168 "168" 167 "167" 166 "166" 165 "165" 164 "164" 163 "163" 162 "162" 161 "161" 160 "160" 159 "159" 158 "158" 157 "157" 156 "156" 155 "155" 154 "154" 153 "153" 152 "152" 151 "151" 150 "150" 149 "149" 148 "148" 147 "147" 146 "146" 145 "145" 144 "144" 143 "143" 142 "142" 141 "141" 140 "140" 139 "139" 138 "138" 137 "137" 136 "136" 135 "135" 134 "134" 133 "133" 132 "132" 131 "131" 130 "130" 129 "129" 128 "128" 127 "127" 126 "126" 125 "125" 124 "124" 123 "123" 122 "122" 121 "121" 120 "120" 119 "119" 118 "118" 117 "117" 116 "116" 115 "115" 114 "114" 113 "113" 112 "112" 111 "111" 110 "110" 109 "109" 108 "108" 107 "107" 106 "106" 105 "105" 104 "104" 103 "103" 102 "102" 101 "101" 100 "100" 99 "99" 98 "98" 97 "97" 96 "96" 95 "95" 94 "94" 93 "93" 92 "92" 91 "91" 90 "90" 89 "89" 88 "88" 87 "87" 86 "86" 85 "85" 84 "84" 83 "83" 82 "82" 81 "81" 80 "80" 79 "79" 78 "78" 77 "77" 76 "76" 75 "75" 74 "74" 73 "73" 72 "72" 71 "71" 70 "70" 69 "69" 68 "68" 67 "67" 66 "66" 65 "65" 64 "64" 63 "63" 62 "62" 61 "61" 60 "60" 59 "59" 58 "58" 57 "57" 56 "56" 55 "55" 54 "54" 53 "53" 52 "52" 51 "51" 50 "50" 49 "49" 48 "48" 47 "47" 46 "46" 45 "45" 44 "44" 43 "43" 42 "42" 41 "41" 40 "40" 39 "39" 38 "38" 37 "37" 36 "36" 35 "35" 34 "34" 33 "33" 32 "32" 31 "31" 30 "30" 29 "29" 28 "28" 27 "27" 26 "26" 25 "25" 24 "24" 23 "23" 22 "22" 21 "21" 20 "20" 19 "19" 18 "18" 17 "17" 16 "16" 15 "15" 14 "14" 13 "13" 12 "12" 11 "11" 10 "10" 9 "9" 8 "8" 7 "7" 6 "6" 5 "5" 4 "4" 3 "3" 2 "2" 1 "1" 0 "Unknown" ;
VAL_ 657 DAS_ADBRightLED4_Req 1 "On" 0 "Off" ;
VAL_ 657 DAS_RightObj_4_Z_2_Val 81 "Error" 80 "80" 79 "79" 78 "78" 77 "77" 76 "76" 75 "75" 74 "74" 73 "73" 72 "72" 71 "71" 70 "70" 69 "69" 68 "68" 67 "67" 66 "66" 65 "65" 64 "64" 63 "63" 62 "62" 61 "61" 60 "60" 59 "59" 58 "58" 57 "57" 56 "56" 55 "55" 54 "54" 53 "53" 52 "52" 51 "51" 50 "50" 49 "49" 48 "48" 47 "47" 46 "46" 45 "45" 44 "44" 43 "43" 42 "42" 41 "41" 40 "40" 39 "39" 38 "38" 37 "37" 36 "36" 35 "35" 34 "34" 33 "33" 32 "32" 31 "31" 30 "30" 29 "29" 28 "28" 27 "27" 26 "26" 25 "25" 24 "24" 23 "23" 22 "22" 21 "21" 20 "20" 19 "19" 18 "18" 17 "17" 16 "16" 15 "15" 14 "14" 13 "13" 12 "12" 11 "11" 10 "10" 9 "9" 8 "8" 7 "7" 6 "6" 5 "5" 4 "4" 3 "3" 2 "2" 1 "1" 0 "Unknown" ;
VAL_ 657 DAS_RightObj_6_Y_1_Val 34 "34" 33 "33" 32 "32" 31 "31" 30 "30" 29 "29" 28 "28" 27 "27" 26 "26" 25 "25" 24 "24" 23 "23" 22 "22" 21 "21" 20 "20" 19 "19" 18 "18" 17 "17" 16 "16" 15 "15" 14 "14" 13 "13" 12 "12" 11 "11" 10 "10" 9 "9" 8 "8" 7 "7" 6 "6" 5 "5" 4 "4" 3 "3" 2 "2" 1 "1" 0 "Unknown" 321 "Error" 320 "320" 319 "319" 318 "318" 317 "317" 316 "316" 315 "315" 314 "314" 313 "313" 312 "312" 311 "311" 310 "310" 309 "309" 308 "308" 307 "307" 306 "306" 305 "305" 304 "304" 303 "303" 302 "302" 301 "301" 300 "300" 299 "299" 298 "298" 297 "297" 296 "296" 295 "295" 294 "294" 293 "293" 292 "292" 291 "291" 290 "290" 289 "289" 288 "288" 287 "287" 286 "286" 285 "285" 284 "284" 283 "283" 282 "282" 281 "281" 280 "280" 279 "279" 278 "278" 277 "277" 276 "276" 275 "275" 274 "274" 273 "273" 272 "272" 271 "271" 270 "270" 269 "269" 268 "268" 267 "267" 266 "266" 265 "265" 264 "264" 263 "263" 262 "262" 261 "261" 260 "260" 259 "259" 258 "258" 257 "257" 256 "256" 255 "255" 254 "254" 253 "253" 252 "252" 251 "251" 250 "250" 249 "249" 248 "248" 247 "247" 246 "246" 245 "245" 244 "244" 243 "243" 242 "242" 241 "241" 240 "240" 239 "239" 238 "238" 237 "237" 236 "236" 235 "235" 234 "234" 233 "233" 232 "232" 231 "231" 230 "230" 229 "229" 228 "228" 227 "227" 226 "226" 225 "225" 224 "224" 223 "223" 222 "222" 221 "221" 220 "220" 219 "219" 218 "218" 217 "217" 216 "216" 215 "215" 214 "214" 213 "213" 212 "212" 211 "211" 210 "210" 209 "209" 208 "208" 207 "207" 206 "206" 205 "205" 204 "204" 203 "203" 202 "202" 201 "201" 200 "200" 199 "199" 198 "198" 197 "197" 196 "196" 195 "195" 194 "194" 193 "193" 192 "192" 191 "191" 190 "190" 189 "189" 188 "188" 187 "187" 186 "186" 185 "185" 184 "184" 183 "183" 182 "182" 181 "181" 180 "180" 179 "179" 178 "178" 177 "177" 176 "176" 175 "175" 174 "174" 173 "173" 172 "172" 171 "171" 170 "170" 169 "169" 168 "168" 167 "167" 166 "166" 165 "165" 164 "164" 163 "163" 162 "162" 161 "161" 160 "160" 159 "159" 158 "158" 157 "157" 156 "156" 155 "155" 154 "154" 153 "153" 152 "152" 151 "151" 150 "150" 149 "149" 148 "148" 147 "147" 146 "146" 145 "145" 144 "144" 143 "143" 142 "142" 141 "141" 140 "140" 139 "139" 138 "138" 137 "137" 136 "136" 135 "135" 134 "134" 133 "133" 132 "132" 131 "131" 130 "130" 129 "129" 128 "128" 127 "127" 126 "126" 125 "125" 124 "124" 123 "123" 122 "122" 121 "121" 120 "120" 119 "119" 118 "118" 117 "117" 116 "116" 115 "115" 114 "114" 113 "113" 112 "112" 111 "111" 110 "110" 109 "109" 108 "108" 107 "107" 106 "106" 105 "105" 104 "104" 103 "103" 102 "102" 101 "101" 100 "100" 99 "99" 98 "98" 97 "97" 96 "96" 95 "95" 94 "94" 93 "93" 92 "92" 91 "91" 90 "90" 89 "89" 88 "88" 87 "87" 86 "86" 85 "85" 84 "84" 83 "83" 82 "82" 81 "81" 80 "80" 79 "79" 78 "78" 77 "77" 76 "76" 75 "75" 74 "74" 73 "73" 72 "72" 71 "71" 70 "70" 69 "69" 68 "68" 67 "67" 66 "66" 65 "65" 64 "64" 63 "63" 62 "62" 61 "61" 60 "60" 59 "59" 58 "58" 57 "57" 56 "56" 55 "55" 54 "54" 53 "53" 52 "52" 51 "51" 50 "50" 49 "49" 48 "48" 47 "47" 46 "46" 45 "45" 44 "44" 43 "43" 42 "42" 41 "41" 40 "40" 39 "39" 38 "38" 37 "37" 36 "36" 35 "35" ;
VAL_ 657 DAS_ADBRightLED13_Req 1 "On" 0 "Off" ;
VAL_ 657 DAS_RightObj_1_Y_1_Val 321 "Error" 320 "320" 319 "319" 318 "318" 317 "317" 316 "316" 315 "315" 314 "314" 313 "313" 312 "312" 311 "311" 310 "310" 309 "309" 308 "308" 307 "307" 306 "306" 305 "305" 304 "304" 303 "303" 302 "302" 301 "301" 300 "300" 299 "299" 298 "298" 297 "297" 296 "296" 295 "295" 294 "294" 293 "293" 292 "292" 291 "291" 290 "290" 289 "289" 288 "288" 287 "287" 286 "286" 285 "285" 284 "284" 283 "283" 282 "282" 281 "281" 280 "280" 279 "279" 278 "278" 277 "277" 276 "276" 275 "275" 274 "274" 273 "273" 272 "272" 271 "271" 270 "270" 269 "269" 268 "268" 267 "267" 266 "266" 265 "265" 264 "264" 263 "263" 262 "262" 261 "261" 260 "260" 259 "259" 258 "258" 257 "257" 256 "256" 255 "255" 254 "254" 253 "253" 252 "252" 251 "251" 250 "250" 249 "249" 248 "248" 247 "247" 246 "246" 245 "245" 244 "244" 243 "243" 242 "242" 241 "241" 240 "240" 239 "239" 238 "238" 237 "237" 236 "236" 235 "235" 234 "234" 233 "233" 232 "232" 231 "231" 230 "230" 229 "229" 228 "228" 227 "227" 226 "226" 225 "225" 224 "224" 223 "223" 222 "222" 221 "221" 220 "220" 219 "219" 218 "218" 217 "217" 216 "216" 215 "215" 214 "214" 213 "213" 212 "212" 211 "211" 210 "210" 209 "209" 208 "208" 207 "207" 206 "206" 205 "205" 204 "204" 203 "203" 202 "202" 201 "201" 200 "200" 199 "199" 198 "198" 197 "197" 196 "196" 195 "195" 194 "194" 193 "193" 192 "192" 191 "191" 190 "190" 189 "189" 188 "188" 187 "187" 186 "186" 185 "185" 184 "184" 183 "183" 182 "182" 181 "181" 180 "180" 179 "179" 178 "178" 177 "177" 176 "176" 175 "175" 174 "174" 173 "173" 172 "172" 171 "171" 170 "170" 169 "169" 168 "168" 167 "167" 166 "166" 165 "165" 164 "164" 163 "163" 162 "162" 161 "161" 160 "160" 159 "159" 158 "158" 157 "157" 156 "156" 155 "155" 154 "154" 153 "153" 152 "152" 151 "151" 150 "150" 149 "149" 148 "148" 147 "147" 146 "146" 145 "145" 144 "144" 143 "143" 142 "142" 141 "141" 140 "140" 139 "139" 138 "138" 137 "137" 136 "136" 135 "135" 134 "134" 133 "133" 132 "132" 131 "131" 130 "130" 129 "129" 128 "128" 127 "127" 126 "126" 125 "125" 124 "124" 123 "123" 122 "122" 121 "121" 120 "120" 119 "119" 118 "118" 117 "117" 116 "116" 115 "115" 114 "114" 113 "113" 112 "112" 111 "111" 110 "110" 109 "109" 108 "108" 107 "107" 106 "106" 105 "105" 104 "104" 103 "103" 102 "102" 101 "101" 100 "100" 99 "99" 98 "98" 97 "97" 96 "96" 95 "95" 94 "94" 93 "93" 92 "92" 91 "91" 90 "90" 89 "89" 88 "88" 87 "87" 86 "86" 85 "85" 84 "84" 83 "83" 82 "82" 81 "81" 80 "80" 79 "79" 78 "78" 77 "77" 76 "76" 75 "75" 74 "74" 73 "73" 72 "72" 71 "71" 70 "70" 69 "69" 68 "68" 67 "67" 66 "66" 65 "65" 64 "64" 63 "63" 62 "62" 61 "61" 60 "60" 59 "59" 58 "58" 57 "57" 56 "56" 55 "55" 54 "54" 53 "53" 52 "52" 51 "51" 50 "50" 49 "49" 48 "48" 47 "47" 46 "46" 45 "45" 44 "44" 43 "43" 42 "42" 41 "41" 40 "40" 39 "39" 38 "38" 37 "37" 36 "36" 35 "35" 34 "34" 33 "33" 32 "32" 31 "31" 30 "30" 29 "29" 28 "28" 27 "27" 26 "26" 25 "25" 24 "24" 23 "23" 22 "22" 21 "21" 20 "20" 19 "19" 18 "18" 17 "17" 16 "16" 15 "15" 14 "14" 13 "13" 12 "12" 11 "11" 10 "10" 9 "9" 8 "8" 7 "7" 6 "6" 5 "5" 4 "4" 3 "3" 2 "2" 1 "1" 0 "Unknown" ;
VAL_ 657 DAS_ADBRightLED17_Req 1 "On" 0 "Off" ;
VAL_ 657 DAS_ADBRightLED9_Req 1 "On" 0 "Off" ;
VAL_ 657 DAS_RightObj_6_Z_1_Val 81 "Error" 80 "80" 79 "79" 78 "78" 77 "77" 76 "76" 75 "75" 74 "74" 73 "73" 72 "72" 71 "71" 70 "70" 69 "69" 68 "68" 67 "67" 66 "66" 65 "65" 64 "64" 63 "63" 62 "62" 61 "61" 60 "60" 59 "59" 58 "58" 57 "57" 56 "56" 55 "55" 54 "54" 53 "53" 52 "52" 51 "51" 50 "50" 49 "49" 48 "48" 47 "47" 46 "46" 45 "45" 44 "44" 43 "43" 42 "42" 41 "41" 40 "40" 39 "39" 38 "38" 37 "37" 36 "36" 35 "35" 34 "34" 33 "33" 32 "32" 31 "31" 30 "30" 29 "29" 28 "28" 27 "27" 26 "26" 25 "25" 24 "24" 23 "23" 22 "22" 21 "21" 20 "20" 19 "19" 18 "18" 17 "17" 16 "16" 15 "15" 14 "14" 13 "13" 12 "12" 11 "11" 10 "10" 9 "9" 8 "8" 7 "7" 6 "6" 5 "5" 4 "4" 3 "3" 2 "2" 1 "1" 0 "Unknown" ;
VAL_ 657 DAS_RightObj_4_Z_1_Val 81 "Error" 80 "80" 79 "79" 78 "78" 77 "77" 76 "76" 75 "75" 74 "74" 73 "73" 72 "72" 71 "71" 70 "70" 69 "69" 68 "68" 67 "67" 66 "66" 65 "65" 64 "64" 63 "63" 62 "62" 61 "61" 60 "60" 59 "59" 58 "58" 57 "57" 56 "56" 55 "55" 54 "54" 53 "53" 52 "52" 51 "51" 50 "50" 49 "49" 48 "48" 47 "47" 46 "46" 45 "45" 44 "44" 43 "43" 42 "42" 41 "41" 40 "40" 39 "39" 38 "38" 37 "37" 36 "36" 35 "35" 34 "34" 33 "33" 32 "32" 31 "31" 30 "30" 29 "29" 28 "28" 27 "27" 26 "26" 25 "25" 24 "24" 23 "23" 22 "22" 21 "21" 20 "20" 19 "19" 18 "18" 17 "17" 16 "16" 15 "15" 14 "14" 13 "13" 12 "12" 11 "11" 10 "10" 9 "9" 8 "8" 7 "7" 6 "6" 5 "5" 4 "4" 3 "3" 2 "2" 1 "1" 0 "Unknown" ;
VAL_ 657 DAS_ADBRightLED18_Req 1 "On" 0 "Off" ;
VAL_ 657 DAS_RightObj_1_Z_1_Val 81 "Error" 80 "80" 79 "79" 78 "78" 77 "77" 76 "76" 75 "75" 74 "74" 73 "73" 72 "72" 71 "71" 70 "70" 69 "69" 68 "68" 67 "67" 66 "66" 65 "65" 64 "64" 63 "63" 62 "62" 61 "61" 60 "60" 59 "59" 58 "58" 57 "57" 56 "56" 55 "55" 54 "54" 53 "53" 52 "52" 51 "51" 50 "50" 49 "49" 48 "48" 47 "47" 46 "46" 45 "45" 44 "44" 43 "43" 42 "42" 41 "41" 40 "40" 39 "39" 38 "38" 37 "37" 36 "36" 35 "35" 34 "34" 33 "33" 32 "32" 31 "31" 30 "30" 29 "29" 28 "28" 27 "27" 26 "26" 25 "25" 24 "24" 23 "23" 22 "22" 21 "21" 20 "20" 19 "19" 18 "18" 17 "17" 16 "16" 15 "15" 14 "14" 13 "13" 12 "12" 11 "11" 10 "10" 9 "9" 8 "8" 7 "7" 6 "6" 5 "5" 4 "4" 3 "3" 2 "2" 1 "1" 0 "Unknown" ;
VAL_ 657 DAS_ADBRightLED7_Req 1 "On" 0 "Off" ;
VAL_ 657 DAS_RightObj_8_Z_2_Val 81 "Error" 80 "80" 79 "79" 78 "78" 77 "77" 76 "76" 75 "75" 74 "74" 73 "73" 72 "72" 71 "71" 70 "70" 69 "69" 68 "68" 67 "67" 66 "66" 65 "65" 64 "64" 63 "63" 62 "62" 61 "61" 60 "60" 59 "59" 58 "58" 57 "57" 56 "56" 55 "55" 54 "54" 53 "53" 52 "52" 51 "51" 50 "50" 49 "49" 48 "48" 47 "47" 46 "46" 45 "45" 44 "44" 43 "43" 42 "42" 41 "41" 40 "40" 39 "39" 38 "38" 37 "37" 36 "36" 35 "35" 34 "34" 33 "33" 32 "32" 31 "31" 30 "30" 29 "29" 28 "28" 27 "27" 26 "26" 25 "25" 24 "24" 23 "23" 22 "22" 21 "21" 20 "20" 19 "19" 18 "18" 17 "17" 16 "16" 15 "15" 14 "14" 13 "13" 12 "12" 11 "11" 10 "10" 9 "9" 8 "8" 7 "7" 6 "6" 5 "5" 4 "4" 3 "3" 2 "2" 1 "1" 0 "Unknown" ;
VAL_ 657 DAS_RightObj_2_Z_2_Val 81 "Error" 80 "80" 79 "79" 78 "78" 77 "77" 76 "76" 75 "75" 74 "74" 73 "73" 72 "72" 71 "71" 70 "70" 69 "69" 68 "68" 67 "67" 66 "66" 65 "65" 64 "64" 63 "63" 62 "62" 61 "61" 60 "60" 59 "59" 58 "58" 57 "57" 56 "56" 55 "55" 54 "54" 53 "53" 52 "52" 51 "51" 50 "50" 49 "49" 48 "48" 47 "47" 46 "46" 45 "45" 44 "44" 43 "43" 42 "42" 41 "41" 40 "40" 39 "39" 38 "38" 37 "37" 36 "36" 35 "35" 34 "34" 33 "33" 32 "32" 31 "31" 30 "30" 29 "29" 28 "28" 27 "27" 26 "26" 25 "25" 24 "24" 23 "23" 22 "22" 21 "21" 20 "20" 19 "19" 18 "18" 17 "17" 16 "16" 15 "15" 14 "14" 13 "13" 12 "12" 11 "11" 10 "10" 9 "9" 8 "8" 7 "7" 6 "6" 5 "5" 4 "4" 3 "3" 2 "2" 1 "1" 0 "Unknown" ;
VAL_ 657 DAS_RightObj_3_Y_1_Val 321 "Error" 320 "320" 319 "319" 318 "318" 317 "317" 316 "316" 315 "315" 314 "314" 313 "313" 312 "312" 311 "311" 310 "310" 309 "309" 308 "308" 307 "307" 306 "306" 305 "305" 304 "304" 303 "303" 302 "302" 301 "301" 300 "300" 299 "299" 298 "298" 297 "297" 296 "296" 295 "295" 294 "294" 293 "293" 292 "292" 291 "291" 290 "290" 289 "289" 288 "288" 287 "287" 286 "286" 285 "285" 284 "284" 283 "283" 282 "282" 281 "281" 280 "280" 279 "279" 278 "278" 277 "277" 276 "276" 275 "275" 274 "274" 273 "273" 272 "272" 271 "271" 270 "270" 269 "269" 268 "268" 267 "267" 266 "266" 265 "265" 264 "264" 263 "263" 262 "262" 261 "261" 260 "260" 259 "259" 258 "258" 257 "257" 256 "256" 255 "255" 254 "254" 253 "253" 252 "252" 251 "251" 250 "250" 249 "249" 248 "248" 247 "247" 246 "246" 245 "245" 244 "244" 243 "243" 242 "242" 241 "241" 240 "240" 239 "239" 238 "238" 237 "237" 236 "236" 235 "235" 234 "234" 233 "233" 232 "232" 231 "231" 230 "230" 229 "229" 228 "228" 227 "227" 226 "226" 225 "225" 224 "224" 223 "223" 222 "222" 221 "221" 220 "220" 219 "219" 218 "218" 217 "217" 216 "216" 215 "215" 214 "214" 213 "213" 212 "212" 211 "211" 210 "210" 209 "209" 208 "208" 207 "207" 206 "206" 205 "205" 204 "204" 203 "203" 202 "202" 201 "201" 200 "200" 199 "199" 198 "198" 197 "197" 196 "196" 195 "195" 194 "194" 193 "193" 192 "192" 191 "191" 190 "190" 189 "189" 188 "188" 187 "187" 186 "186" 185 "185" 184 "184" 183 "183" 182 "182" 181 "181" 180 "180" 179 "179" 178 "178" 177 "177" 176 "176" 175 "175" 174 "174" 173 "173" 172 "172" 171 "171" 170 "170" 169 "169" 168 "168" 167 "167" 166 "166" 165 "165" 164 "164" 163 "163" 162 "162" 161 "161" 160 "160" 159 "159" 158 "158" 157 "157" 156 "156" 155 "155" 154 "154" 153 "153" 152 "152" 151 "151" 150 "150" 149 "149" 148 "148" 147 "147" 146 "146" 145 "145" 144 "144" 143 "143" 142 "142" 141 "141" 140 "140" 139 "139" 138 "138" 137 "137" 136 "136" 135 "135" 134 "134" 133 "133" 132 "132" 131 "131" 130 "130" 129 "129" 128 "128" 127 "127" 126 "126" 125 "125" 124 "124" 123 "123" 122 "122" 121 "121" 120 "120" 119 "119" 118 "118" 117 "117" 116 "116" 115 "115" 114 "114" 113 "113" 112 "112" 111 "111" 110 "110" 109 "109" 108 "108" 107 "107" 106 "106" 105 "105" 104 "104" 103 "103" 102 "102" 101 "101" 100 "100" 99 "99" 98 "98" 97 "97" 96 "96" 95 "95" 94 "94" 93 "93" 92 "92" 91 "91" 90 "90" 89 "89" 88 "88" 87 "87" 86 "86" 85 "85" 84 "84" 83 "83" 82 "82" 81 "81" 80 "80" 79 "79" 78 "78" 77 "77" 76 "76" 75 "75" 74 "74" 73 "73" 72 "72" 71 "71" 70 "70" 69 "69" 68 "68" 67 "67" 66 "66" 65 "65" 64 "64" 63 "63" 62 "62" 61 "61" 60 "60" 59 "59" 58 "58" 57 "57" 56 "56" 55 "55" 54 "54" 53 "53" 52 "52" 51 "51" 50 "50" 49 "49" 48 "48" 47 "47" 46 "46" 45 "45" 44 "44" 43 "43" 42 "42" 41 "41" 40 "40" 39 "39" 38 "38" 37 "37" 36 "36" 35 "35" 34 "34" 33 "33" 32 "32" 31 "31" 30 "30" 29 "29" 28 "28" 27 "27" 26 "26" 25 "25" 24 "24" 23 "23" 22 "22" 21 "21" 20 "20" 19 "19" 18 "18" 17 "17" 16 "16" 15 "15" 14 "14" 13 "13" 12 "12" 11 "11" 10 "10" 9 "9" 8 "8" 7 "7" 6 "6" 5 "5" 4 "4" 3 "3" 2 "2" 1 "1" 0 "Unknown" ;
VAL_ 657 DAS_ADBRightLED3_Req 1 "On" 0 "Off" ;
VAL_ 657 DAS_RightObj_6_Y_2_Val 321 "Error" 320 "320" 319 "319" 318 "318" 317 "317" 316 "316" 315 "315" 314 "314" 313 "313" 312 "312" 311 "311" 310 "310" 309 "309" 308 "308" 307 "307" 306 "306" 305 "305" 304 "304" 303 "303" 302 "302" 301 "301" 300 "300" 299 "299" 298 "298" 297 "297" 296 "296" 295 "295" 294 "294" 293 "293" 292 "292" 291 "291" 290 "290" 289 "289" 288 "288" 287 "287" 286 "286" 285 "285" 284 "284" 283 "283" 282 "282" 281 "281" 280 "280" 279 "279" 278 "278" 277 "277" 276 "276" 275 "275" 274 "274" 273 "273" 272 "272" 271 "271" 270 "270" 269 "269" 268 "268" 267 "267" 266 "266" 265 "265" 264 "264" 263 "263" 262 "262" 261 "261" 260 "260" 259 "259" 258 "258" 257 "257" 256 "256" 255 "255" 254 "254" 253 "253" 252 "252" 251 "251" 250 "250" 249 "249" 248 "248" 247 "247" 246 "246" 245 "245" 244 "244" 243 "243" 242 "242" 241 "241" 240 "240" 239 "239" 238 "238" 237 "237" 236 "236" 235 "235" 234 "234" 233 "233" 232 "232" 231 "231" 230 "230" 229 "229" 228 "228" 227 "227" 226 "226" 225 "225" 224 "224" 223 "223" 222 "222" 221 "221" 220 "220" 219 "219" 218 "218" 217 "217" 216 "216" 215 "215" 214 "214" 213 "213" 212 "212" 211 "211" 210 "210" 209 "209" 208 "208" 207 "207" 206 "206" 205 "205" 204 "204" 203 "203" 202 "202" 201 "201" 200 "200" 199 "199" 198 "198" 197 "197" 196 "196" 195 "195" 194 "194" 193 "193" 192 "192" 191 "191" 190 "190" 189 "189" 188 "188" 187 "187" 186 "186" 185 "185" 184 "184" 183 "183" 182 "182" 181 "181" 180 "180" 179 "179" 178 "178" 177 "177" 176 "176" 175 "175" 174 "174" 173 "173" 172 "172" 171 "171" 170 "170" 169 "169" 168 "168" 167 "167" 166 "166" 165 "165" 164 "164" 163 "163" 162 "162" 161 "161" 160 "160" 159 "159" 158 "158" 157 "157" 156 "156" 155 "155" 154 "154" 153 "153" 152 "152" 151 "151" 150 "150" 149 "149" 148 "148" 147 "147" 146 "146" 145 "145" 144 "144" 143 "143" 142 "142" 141 "141" 140 "140" 139 "139" 138 "138" 137 "137" 136 "136" 135 "135" 134 "134" 133 "133" 132 "132" 131 "131" 130 "130" 129 "129" 128 "128" 127 "127" 126 "126" 125 "125" 124 "124" 123 "123" 122 "122" 121 "121" 120 "120" 119 "119" 118 "118" 117 "117" 116 "116" 115 "115" 114 "114" 113 "113" 112 "112" 111 "111" 110 "110" 109 "109" 108 "108" 107 "107" 106 "106" 105 "105" 104 "104" 103 "103" 102 "102" 101 "101" 100 "100" 99 "99" 98 "98" 97 "97" 96 "96" 95 "95" 94 "94" 93 "93" 92 "92" 91 "91" 90 "90" 89 "89" 88 "88" 87 "87" 86 "86" 85 "85" 84 "84" 83 "83" 82 "82" 81 "81" 80 "80" 79 "79" 78 "78" 77 "77" 76 "76" 75 "75" 74 "74" 73 "73" 72 "72" 71 "71" 70 "70" 69 "69" 68 "68" 67 "67" 66 "66" 65 "65" 64 "64" 63 "63" 62 "62" 61 "61" 60 "60" 59 "59" 58 "58" 57 "57" 56 "56" 55 "55" 54 "54" 53 "53" 52 "52" 51 "51" 50 "50" 49 "49" 48 "48" 47 "47" 46 "46" 45 "45" 44 "44" 43 "43" 42 "42" 41 "41" 40 "40" 39 "39" 38 "38" 37 "37" 36 "36" 35 "35" 34 "34" 33 "33" 32 "32" 31 "31" 30 "30" 29 "29" 28 "28" 27 "27" 26 "26" 25 "25" 24 "24" 23 "23" 22 "22" 21 "21" 20 "20" 19 "19" 18 "18" 17 "17" 16 "16" 15 "15" 14 "14" 13 "13" 12 "12" 11 "11" 10 "10" 9 "9" 8 "8" 7 "7" 6 "6" 5 "5" 4 "4" 3 "3" 2 "2" 1 "1" 0 "Unknown" ;
VAL_ 657 DAS_RightObj_5_Z_1_Val 81 "Error" 80 "80" 79 "79" 78 "78" 77 "77" 76 "76" 75 "75" 74 "74" 73 "73" 72 "72" 71 "71" 70 "70" 69 "69" 68 "68" 67 "67" 66 "66" 65 "65" 64 "64" 63 "63" 62 "62" 61 "61" 60 "60" 59 "59" 58 "58" 57 "57" 56 "56" 55 "55" 54 "54" 53 "53" 52 "52" 51 "51" 50 "50" 49 "49" 48 "48" 47 "47" 46 "46" 45 "45" 44 "44" 43 "43" 42 "42" 41 "41" 40 "40" 39 "39" 38 "38" 37 "37" 36 "36" 35 "35" 34 "34" 33 "33" 32 "32" 31 "31" 30 "30" 29 "29" 28 "28" 27 "27" 26 "26" 25 "25" 24 "24" 23 "23" 22 "22" 21 "21" 20 "20" 19 "19" 18 "18" 17 "17" 16 "16" 15 "15" 14 "14" 13 "13" 12 "12" 11 "11" 10 "10" 9 "9" 8 "8" 7 "7" 6 "6" 5 "5" 4 "4" 3 "3" 2 "2" 1 "1" 0 "Unknown" ;
VAL_ 657 DAS_RightObj_5_Y_2_Val 321 "Error" 320 "320" 319 "319" 318 "318" 317 "317" 316 "316" 315 "315" 314 "314" 313 "313" 312 "312" 311 "311" 310 "310" 309 "309" 308 "308" 307 "307" 306 "306" 305 "305" 304 "304" 303 "303" 302 "302" 301 "301" 300 "300" 299 "299" 298 "298" 297 "297" 296 "296" 295 "295" 294 "294" 293 "293" 292 "292" 291 "291" 290 "290" 289 "289" 288 "288" 287 "287" 286 "286" 285 "285" 284 "284" 283 "283" 282 "282" 281 "281" 280 "280" 279 "279" 278 "278" 277 "277" 276 "276" 275 "275" 274 "274" 273 "273" 272 "272" 271 "271" 270 "270" 269 "269" 268 "268" 267 "267" 266 "266" 265 "265" 264 "264" 263 "263" 262 "262" 261 "261" 260 "260" 259 "259" 258 "258" 257 "257" 256 "256" 255 "255" 254 "254" 253 "253" 252 "252" 251 "251" 250 "250" 249 "249" 248 "248" 247 "247" 246 "246" 245 "245" 244 "244" 243 "243" 242 "242" 241 "241" 240 "240" 239 "239" 238 "238" 237 "237" 236 "236" 235 "235" 234 "234" 233 "233" 232 "232" 231 "231" 230 "230" 229 "229" 228 "228" 227 "227" 226 "226" 225 "225" 224 "224" 223 "223" 222 "222" 221 "221" 220 "220" 219 "219" 218 "218" 217 "217" 216 "216" 215 "215" 214 "214" 213 "213" 212 "212" 211 "211" 210 "210" 209 "209" 208 "208" 207 "207" 206 "206" 205 "205" 204 "204" 203 "203" 202 "202" 201 "201" 200 "200" 199 "199" 198 "198" 197 "197" 196 "196" 195 "195" 194 "194" 193 "193" 192 "192" 191 "191" 190 "190" 189 "189" 188 "188" 187 "187" 186 "186" 185 "185" 184 "184" 183 "183" 182 "182" 181 "181" 180 "180" 179 "179" 178 "178" 177 "177" 176 "176" 175 "175" 174 "174" 173 "173" 172 "172" 171 "171" 170 "170" 169 "169" 168 "168" 167 "167" 166 "166" 165 "165" 164 "164" 163 "163" 162 "162" 161 "161" 160 "160" 159 "159" 158 "158" 157 "157" 156 "156" 155 "155" 154 "154" 153 "153" 152 "152" 151 "151" 150 "150" 149 "149" 148 "148" 147 "147" 146 "146" 145 "145" 144 "144" 143 "143" 142 "142" 141 "141" 140 "140" 139 "139" 138 "138" 137 "137" 136 "136" 135 "135" 134 "134" 133 "133" 132 "132" 131 "131" 130 "130" 129 "129" 128 "128" 127 "127" 126 "126" 125 "125" 124 "124" 123 "123" 122 "122" 121 "121" 120 "120" 119 "119" 118 "118" 117 "117" 116 "116" 115 "115" 114 "114" 113 "113" 112 "112" 111 "111" 110 "110" 109 "109" 108 "108" 107 "107" 106 "106" 105 "105" 104 "104" 103 "103" 102 "102" 101 "101" 100 "100" 99 "99" 98 "98" 97 "97" 96 "96" 95 "95" 94 "94" 93 "93" 92 "92" 91 "91" 90 "90" 89 "89" 88 "88" 87 "87" 86 "86" 85 "85" 84 "84" 83 "83" 82 "82" 81 "81" 80 "80" 79 "79" 78 "78" 77 "77" 76 "76" 75 "75" 74 "74" 73 "73" 72 "72" 71 "71" 70 "70" 69 "69" 68 "68" 67 "67" 66 "66" 65 "65" 64 "64" 63 "63" 62 "62" 61 "61" 60 "60" 59 "59" 58 "58" 57 "57" 56 "56" 55 "55" 54 "54" 53 "53" 52 "52" 51 "51" 50 "50" 49 "49" 48 "48" 47 "47" 46 "46" 45 "45" 44 "44" 43 "43" 42 "42" 41 "41" 40 "40" 39 "39" 38 "38" 37 "37" 36 "36" 35 "35" 34 "34" 33 "33" 32 "32" 31 "31" 30 "30" 29 "29" 28 "28" 27 "27" 26 "26" 25 "25" 24 "24" 23 "23" 22 "22" 21 "21" 20 "20" 19 "19" 18 "18" 17 "17" 16 "16" 15 "15" 14 "14" 13 "13" 12 "12" 11 "11" 10 "10" 9 "9" 8 "8" 7 "7" 6 "6" 5 "5" 4 "4" 3 "3" 2 "2" 1 "1" 0 "Unknown" ;
VAL_ 657 DAS_ADBRightLED2_Req 1 "On" 0 "Off" ;
VAL_ 657 DAS_ADBRightLED14_Req 1 "On" 0 "Off" ;
VAL_ 657 DAS_RightObj_2_Y_1_Val 321 "Error" 320 "320" 319 "319" 318 "318" 317 "317" 316 "316" 315 "315" 314 "314" 313 "313" 312 "312" 311 "311" 310 "310" 309 "309" 308 "308" 307 "307" 306 "306" 305 "305" 304 "304" 303 "303" 302 "302" 301 "301" 300 "300" 299 "299" 298 "298" 297 "297" 296 "296" 295 "295" 294 "294" 293 "293" 292 "292" 291 "291" 290 "290" 289 "289" 288 "288" 287 "287" 286 "286" 285 "285" 284 "284" 283 "283" 282 "282" 281 "281" 280 "280" 279 "279" 278 "278" 277 "277" 276 "276" 275 "275" 274 "274" 273 "273" 272 "272" 271 "271" 270 "270" 269 "269" 268 "268" 267 "267" 266 "266" 265 "265" 264 "264" 263 "263" 262 "262" 261 "261" 260 "260" 259 "259" 258 "258" 257 "257" 256 "256" 255 "255" 254 "254" 253 "253" 252 "252" 251 "251" 250 "250" 249 "249" 248 "248" 247 "247" 246 "246" 245 "245" 244 "244" 243 "243" 242 "242" 241 "241" 240 "240" 239 "239" 238 "238" 237 "237" 236 "236" 235 "235" 234 "234" 233 "233" 232 "232" 231 "231" 230 "230" 229 "229" 228 "228" 227 "227" 226 "226" 225 "225" 224 "224" 223 "223" 222 "222" 221 "221" 220 "220" 219 "219" 218 "218" 217 "217" 216 "216" 215 "215" 214 "214" 213 "213" 212 "212" 211 "211" 210 "210" 209 "209" 208 "208" 207 "207" 206 "206" 205 "205" 204 "204" 203 "203" 202 "202" 201 "201" 200 "200" 199 "199" 198 "198" 197 "197" 196 "196" 195 "195" 194 "194" 193 "193" 192 "192" 191 "191" 190 "190" 189 "189" 188 "188" 187 "187" 186 "186" 185 "185" 184 "184" 183 "183" 182 "182" 181 "181" 180 "180" 179 "179" 178 "178" 177 "177" 176 "176" 175 "175" 174 "174" 173 "173" 172 "172" 171 "171" 170 "170" 169 "169" 168 "168" 167 "167" 166 "166" 165 "165" 164 "164" 163 "163" 162 "162" 161 "161" 160 "160" 159 "159" 158 "158" 157 "157" 156 "156" 155 "155" 154 "154" 153 "153" 152 "152" 151 "151" 150 "150" 149 "149" 148 "148" 147 "147" 146 "146" 145 "145" 144 "144" 143 "143" 142 "142" 141 "141" 140 "140" 139 "139" 138 "138" 137 "137" 136 "136" 135 "135" 134 "134" 133 "133" 132 "132" 131 "131" 130 "130" 129 "129" 128 "128" 127 "127" 126 "126" 125 "125" 124 "124" 123 "123" 122 "122" 121 "121" 120 "120" 119 "119" 118 "118" 117 "117" 116 "116" 115 "115" 114 "114" 113 "113" 112 "112" 111 "111" 110 "110" 109 "109" 108 "108" 107 "107" 106 "106" 105 "105" 104 "104" 103 "103" 102 "102" 101 "101" 100 "100" 99 "99" 98 "98" 97 "97" 96 "96" 95 "95" 94 "94" 93 "93" 92 "92" 91 "91" 90 "90" 89 "89" 88 "88" 87 "87" 86 "86" 85 "85" 84 "84" 83 "83" 82 "82" 81 "81" 80 "80" 79 "79" 78 "78" 77 "77" 76 "76" 75 "75" 74 "74" 73 "73" 72 "72" 71 "71" 70 "70" 69 "69" 68 "68" 67 "67" 66 "66" 65 "65" 64 "64" 63 "63" 62 "62" 61 "61" 60 "60" 59 "59" 58 "58" 57 "57" 56 "56" 55 "55" 54 "54" 53 "53" 52 "52" 51 "51" 50 "50" 49 "49" 48 "48" 47 "47" 46 "46" 45 "45" 44 "44" 43 "43" 42 "42" 41 "41" 40 "40" 39 "39" 38 "38" 37 "37" 36 "36" 35 "35" 34 "34" 33 "33" 32 "32" 31 "31" 30 "30" 29 "29" 28 "28" 27 "27" 26 "26" 25 "25" 24 "24" 23 "23" 22 "22" 21 "21" 20 "20" 19 "19" 18 "18" 17 "17" 16 "16" 15 "15" 14 "14" 13 "13" 12 "12" 11 "11" 10 "10" 9 "9" 8 "8" 7 "7" 6 "6" 5 "5" 4 "4" 3 "3" 2 "2" 1 "1" 0 "Unknown" ;
VAL_ 657 DAS_RightObj_10_Y_1_Val 321 "Error" 320 "320" 319 "319" 318 "318" 317 "317" 316 "316" 315 "315" 314 "314" 313 "313" 312 "312" 311 "311" 310 "310" 309 "309" 308 "308" 307 "307" 306 "306" 305 "305" 304 "304" 303 "303" 302 "302" 301 "301" 300 "300" 299 "299" 298 "298" 297 "297" 296 "296" 295 "295" 294 "294" 293 "293" 292 "292" 291 "291" 290 "290" 289 "289" 288 "288" 287 "287" 286 "286" 285 "285" 284 "284" 283 "283" 282 "282" 281 "281" 280 "280" 279 "279" 278 "278" 277 "277" 276 "276" 275 "275" 274 "274" 273 "273" 272 "272" 271 "271" 270 "270" 269 "269" 268 "268" 267 "267" 266 "266" 265 "265" 264 "264" 263 "263" 262 "262" 261 "261" 260 "260" 259 "259" 258 "258" 257 "257" 256 "256" 255 "255" 254 "254" 253 "253" 252 "252" 251 "251" 250 "250" 249 "249" 248 "248" 247 "247" 246 "246" 245 "245" 244 "244" 243 "243" 242 "242" 241 "241" 240 "240" 239 "239" 238 "238" 237 "237" 236 "236" 235 "235" 234 "234" 233 "233" 232 "232" 231 "231" 230 "230" 229 "229" 228 "228" 227 "227" 226 "226" 225 "225" 224 "224" 223 "223" 222 "222" 221 "221" 220 "220" 219 "219" 218 "218" 217 "217" 216 "216" 215 "215" 214 "214" 213 "213" 212 "212" 211 "211" 210 "210" 209 "209" 208 "208" 207 "207" 206 "206" 205 "205" 204 "204" 203 "203" 202 "202" 201 "201" 200 "200" 199 "199" 198 "198" 197 "197" 196 "196" 195 "195" 194 "194" 193 "193" 192 "192" 191 "191" 190 "190" 189 "189" 188 "188" 187 "187" 186 "186" 185 "185" 184 "184" 183 "183" 182 "182" 181 "181" 180 "180" 179 "179" 178 "178" 177 "177" 176 "176" 175 "175" 174 "174" 173 "173" 172 "172" 171 "171" 170 "170" 169 "169" 168 "168" 167 "167" 166 "166" 165 "165" 164 "164" 163 "163" 162 "162" 161 "161" 160 "160" 159 "159" 158 "158" 157 "157" 156 "156" 155 "155" 154 "154" 153 "153" 152 "152" 151 "151" 150 "150" 149 "149" 148 "148" 147 "147" 146 "146" 145 "145" 144 "144" 143 "143" 142 "142" 141 "141" 140 "140" 139 "139" 138 "138" 137 "137" 136 "136" 135 "135" 134 "134" 133 "133" 132 "132" 131 "131" 130 "130" 129 "129" 128 "128" 127 "127" 126 "126" 125 "125" 124 "124" 123 "123" 122 "122" 121 "121" 120 "120" 119 "119" 118 "118" 117 "117" 116 "116" 115 "115" 114 "114" 113 "113" 112 "112" 111 "111" 110 "110" 109 "109" 108 "108" 107 "107" 106 "106" 105 "105" 104 "104" 103 "103" 102 "102" 101 "101" 100 "100" 99 "99" 98 "98" 97 "97" 96 "96" 95 "95" 94 "94" 93 "93" 92 "92" 91 "91" 90 "90" 89 "89" 88 "88" 87 "87" 86 "86" 85 "85" 84 "84" 83 "83" 82 "82" 81 "81" 80 "80" 79 "79" 78 "78" 77 "77" 76 "76" 75 "75" 74 "74" 73 "73" 72 "72" 71 "71" 70 "70" 69 "69" 68 "68" 67 "67" 66 "66" 65 "65" 64 "64" 63 "63" 62 "62" 61 "61" 60 "60" 59 "59" 58 "58" 57 "57" 56 "56" 55 "55" 54 "54" 53 "53" 52 "52" 51 "51" 50 "50" 49 "49" 48 "48" 47 "47" 46 "46" 45 "45" 44 "44" 43 "43" 42 "42" 41 "41" 40 "40" 39 "39" 38 "38" 37 "37" 36 "36" 35 "35" 34 "34" 33 "33" 32 "32" 31 "31" 30 "30" 29 "29" 28 "28" 27 "27" 26 "26" 25 "25" 24 "24" 23 "23" 22 "22" 21 "21" 20 "20" 19 "19" 18 "18" 17 "17" 16 "16" 15 "15" 14 "14" 13 "13" 12 "12" 11 "11" 10 "10" 9 "9" 8 "8" 7 "7" 6 "6" 5 "5" 4 "4" 3 "3" 2 "2" 1 "1" 0 "Unknown" ;
VAL_ 657 DAS_RightObj_1_Z_2_Val 81 "Error" 80 "80" 79 "79" 78 "78" 77 "77" 76 "76" 75 "75" 74 "74" 73 "73" 72 "72" 71 "71" 70 "70" 69 "69" 68 "68" 67 "67" 66 "66" 65 "65" 64 "64" 63 "63" 62 "62" 61 "61" 60 "60" 59 "59" 58 "58" 57 "57" 56 "56" 55 "55" 54 "54" 53 "53" 52 "52" 51 "51" 50 "50" 49 "49" 48 "48" 47 "47" 46 "46" 45 "45" 44 "44" 43 "43" 42 "42" 41 "41" 40 "40" 39 "39" 38 "38" 37 "37" 36 "36" 35 "35" 34 "34" 33 "33" 32 "32" 31 "31" 30 "30" 29 "29" 28 "28" 27 "27" 26 "26" 25 "25" 24 "24" 23 "23" 22 "22" 21 "21" 20 "20" 19 "19" 18 "18" 17 "17" 16 "16" 15 "15" 14 "14" 13 "13" 12 "12" 11 "11" 10 "10" 9 "9" 8 "8" 7 "7" 6 "6" 5 "5" 4 "4" 3 "3" 2 "2" 1 "1" 0 "Unknown" ;
VAL_ 657 DAS_RightObj_2_Y_2_Val 321 "Error" 320 "320" 319 "319" 318 "318" 317 "317" 316 "316" 315 "315" 314 "314" 313 "313" 312 "312" 311 "311" 310 "310" 309 "309" 308 "308" 307 "307" 306 "306" 305 "305" 304 "304" 303 "303" 302 "302" 301 "301" 300 "300" 299 "299" 298 "298" 297 "297" 296 "296" 295 "295" 294 "294" 293 "293" 292 "292" 291 "291" 290 "290" 289 "289" 288 "288" 287 "287" 286 "286" 285 "285" 284 "284" 283 "283" 282 "282" 281 "281" 280 "280" 279 "279" 278 "278" 277 "277" 276 "276" 275 "275" 274 "274" 273 "273" 272 "272" 271 "271" 270 "270" 269 "269" 268 "268" 267 "267" 266 "266" 265 "265" 264 "264" 263 "263" 262 "262" 261 "261" 260 "260" 259 "259" 258 "258" 257 "257" 256 "256" 255 "255" 254 "254" 253 "253" 252 "252" 251 "251" 250 "250" 249 "249" 248 "248" 247 "247" 246 "246" 245 "245" 244 "244" 243 "243" 242 "242" 241 "241" 240 "240" 239 "239" 238 "238" 237 "237" 236 "236" 235 "235" 234 "234" 233 "233" 232 "232" 231 "231" 230 "230" 229 "229" 228 "228" 227 "227" 226 "226" 225 "225" 224 "224" 223 "223" 222 "222" 221 "221" 220 "220" 219 "219" 218 "218" 217 "217" 216 "216" 215 "215" 214 "214" 213 "213" 212 "212" 211 "211" 210 "210" 209 "209" 208 "208" 207 "207" 206 "206" 205 "205" 204 "204" 203 "203" 202 "202" 201 "201" 200 "200" 199 "199" 198 "198" 197 "197" 196 "196" 195 "195" 194 "194" 193 "193" 192 "192" 191 "191" 190 "190" 189 "189" 188 "188" 187 "187" 186 "186" 185 "185" 184 "184" 183 "183" 182 "182" 181 "181" 180 "180" 179 "179" 178 "178" 177 "177" 176 "176" 175 "175" 174 "174" 173 "173" 172 "172" 171 "171" 170 "170" 169 "169" 168 "168" 167 "167" 166 "166" 165 "165" 164 "164" 163 "163" 162 "162" 161 "161" 160 "160" 159 "159" 158 "158" 157 "157" 156 "156" 155 "155" 154 "154" 153 "153" 152 "152" 151 "151" 150 "150" 149 "149" 148 "148" 147 "147" 146 "146" 145 "145" 144 "144" 143 "143" 142 "142" 141 "141" 140 "140" 139 "139" 138 "138" 137 "137" 136 "136" 135 "135" 134 "134" 133 "133" 132 "132" 131 "131" 130 "130" 129 "129" 128 "128" 127 "127" 126 "126" 125 "125" 124 "124" 123 "123" 122 "122" 121 "121" 120 "120" 119 "119" 118 "118" 117 "117" 116 "116" 115 "115" 114 "114" 113 "113" 112 "112" 111 "111" 110 "110" 109 "109" 108 "108" 107 "107" 106 "106" 105 "105" 104 "104" 103 "103" 102 "102" 101 "101" 100 "100" 99 "99" 98 "98" 97 "97" 96 "96" 95 "95" 94 "94" 93 "93" 92 "92" 91 "91" 90 "90" 89 "89" 88 "88" 87 "87" 86 "86" 85 "85" 84 "84" 83 "83" 82 "82" 81 "81" 80 "80" 79 "79" 78 "78" 77 "77" 76 "76" 75 "75" 74 "74" 73 "73" 72 "72" 71 "71" 70 "70" 69 "69" 68 "68" 67 "67" 66 "66" 65 "65" 64 "64" 63 "63" 62 "62" 61 "61" 60 "60" 59 "59" 58 "58" 57 "57" 56 "56" 55 "55" 54 "54" 53 "53" 52 "52" 51 "51" 50 "50" 49 "49" 48 "48" 47 "47" 46 "46" 45 "45" 44 "44" 43 "43" 42 "42" 41 "41" 40 "40" 39 "39" 38 "38" 37 "37" 36 "36" 35 "35" 34 "34" 33 "33" 32 "32" 31 "31" 30 "30" 29 "29" 28 "28" 27 "27" 26 "26" 25 "25" 24 "24" 23 "23" 22 "22" 21 "21" 20 "20" 19 "19" 18 "18" 17 "17" 16 "16" 15 "15" 14 "14" 13 "13" 12 "12" 11 "11" 10 "10" 9 "9" 8 "8" 7 "7" 6 "6" 5 "5" 4 "4" 3 "3" 2 "2" 1 "1" 0 "Unknown" ;
VAL_ 657 DAS_RightObj_7_Y_1_Val 321 "Error" 320 "320" 319 "319" 318 "318" 317 "317" 316 "316" 315 "315" 314 "314" 313 "313" 312 "312" 311 "311" 310 "310" 309 "309" 308 "308" 307 "307" 306 "306" 305 "305" 304 "304" 303 "303" 302 "302" 301 "301" 300 "300" 299 "299" 298 "298" 297 "297" 296 "296" 295 "295" 294 "294" 293 "293" 292 "292" 291 "291" 290 "290" 289 "289" 288 "288" 287 "287" 286 "286" 285 "285" 284 "284" 283 "283" 282 "282" 281 "281" 280 "280" 279 "279" 278 "278" 277 "277" 276 "276" 275 "275" 274 "274" 273 "273" 272 "272" 271 "271" 270 "270" 269 "269" 268 "268" 267 "267" 266 "266" 265 "265" 264 "264" 263 "263" 262 "262" 261 "261" 260 "260" 259 "259" 258 "258" 257 "257" 256 "256" 255 "255" 254 "254" 253 "253" 252 "252" 251 "251" 250 "250" 249 "249" 248 "248" 247 "247" 246 "246" 245 "245" 244 "244" 243 "243" 242 "242" 241 "241" 240 "240" 239 "239" 238 "238" 237 "237" 236 "236" 235 "235" 234 "234" 233 "233" 232 "232" 231 "231" 230 "230" 229 "229" 228 "228" 227 "227" 226 "226" 225 "225" 224 "224" 223 "223" 222 "222" 221 "221" 220 "220" 219 "219" 218 "218" 217 "217" 216 "216" 215 "215" 214 "214" 213 "213" 212 "212" 211 "211" 210 "210" 209 "209" 208 "208" 207 "207" 206 "206" 205 "205" 204 "204" 203 "203" 202 "202" 201 "201" 200 "200" 199 "199" 198 "198" 197 "197" 196 "196" 195 "195" 194 "194" 193 "193" 192 "192" 191 "191" 190 "190" 189 "189" 188 "188" 187 "187" 186 "186" 185 "185" 184 "184" 183 "183" 182 "182" 181 "181" 180 "180" 179 "179" 178 "178" 177 "177" 176 "176" 175 "175" 174 "174" 173 "173" 172 "172" 171 "171" 170 "170" 169 "169" 168 "168" 167 "167" 166 "166" 165 "165" 164 "164" 163 "163" 162 "162" 161 "161" 160 "160" 159 "159" 158 "158" 157 "157" 156 "156" 155 "155" 154 "154" 153 "153" 152 "152" 151 "151" 150 "150" 149 "149" 148 "148" 147 "147" 146 "146" 145 "145" 144 "144" 143 "143" 142 "142" 141 "141" 140 "140" 139 "139" 138 "138" 137 "137" 136 "136" 135 "135" 134 "134" 133 "133" 132 "132" 131 "131" 130 "130" 129 "129" 128 "128" 127 "127" 126 "126" 125 "125" 124 "124" 123 "123" 122 "122" 121 "121" 120 "120" 119 "119" 118 "118" 117 "117" 116 "116" 115 "115" 114 "114" 113 "113" 112 "112" 111 "111" 110 "110" 109 "109" 108 "108" 107 "107" 106 "106" 105 "105" 104 "104" 103 "103" 102 "102" 101 "101" 100 "100" 99 "99" 98 "98" 97 "97" 96 "96" 95 "95" 94 "94" 93 "93" 92 "92" 91 "91" 90 "90" 89 "89" 88 "88" 87 "87" 86 "86" 85 "85" 84 "84" 83 "83" 82 "82" 81 "81" 80 "80" 79 "79" 78 "78" 77 "77" 76 "76" 75 "75" 74 "74" 73 "73" 72 "72" 71 "71" 70 "70" 69 "69" 68 "68" 67 "67" 66 "66" 65 "65" 64 "64" 63 "63" 62 "62" 61 "61" 60 "60" 59 "59" 58 "58" 57 "57" 56 "56" 55 "55" 54 "54" 53 "53" 52 "52" 51 "51" 50 "50" 49 "49" 48 "48" 47 "47" 46 "46" 45 "45" 44 "44" 43 "43" 42 "42" 41 "41" 40 "40" 39 "39" 38 "38" 37 "37" 36 "36" 35 "35" 34 "34" 33 "33" 32 "32" 31 "31" 30 "30" 29 "29" 28 "28" 27 "27" 26 "26" 25 "25" 24 "24" 23 "23" 22 "22" 21 "21" 20 "20" 19 "19" 18 "18" 17 "17" 16 "16" 15 "15" 14 "14" 13 "13" 12 "12" 11 "11" 10 "10" 9 "9" 8 "8" 7 "7" 6 "6" 5 "5" 4 "4" 3 "3" 2 "2" 1 "1" 0 "Unknown" ;
